VERSION ""

NS_ :

BS_:

BU_: FICM_FD Vector__XXX

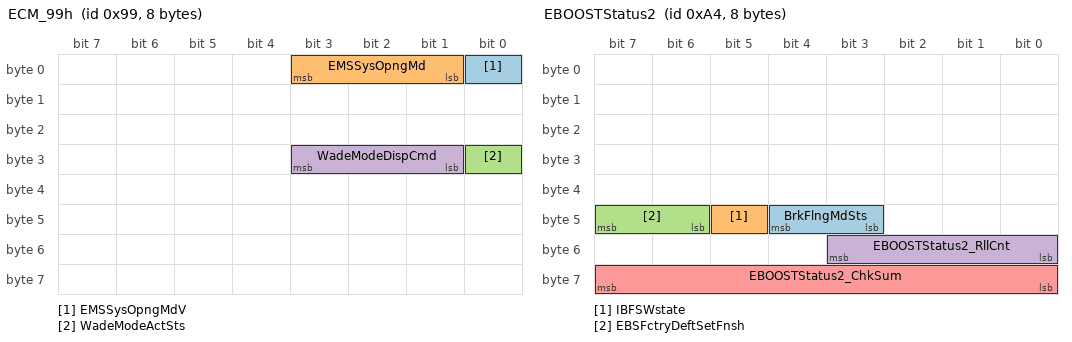
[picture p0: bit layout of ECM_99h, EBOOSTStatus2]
BO_ 153 ECM_99h: 8 Vector__XXX
 SG_ EMSSysOpngMdV : 0|1@0+ (1,0) [0|1] ""  FICM_FD
 SG_ EMSSysOpngMd : 3|3@0+ (1,0) [0|7] ""  FICM_FD
 SG_ WadeModeActSts : 24|1@0+ (1,0) [0|1] ""  FICM_FD
 SG_ WadeModeDispCmd : 27|3@0+ (1,0) [0|7] ""  FICM_FD

BO_ 164 EBOOSTStatus2: 8 Vector__XXX
 SG_ BrkFlngMdSts : 44|2@0+ (1,0) [0|3] ""  FICM_FD
 SG_ IBFSWstate : 45|1@0+ (1,0) [0|1] ""  FICM_FD
 SG_ EBSFctryDeftSetFnsh : 47|2@0+ (1,0) [0|3] ""  FICM_FD
 SG_ EBOOSTStatus2_RllCnt : 51|4@0+ (1,0) [0|15] ""  FICM_FD
 SG_ EBOOSTStatus2_ChkSum : 63|8@0+ (1,0) [0|255] ""  FICM_FD

BO_ 165 DrivenWheelPules: 16 Vector__XXX
 SG_ LDrvnWhlRotlDistPlsCtr : 23|10@0+ (1,0) [0|1023] ""  FICM_FD
 SG_ LDrvnWhlRotlDistPlsCtrV : 52|1@0+ (1,0) [0|1] ""  FICM_FD
 SG_ RDrvnWhlRotlDistPlsCtr : 87|10@0+ (1,0) [0|1023] ""  FICM_FD
 SG_ RDrvnWhlRotlDistPlsCtrV : 116|1@0+ (1,0) [0|1] ""  FICM_FD

BO_ 168 NonDrivenWheelPules: 16 Vector__XXX
 SG_ LNonDrvnWhlRotlDistPlsCtr : 23|10@0+ (1,0) [0|1023] ""  FICM_FD
 SG_ LNonDrvnWhlRotlDistPlsCtrV : 52|1@0+ (1,0) [0|1] ""  FICM_FD
 SG_ RNonDrvnWhlRotlDistPlsCtr : 87|10@0+ (1,0) [0|1023] ""  FICM_FD
 SG_ RNonDrvnWhlRotlDistPlsCtrV : 116|1@0+ (1,0) [0|1] ""  FICM_FD

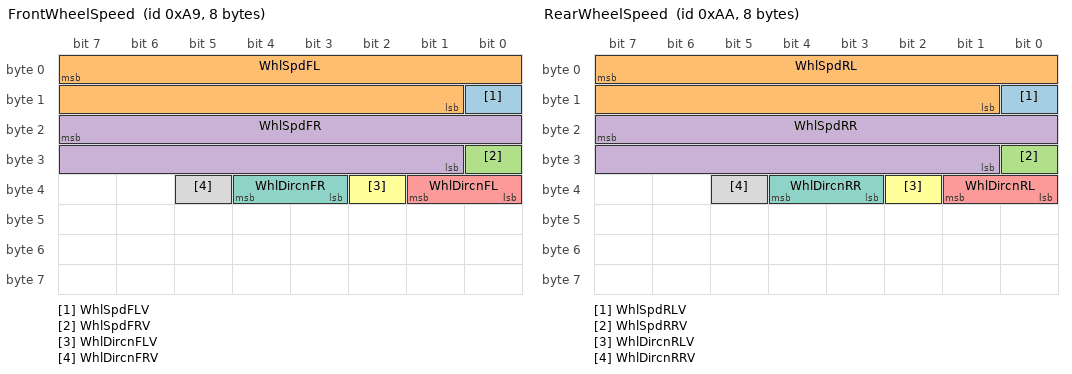
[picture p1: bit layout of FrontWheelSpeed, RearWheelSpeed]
BO_ 169 FrontWheelSpeed: 8 Vector__XXX
 SG_ WhlSpdFLV : 8|1@0+ (1,0) [0|1] ""  FICM_FD
 SG_ WhlSpdFL : 7|15@0+ (0.015625,0) [0|511.98] "km/h"  FICM_FD
 SG_ WhlSpdFRV : 24|1@0+ (1,0) [0|1] ""  FICM_FD
 SG_ WhlSpdFR : 23|15@0+ (0.015625,0) [0|511.98] "km/h"  FICM_FD
 SG_ WhlDircnFL : 33|2@0+ (1,0) [0|3] ""  FICM_FD
 SG_ WhlDircnFLV : 34|1@0+ (1,0) [0|1] ""  FICM_FD
 SG_ WhlDircnFR : 36|2@0+ (1,0) [0|3] ""  FICM_FD
 SG_ WhlDircnFRV : 37|1@0+ (1,0) [0|1] ""  FICM_FD

BO_ 170 RearWheelSpeed: 8 Vector__XXX
 SG_ WhlSpdRLV : 8|1@0+ (1,0) [0|1] ""  FICM_FD
 SG_ WhlSpdRL : 7|15@0+ (0.015625,0) [0|511.98] "km/h"  FICM_FD
 SG_ WhlSpdRRV : 24|1@0+ (1,0) [0|1] ""  FICM_FD
 SG_ WhlSpdRR : 23|15@0+ (0.015625,0) [0|511.98] "km/h"  FICM_FD
 SG_ WhlDircnRL : 33|2@0+ (1,0) [0|3] ""  FICM_FD
 SG_ WhlDircnRLV : 34|1@0+ (1,0) [0|1] ""  FICM_FD
 SG_ WhlDircnRR : 36|2@0+ (1,0) [0|3] ""  FICM_FD
 SG_ WhlDircnRRV : 37|1@0+ (1,0) [0|1] ""  FICM_FD

BO_ 337 TCCUShiftSys: 8 Vector__XXX
 SG_ TCCUSysOpngMd : 6|4@0+ (1,0) [0|15] ""  FICM_FD

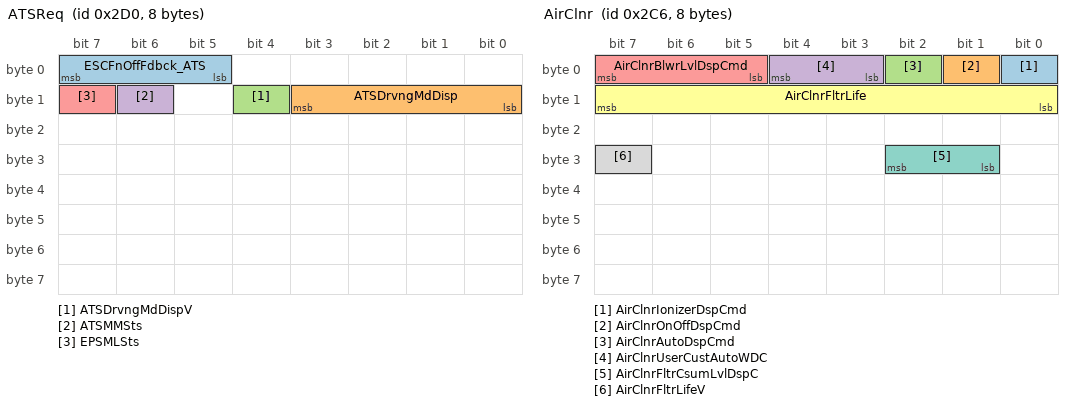
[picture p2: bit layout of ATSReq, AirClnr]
BO_ 720 ATSReq: 8 Vector__XXX
 SG_ ESCFnOffFdbck_ATS : 7|3@0+ (1,0) [0|7] ""  FICM_FD
 SG_ ATSDrvngMdDisp : 11|4@0+ (1,0) [0|15] ""  FICM_FD
 SG_ ATSDrvngMdDispV : 12|1@0+ (1,0) [0|1] ""  FICM_FD
 SG_ ATSMMSts : 14|1@0+ (1,0) [0|1] ""  FICM_FD
 SG_ EPSMLSts : 15|1@0+ (1,0) [0|1] ""  FICM_FD

BO_ 710 AirClnr: 8 Vector__XXX
 SG_ AirClnrIonizerDspCmd : 0|1@0+ (1,0) [0|1] ""  FICM_FD
 SG_ AirClnrOnOffDspCmd : 1|1@0+ (1,0) [0|1] ""  FICM_FD
 SG_ AirClnrAutoDspCmd : 2|1@0+ (1,0) [0|1] ""  FICM_FD
 SG_ AirClnrUserCustAutoWDC : 4|2@0+ (1,0) [0|3] ""  FICM_FD
 SG_ AirClnrBlwrLvlDspCmd : 7|3@0+ (1,0) [0|7] ""  FICM_FD
 SG_ AirClnrFltrLife : 15|8@0+ (3,0) [0|765] "h"  FICM_FD
 SG_ AirClnrFltrCsumLvlDspC : 26|2@0+ (1,0) [0|3] ""  FICM_FD
 SG_ AirClnrFltrLifeV : 31|1@0+ (1,0) [0|1] ""  FICM_FD

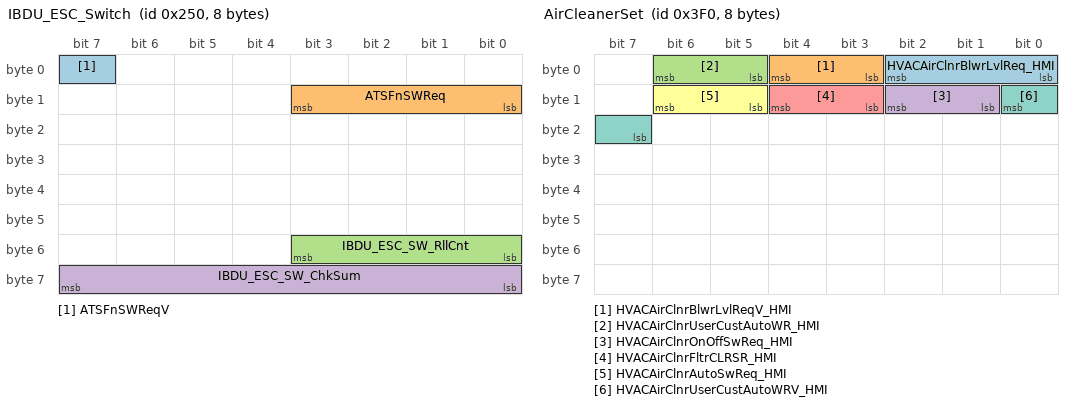
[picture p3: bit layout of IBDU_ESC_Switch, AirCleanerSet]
BO_ 592 IBDU_ESC_Switch: 8 Vector__XXX
 SG_ ATSFnSWReqV : 7|1@0+ (1,0) [0|1] ""  FICM_FD
 SG_ ATSFnSWReq : 11|4@0+ (1,0) [0|15] ""  FICM_FD
 SG_ IBDU_ESC_SW_RllCnt : 51|4@0+ (1,0) [0|15] ""  FICM_FD
 SG_ IBDU_ESC_SW_ChkSum : 63|8@0+ (1,0) [0|255] ""  FICM_FD

BO_ 1008 AirCleanerSet: 8 FICM_FD
 SG_ HVACAirClnrBlwrLvlReq_HMI : 2|3@0+ (1,0) [0|7] ""  Vector__XXX
 SG_ HVACAirClnrBlwrLvlReqV_HMI : 4|2@0+ (1,0) [0|3] ""  Vector__XXX
 SG_ HVACAirClnrUserCustAutoWR_HMI : 6|2@0+ (1,0) [0|3] ""  Vector__XXX
 SG_ HVACAirClnrOnOffSwReq_HMI : 10|2@0+ (1,0) [0|3] ""  Vector__XXX
 SG_ HVACAirClnrFltrCLRSR_HMI : 12|2@0+ (1,0) [0|3] ""  Vector__XXX
 SG_ HVACAirClnrAutoSwReq_HMI : 14|2@0+ (1,0) [0|3] ""  Vector__XXX
 SG_ HVACAirClnrUserCustAutoWRV_HMI : 8|2@0+ (1,0) [0|3] ""  Vector__XXX

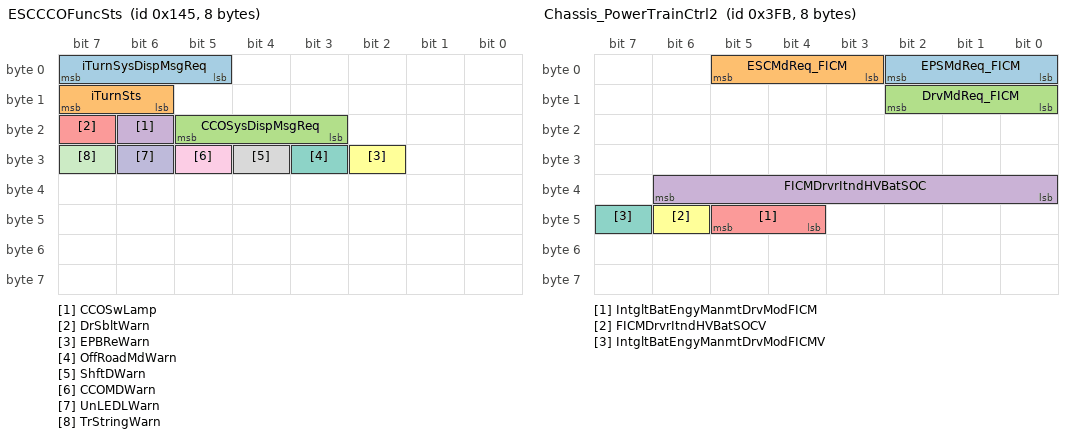
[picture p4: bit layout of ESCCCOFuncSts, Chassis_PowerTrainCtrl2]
BO_ 325 ESCCCOFuncSts: 8 Vector__XXX
 SG_ iTurnSysDispMsgReq : 7|3@0+ (1,0) [0|7] ""  FICM_FD
 SG_ iTurnSts : 15|2@0+ (1,0) [0|1] ""  FICM_FD
 SG_ CCOSysDispMsgReq : 21|3@0+ (1,0) [0|7] ""  FICM_FD
 SG_ CCOSwLamp : 22|1@0+ (1,0) [0|1] ""  FICM_FD
 SG_ DrSbltWarn : 23|1@0+ (1,0) [0|1] ""  FICM_FD
 SG_ EPBReWarn : 26|1@0+ (1,0) [0|1] ""  FICM_FD
 SG_ OffRoadMdWarn : 27|1@0+ (1,0) [0|1] ""  FICM_FD
 SG_ ShftDWarn : 28|1@0+ (1,0) [0|1] ""  FICM_FD
 SG_ CCOMDWarn : 29|1@0+ (1,0) [0|1] ""  FICM_FD
 SG_ UnLEDLWarn : 30|1@0+ (1,0) [0|1] ""  FICM_FD
 SG_ TrStringWarn : 31|1@0+ (1,0) [0|1] ""  FICM_FD

BO_ 1019 Chassis_PowerTrainCtrl2: 8 FICM_FD
 SG_ EPSMdReq_FICM : 2|3@0+ (1,0) [0|7] ""  Vector__XXX
 SG_ ESCMdReq_FICM : 5|3@0+ (1,0) [0|7] ""  Vector__XXX
 SG_ DrvMdReq_FICM : 10|3@0+ (1,0) [0|7] ""  Vector__XXX
 SG_ FICMDrvrItndHVBatSOC : 38|7@0+ (1,0) [0|100] "%"  Vector__XXX
 SG_ IntgltBatEngyManmtDrvModFICM : 45|2@0+ (1,0) [0|3] ""  Vector__XXX
 SG_ FICMDrvrItndHVBatSOCV : 46|1@0+ (1,0) [0|1] ""  Vector__XXX
 SG_ IntgltBatEngyManmtDrvModFICMV : 47|1@0+ (1,0) [0|1] ""  Vector__XXX

BO_ 1021 BatHeatOrdReq: 8 FICM_FD
 SG_ FICMHourOfBatHeat : 4|5@0+ (1,0) [0|23] ""  Vector__XXX
 SG_ FICMHeatReq : 6|2@0+ (1,0) [0|3] ""  Vector__XXX
 SG_ FICMBatHeatTmV : 7|1@0+ (1,0) [0|1] ""  Vector__XXX
 SG_ FICMMinOfBatHeat : 13|6@0+ (1,0) [0|63] ""  Vector__XXX
 SG_ FICMInnerV2LReq : 15|2@0+ (1,0) [0|3] ""  Vector__XXX
 SG_ FICMInnerV2LKeepTimeReq : 20|5@0+ (1,0) [0|31] "h"  Vector__XXX
 SG_ FuelModSw : 23|2@0+ (1,0) [0|3] ""  Vector__XXX
 SG_ FICMPeriodOfBatHeatSunday : 24|1@0+ (1,0) [0|1] ""  Vector__XXX
 SG_ FICMPeriodOfBatHeatMonday : 25|1@0+ (1,0) [0|1] ""  Vector__XXX
 SG_ FICMPeriodOfBatHeatTuesday : 26|1@0+ (1,0) [0|1] ""  Vector__XXX
 SG_ FICMPeriodOfBatHeatWednesday : 27|1@0+ (1,0) [0|1] ""  Vector__XXX
 SG_ FICMPeriodOfBatHeatThursday : 28|1@0+ (1,0) [0|1] ""  Vector__XXX
 SG_ FICMPeriodOfBatHeatFriday : 29|1@0+ (1,0) [0|1] ""  Vector__XXX
 SG_ FICMPeriodOfBatHeatSaturday : 30|1@0+ (1,0) [0|1] ""  Vector__XXX
 SG_ FICMPeriodOfBatHeatRepeat : 31|1@0+ (1,0) [0|1] ""  Vector__XXX
 SG_ FICMHourOfBatHeat1 : 36|5@0+ (1,0) [0|23] ""  Vector__XXX
 SG_ FICMHeatReq1 : 38|2@0+ (1,0) [0|3] ""  Vector__XXX
 SG_ FICMBatHeatTmV1 : 39|1@0+ (1,0) [0|1] ""  Vector__XXX
 SG_ FICMMinOfBatHeat1 : 45|6@0+ (1,0) [0|63] ""  Vector__XXX
 SG_ EnStrtRequest_V2L : 47|2@0+ (1,0) [0|3] ""  Vector__XXX
 SG_ FICMV2XSpSOCReqExt : 54|7@0+ (1,0) [0|100] "%"  Vector__XXX
 SG_ FICMPeriodOfBatHeatSunday1 : 56|1@0+ (1,0) [0|1] ""  Vector__XXX
 SG_ FICMPeriodOfBatHeatMonday1 : 57|1@0+ (1,0) [0|1] ""  Vector__XXX
 SG_ FICMPeriodOfBatHeatTuesday1 : 58|1@0+ (1,0) [0|1] ""  Vector__XXX
 SG_ FICMPeriodOfBatHeatWednesday1 : 59|1@0+ (1,0) [0|1] ""  Vector__XXX
 SG_ FICMPeriodOfBatHeatThursday1 : 60|1@0+ (1,0) [0|1] ""  Vector__XXX
 SG_ FICMPeriodOfBatHeatFriday1 : 61|1@0+ (1,0) [0|1] ""  Vector__XXX
 SG_ FICMPeriodOfBatHeatSaturday1 : 62|1@0+ (1,0) [0|1] ""  Vector__XXX
 SG_ FICMPeriodOfBatHeatRepeat1 : 63|1@0+ (1,0) [0|1] ""  Vector__XXX

BO_ 1022 BatHeatOrdStatus: 8 Vector__XXX
 SG_ ICGMHourOfBatHeat : 4|5@0+ (1,0) [0|31] ""  FICM_FD
 SG_ BatHeatOrdStatus : 5|1@0+ (1,0) [0|1] ""  FICM_FD
 SG_ ICGMMinOfBatHeat : 13|6@0+ (1,0) [0|63] ""  FICM_FD
 SG_ ICGMPeriodOfBatHeatSunday : 24|1@0+ (1,0) [0|1] ""  FICM_FD
 SG_ ICGMPeriodOfBatHeatMonday : 25|1@0+ (1,0) [0|1] ""  FICM_FD
 SG_ ICGMPeriodOfBatHeatTuesday : 26|1@0+ (1,0) [0|1] ""  FICM_FD
 SG_ ICGMPeriodOfBatHeatWednesday : 27|1@0+ (1,0) [0|1] ""  FICM_FD
 SG_ ICGMPeriodOfBatHeatThursday : 28|1@0+ (1,0) [0|1] ""  FICM_FD
 SG_ ICGMPeriodOfBatHeatFriday : 29|1@0+ (1,0) [0|1] ""  FICM_FD
 SG_ ICGMPeriodOfBatHeatSaturday : 30|1@0+ (1,0) [0|1] ""  FICM_FD
 SG_ ICGMPeriodOfBatHeatRepeat : 31|1@0+ (1,0) [0|1] ""  FICM_FD
 SG_ ICGMHourOfBatHeat1 : 36|5@0+ (1,0) [0|31] ""  FICM_FD
 SG_ BatHeatOrdStatus1 : 37|1@0+ (1,0) [0|1] ""  FICM_FD
 SG_ ICGMMinOfBatHeat1 : 45|6@0+ (1,0) [0|63] ""  FICM_FD
 SG_ ICGMPeriodOfBatHeatSunday1 : 56|1@0+ (1,0) [0|1] ""  FICM_FD
 SG_ ICGMPeriodOfBatHeatMonday1 : 57|1@0+ (1,0) [0|1] ""  FICM_FD
 SG_ ICGMPeriodOfBatHeatTuesday1 : 58|1@0+ (1,0) [0|1] ""  FICM_FD
 SG_ ICGMPeriodOfBatHeatWednesday1 : 59|1@0+ (1,0) [0|1] ""  FICM_FD
 SG_ ICGMPeriodOfBatHeatThursday1 : 60|1@0+ (1,0) [0|1] ""  FICM_FD
 SG_ ICGMPeriodOfBatHeatFriday1 : 61|1@0+ (1,0) [0|1] ""  FICM_FD
 SG_ ICGMPeriodOfBatHeatSaturday1 : 62|1@0+ (1,0) [0|1] ""  FICM_FD
 SG_ ICGMPeriodOfBatHeatRepeat1 : 63|1@0+ (1,0) [0|1] ""  FICM_FD

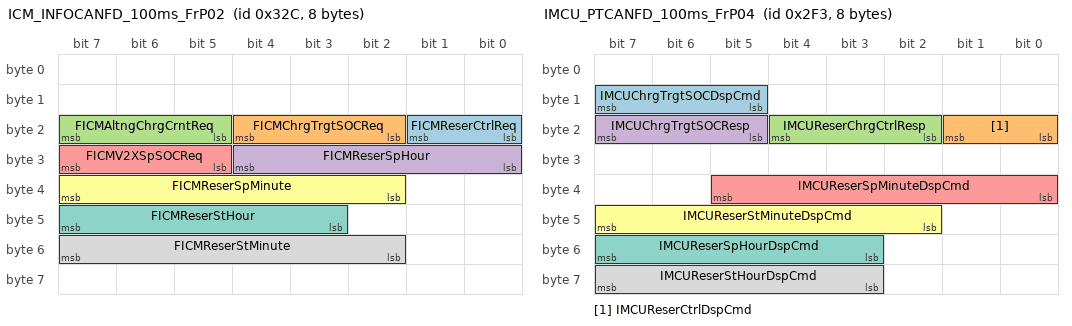
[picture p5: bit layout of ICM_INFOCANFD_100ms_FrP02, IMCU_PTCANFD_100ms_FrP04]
BO_ 812 ICM_INFOCANFD_100ms_FrP02: 8 FICM_FD
 SG_ FICMReserCtrlReq : 17|2@0+ (1,0) [0|3] ""  Vector__XXX
 SG_ FICMChrgTrgtSOCReq : 20|3@0+ (1,0) [0|7] ""  Vector__XXX
 SG_ FICMAltngChrgCrntReq : 23|3@0+ (1,0) [0|7] ""  Vector__XXX
 SG_ FICMReserSpHour : 28|5@0+ (1,0) [0|31] ""  Vector__XXX
 SG_ FICMV2XSpSOCReq : 31|3@0+ (1,0) [0|7] ""  Vector__XXX
 SG_ FICMReserSpMinute : 39|6@0+ (1,0) [0|63] ""  Vector__XXX
 SG_ FICMReserStHour : 47|5@0+ (1,0) [0|31] ""  Vector__XXX
 SG_ FICMReserStMinute : 55|6@0+ (1,0) [0|63] ""  Vector__XXX

BO_ 704 IMCU_PTCANFD_50ms_FrP01: 8 Vector__XXX
 SG_ IMCUBaaSOvduDay : 7|16@0+ (1,0) [0|65535] "NULL"  FICM_FD
 SG_ BaaSBatIlglAlrm : 18|1@0+ (1,0) [0|1] "NULL"  FICM_FD
 SG_ IMCUAlrmDspForBaaS : 23|4@0+ (1,0) [0|15] "NULL"  FICM_FD

BO_ 755 IMCU_PTCANFD_100ms_FrP04: 8 Vector__XXX
 SG_ IMCUChrgTrgtSOCDspCmd : 15|3@0+ (1,0) [0|7] "NULL"  FICM_FD
 SG_ IMCUReserCtrlDspCmd : 17|2@0+ (1,0) [0|3] "NULL"  FICM_FD
 SG_ IMCUReserChrgCtrlResp : 20|3@0+ (1,0) [0|7] "NULL"  FICM_FD
 SG_ IMCUChrgTrgtSOCResp : 23|3@0+ (1,0) [0|7] "NULL"  FICM_FD
 SG_ IMCUReserSpMinuteDspCmd : 37|6@0+ (1,0) [0|59] "NULL"  FICM_FD
 SG_ IMCUReserStMinuteDspCmd : 47|6@0+ (1,0) [0|59] "NULL"  FICM_FD
 SG_ IMCUReserSpHourDspCmd : 55|5@0+ (1,0) [0|23] "NULL"  FICM_FD
 SG_ IMCUReserStHourDspCmd : 63|5@0+ (1,0) [0|23] "NULL"  FICM_FD

BO_ 777 CCU_100ms_PDU02: 8 Vector__XXX
 SG_ CCUOffBdChrgrPlugOnV : 62|1@0+ (1,0) [0|1] "NULL"  FICM_FD
 SG_ CCUOffBdChrgrPlugOn : 48|2@0+ (1,0) [0|3] "NULL"  FICM_FD

BO_ 805 IMCU_PTCANFD_100ms_FrP02: 16 Vector__XXX
 SG_ IMCUDschrgngEstdElecRngV : 27|1@0+ (1,0) [0|1] "NULL"  FICM_FD
 SG_ IMCUDschrgngEstdElecRng : 23|12@0+ (1,0) [0|4095] "kM"  FICM_FD
 SG_ IMCUChrgSttnMchngStaResp : 81|2@0+ (1,0) [0|3] "NULL"  FICM_FD
 SG_ IMCUAltngChrgCrntResp : 84|3@0+ (1,0) [0|7] "NULL"  FICM_FD
 SG_ IMCUAltngChrgCrntDspCmd : 87|3@0+ (1,0) [0|7] "NULL"  FICM_FD
 SG_ IMCUDschrgTrgtSOCDspCmd : 95|3@0+ (1,0) [0|7] "NULL"  FICM_FD

BO_ 884 IMCU_PTCANFD_100ms_FrP19: 8 Vector__XXX
 SG_ ESSSwapOpDsp : 27|4@0+ (1,0) [0|15] "NULL"  FICM_FD

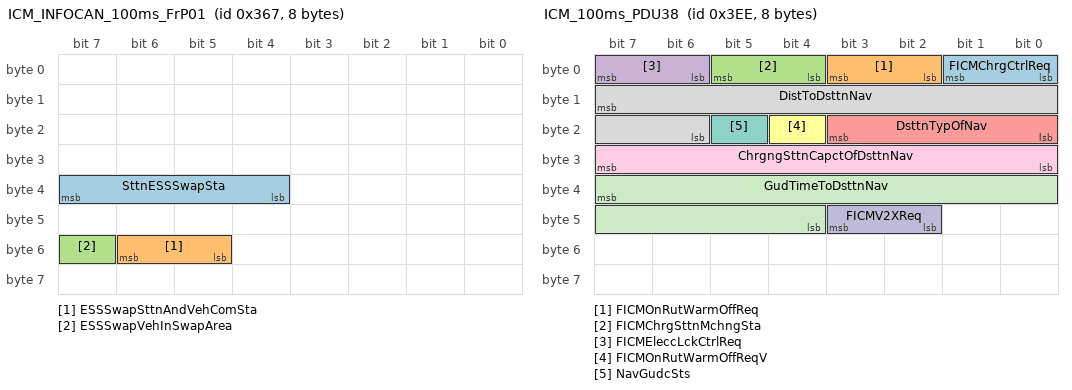
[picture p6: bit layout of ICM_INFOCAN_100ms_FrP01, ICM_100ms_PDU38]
BO_ 871 ICM_INFOCAN_100ms_FrP01: 8 Vector__XXX
 SG_ SttnESSSwapSta : 39|4@0+ (1,0) [0|15] "NULL"  FICM_FD
 SG_ ESSSwapSttnAndVehComSta : 54|2@0+ (1,0) [0|3] "NULL"  FICM_FD
 SG_ ESSSwapVehInSwapArea : 55|1@0+ (1,0) [0|1] "NULL"  FICM_FD

BO_ 1006 ICM_100ms_PDU38: 8 FICM_FD
 SG_ FICMChrgCtrlReq : 1|2@0+ (1,0) [0|3] ""  Vector__XXX
 SG_ FICMOnRutWarmOffReq : 3|2@0+ (1,0) [0|3] ""  Vector__XXX
 SG_ FICMChrgSttnMchngSta : 5|2@0+ (1,0) [0|3] ""  Vector__XXX
 SG_ FICMEleccLckCtrlReq : 7|2@0+ (1,0) [0|3] ""  Vector__XXX
 SG_ DsttnTypOfNav : 19|4@0+ (1,0) [0|2] ""  Vector__XXX
 SG_ FICMOnRutWarmOffReqV : 20|1@0+ (1,0) [0|1] ""  Vector__XXX
 SG_ NavGudcSts : 21|1@0+ (1,0) [0|1] ""  Vector__XXX
 SG_ DistToDsttnNav : 15|10@0+ (0.1,0) [0|102.3] "km"  Vector__XXX
 SG_ ChrgngSttnCapctOfDsttnNav : 31|8@0+ (4,0) [0|1020] "kW"  Vector__XXX
 SG_ FICMV2XReq : 43|2@0+ (1,0) [0|3] "NULL"  Vector__XXX
 SG_ GudTimeToDsttnNav : 39|12@0+ (1,0) [0|4095] "Min"  Vector__XXX

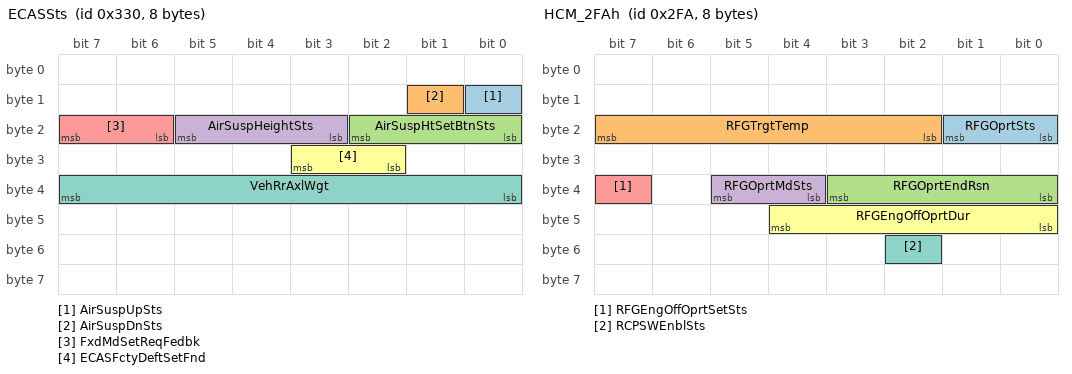
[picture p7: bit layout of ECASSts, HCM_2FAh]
BO_ 816 ECASSts: 8 Vector__XXX
 SG_ AirSuspUpSts : 8|1@0+ (1,0) [0|1] ""  FICM_FD
 SG_ AirSuspDnSts : 9|1@0+ (1,0) [0|1] ""  FICM_FD
 SG_ AirSuspHtSetBtnSts : 18|3@0+ (1,0) [0|7] ""  FICM_FD
 SG_ AirSuspHeightSts : 21|3@0+ (1,0) [0|7] ""  FICM_FD
 SG_ FxdMdSetReqFedbk : 23|2@0+ (1,0) [0|3] ""  FICM_FD
 SG_ ECASFctyDeftSetFnd : 27|2@0+ (1,0) [0|3] ""  FICM_FD
 SG_ VehRrAxlWgt : 39|8@0+ (7,800) [800|2585] "kg"  FICM_FD

BO_ 762 HCM_2FAh: 8 Vector__XXX
 SG_ RFGOprtSts : 17|2@0+ (1,0) [0|3] ""  FICM_FD
 SG_ RFGTrgtTemp : 23|6@0+ (1,0) [0|63] "℃"  FICM_FD
 SG_ RFGOprtEndRsn : 35|4@0+ (1,0) [0|15] ""  FICM_FD
 SG_ RFGOprtMdSts : 37|2@0+ (1,0) [0|3] ""  FICM_FD
 SG_ RFGEngOffOprtSetSts : 39|1@0+ (1,0) [0|1] ""  FICM_FD
 SG_ RFGEngOffOprtDur : 44|5@0+ (1,0) [0|31] "h"  FICM_FD
 SG_ RCPSWEnblSts : 50|1@0+ (1,0) [0|1] ""  FICM_FD

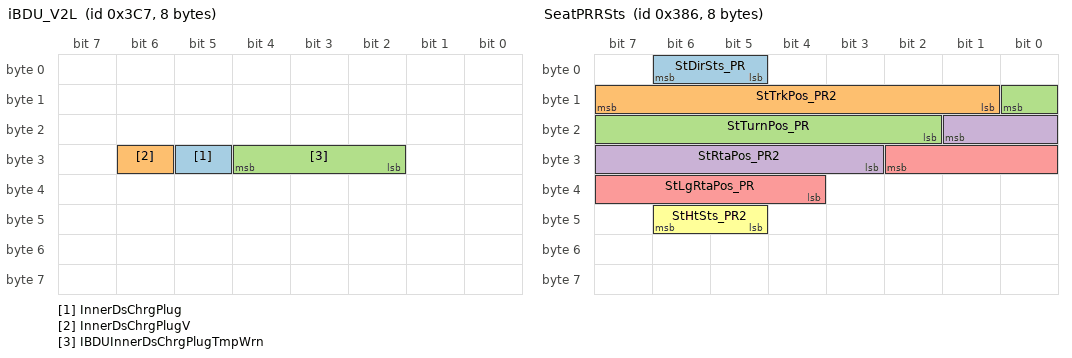
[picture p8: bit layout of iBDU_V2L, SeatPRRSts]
BO_ 967 iBDU_V2L: 8 Vector__XXX
 SG_ InnerDsChrgPlug : 29|1@0+ (1,0) [0|1] ""  FICM_FD
 SG_ InnerDsChrgPlugV : 30|1@0+ (1,0) [0|1] ""  FICM_FD
 SG_ IBDUInnerDsChrgPlugTmpWrn : 28|3@0+ (1,0) [0|7] ""  FICM_FD

BO_ 994 TyrePrs_Temp2: 8 Vector__XXX
 SG_ TirePrs_RLOS : 23|8@0+ (2.75,0) [0|700] "kpa"  FICM_FD
 SG_ TirePrs_RROS : 31|8@0+ (2.75,0) [0|700] "kpa"  FICM_FD
 SG_ TireTmp_RLOS : 55|8@0+ (1,-60) [-60|194] ""  FICM_FD
 SG_ TireTmp_RROS : 63|8@0+ (1,-60) [-60|194] ""  FICM_FD

BO_ 902 SeatPRRSts: 8 Vector__XXX
 SG_ StDirSts_PR : 6|2@0+ (1,0) [0|3] ""  FICM_FD
 SG_ StTrkPos_PR2 : 15|7@0+ (1,0) [0|127] "%"  FICM_FD
 SG_ StTurnPos_PR : 8|7@0+ (1,0) [0|127] "%"  FICM_FD
 SG_ StRtaPos_PR2 : 17|7@0+ (1,0) [0|127] "%"  FICM_FD
 SG_ StLgRtaPos_PR : 26|7@0+ (1,0) [0|127] "%"  FICM_FD
 SG_ StHtSts_PR2 : 46|2@0+ (1,0) [0|3] ""  FICM_FD

BO_ 903 AllSeatAdjust4: 8 Vector__XXX
 SG_ StRtaRmndReq_PR : 2|3@0+ (1,0) [0|7] ""  FICM_FD

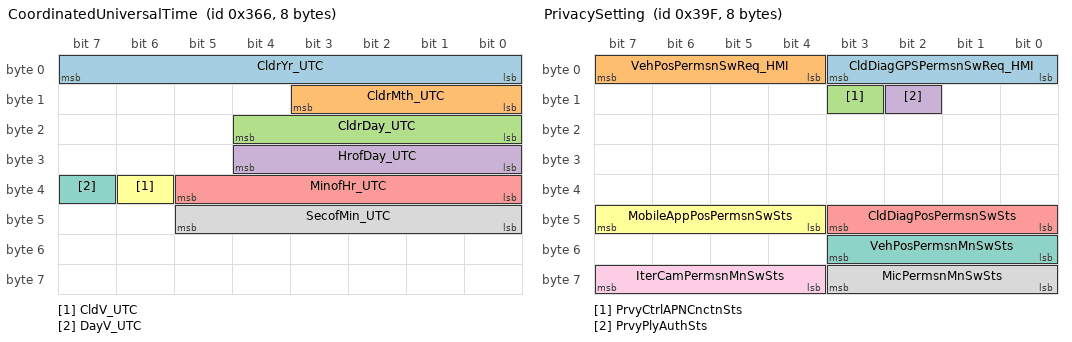
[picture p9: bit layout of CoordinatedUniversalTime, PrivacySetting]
BO_ 870 CoordinatedUniversalTime: 8 Vector__XXX
 SG_ CldrYr_UTC : 7|8@0+ (1,2000) [2000|2255] ""  FICM_FD
 SG_ CldrMth_UTC : 11|4@0+ (1,0) [0|12] ""  FICM_FD
 SG_ CldrDay_UTC : 20|5@0+ (1,0) [0|31] ""  FICM_FD
 SG_ HrofDay_UTC : 28|5@0+ (1,0) [0|23] ""  FICM_FD
 SG_ MinofHr_UTC : 37|6@0+ (1,0) [0|63] ""  FICM_FD
 SG_ CldV_UTC : 38|1@0+ (1,0) [0|1] ""  FICM_FD
 SG_ DayV_UTC : 39|1@0+ (1,0) [0|1] ""  FICM_FD
 SG_ SecofMin_UTC : 45|6@0+ (1,0) [0|63] ""  FICM_FD

BO_ 927 PrivacySetting: 8 FICM_FD
 SG_ CldDiagGPSPermsnSwReq_HMI : 3|4@0+ (1,0) [0|15] ""  Vector__XXX
 SG_ VehPosPermsnSwReq_HMI : 7|4@0+ (1,0) [0|15] ""  Vector__XXX
 SG_ PrvyCtrlAPNCnctnSts : 11|1@0+ (1,0) [0|1] ""  Vector__XXX
 SG_ PrvyPlyAuthSts : 10|1@0+ (1,0) [0|1] ""  Vector__XXX
 SG_ CldDiagPosPermsnSwSts : 43|4@0+ (1,0) [0|15] ""  Vector__XXX
 SG_ MobileAppPosPermsnSwSts : 47|4@0+ (1,0) [0|15] ""  Vector__XXX
 SG_ VehPosPermsnMnSwSts : 51|4@0+ (1,0) [0|15] ""  Vector__XXX
 SG_ MicPermsnMnSwSts : 59|4@0+ (1,0) [0|15] ""  Vector__XXX
 SG_ IterCamPermsnMnSwSts : 63|4@0+ (1,0) [0|15] ""  Vector__XXX

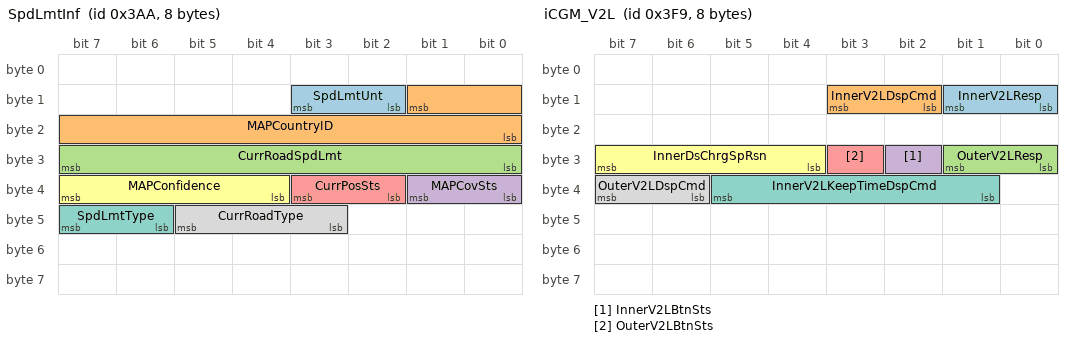
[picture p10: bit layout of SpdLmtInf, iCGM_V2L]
BO_ 938 SpdLmtInf: 8 FICM_FD
 SG_ SpdLmtUnt : 11|2@0+ (1,0) [0|3] ""  Vector__XXX
 SG_ MAPCountryID : 9|10@0+ (1,0) [0|1023] ""  Vector__XXX
 SG_ CurrRoadSpdLmt : 31|8@0+ (1,0) [0|255] ""  Vector__XXX
 SG_ MAPCovSts : 33|2@0+ (1,0) [0|3] ""  Vector__XXX
 SG_ CurrPosSts : 35|2@0+ (1,0) [0|3] ""  Vector__XXX
 SG_ MAPConfidence : 39|4@0+ (1,0) [0|15] ""  Vector__XXX
 SG_ SpdLmtType : 47|2@0+ (1,0) [0|3] ""  Vector__XXX
 SG_ CurrRoadType : 45|3@0+ (1,0) [0|7] ""  Vector__XXX

BO_ 939 SeatCtrl_DR_HMI: 32 FICM_FD
 SG_ StTrkPosReq_DR_HMI : 54|7@0+ (1,0) [0|127] ""  Vector__XXX
 SG_ StRtaPosReq_DR_HMI : 62|7@0+ (1,0) [0|127] ""  Vector__XXX

BO_ 1017 iCGM_V2L: 8 Vector__XXX
 SG_ InnerV2LResp : 9|2@0+ (1,0) [0|3] ""  FICM_FD
 SG_ InnerV2LDspCmd : 11|2@0+ (1,0) [0|3] ""  FICM_FD
 SG_ OuterV2LResp : 25|2@0+ (1,0) [0|3] ""  FICM_FD
 SG_ InnerV2LBtnSts : 26|1@0+ (1,0) [0|1] ""  FICM_FD
 SG_ OuterV2LBtnSts : 27|1@0+ (1,0) [0|1] ""  FICM_FD
 SG_ InnerDsChrgSpRsn : 31|4@0+ (1,0) [0|15] ""  FICM_FD
 SG_ InnerV2LKeepTimeDspCmd : 37|5@0+ (1,0) [0|31] "h"  FICM_FD
 SG_ OuterV2LDspCmd : 39|2@0+ (1,0) [0|3] ""  FICM_FD

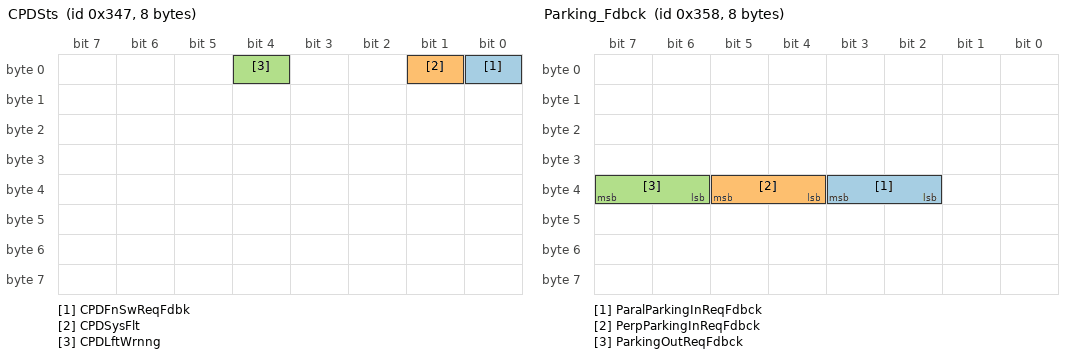
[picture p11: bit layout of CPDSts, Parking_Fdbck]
BO_ 839 CPDSts: 8 Vector__XXX
 SG_ CPDFnSwReqFdbk : 0|1@0+ (1,0) [0|1] ""  FICM_FD
 SG_ CPDSysFlt : 1|1@0+ (1,0) [0|1] ""  FICM_FD
 SG_ CPDLftWrnng : 4|1@0+ (1,0) [0|1] ""  FICM_FD

BO_ 856 Parking_Fdbck: 8 Vector__XXX
 SG_ ParalParkingInReqFdbck : 35|2@0+ (1,0) [0|3] ""  FICM_FD
 SG_ PerpParkingInReqFdbck : 37|2@0+ (1,0) [0|3] ""  FICM_FD
 SG_ ParkingOutReqFdbck : 39|2@0+ (1,0) [0|3] ""  FICM_FD

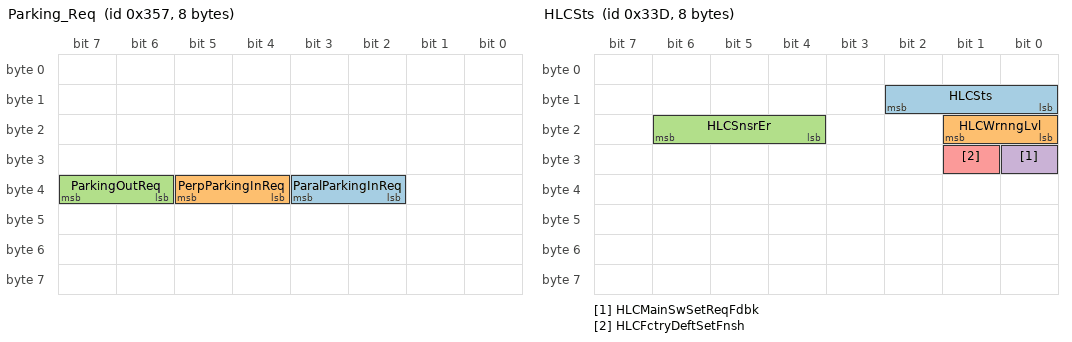
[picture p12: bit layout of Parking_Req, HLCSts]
BO_ 855 Parking_Req: 8 FICM_FD
 SG_ ParalParkingInReq : 35|2@0+ (1,0) [0|3] ""  Vector__XXX
 SG_ PerpParkingInReq : 37|2@0+ (1,0) [0|3] ""  Vector__XXX
 SG_ ParkingOutReq : 39|2@0+ (1,0) [0|3] ""  Vector__XXX

BO_ 829 HLCSts: 8 Vector__XXX
 SG_ HLCSts : 10|3@0+ (1,0) [0|7] ""  FICM_FD
 SG_ HLCWrnngLvl : 17|2@0+ (1,0) [0|3] ""  FICM_FD
 SG_ HLCSnsrEr : 22|3@0+ (1,0) [0|7] ""  FICM_FD
 SG_ HLCMainSwSetReqFdbk : 24|1@0+ (1,0) [0|1] ""  FICM_FD
 SG_ HLCFctryDeftSetFnsh : 25|1@0+ (1,0) [0|1] ""  FICM_FD

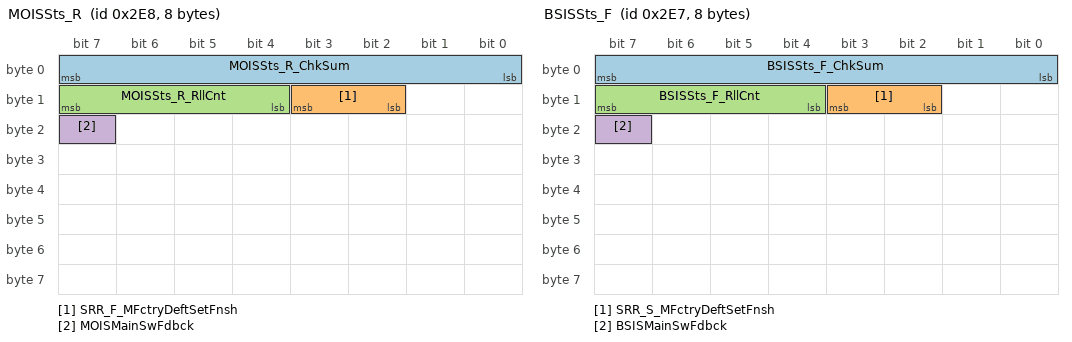
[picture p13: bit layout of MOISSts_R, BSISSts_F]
BO_ 744 MOISSts_R: 8 Vector__XXX
 SG_ MOISSts_R_ChkSum : 7|8@0+ (1,0) [0|255] ""  FICM_FD
 SG_ SRR_F_MFctryDeftSetFnsh : 11|2@0+ (1,0) [0|3] ""  FICM_FD
 SG_ MOISSts_R_RllCnt : 15|4@0+ (1,0) [0|15] ""  FICM_FD
 SG_ MOISMainSwFdbck : 23|1@0+ (1,0) [0|1] ""  FICM_FD

BO_ 743 BSISSts_F: 8 Vector__XXX
 SG_ BSISSts_F_ChkSum : 7|8@0+ (1,0) [0|255] ""  FICM_FD
 SG_ SRR_S_MFctryDeftSetFnsh : 11|2@0+ (1,0) [0|3] ""  FICM_FD
 SG_ BSISSts_F_RllCnt : 15|4@0+ (1,0) [0|15] ""  FICM_FD
 SG_ BSISMainSwFdbck : 23|1@0+ (1,0) [0|1] ""  FICM_FD

BO_ 1376 LDU_Lds_560h: 8 Vector__XXX
 SG_ DcrtvLmpSwSts : 28|1@0+ (1,0) [0|1] ""  FICM_FD

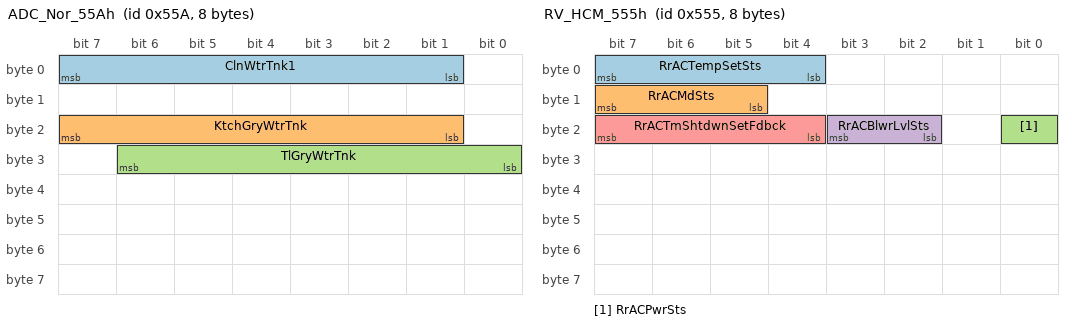
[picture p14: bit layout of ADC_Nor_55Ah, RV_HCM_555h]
BO_ 1370 ADC_Nor_55Ah: 8 Vector__XXX
 SG_ ClnWtrTnk1 : 7|7@0+ (1,0) [0|100] "%"  FICM_FD
 SG_ KtchGryWtrTnk : 23|7@0+ (1,0) [0|100] "%"  FICM_FD
 SG_ TlGryWtrTnk : 30|7@0+ (1,0) [0|100] "%"  FICM_FD

BO_ 1365 RV_HCM_555h: 8 Vector__XXX
 SG_ RrACTempSetSts : 7|4@0+ (1,17) [17|30] "℃"  FICM_FD
 SG_ RrACMdSts : 15|3@0+ (1,0) [0|7] ""  FICM_FD
 SG_ RrACPwrSts : 16|1@0+ (1,0) [0|1] ""  FICM_FD
 SG_ RrACBlwrLvlSts : 19|2@0+ (1,0) [0|3] ""  FICM_FD
 SG_ RrACTmShtdwnSetFdbck : 23|4@0+ (1,0) [0|15] ""  FICM_FD

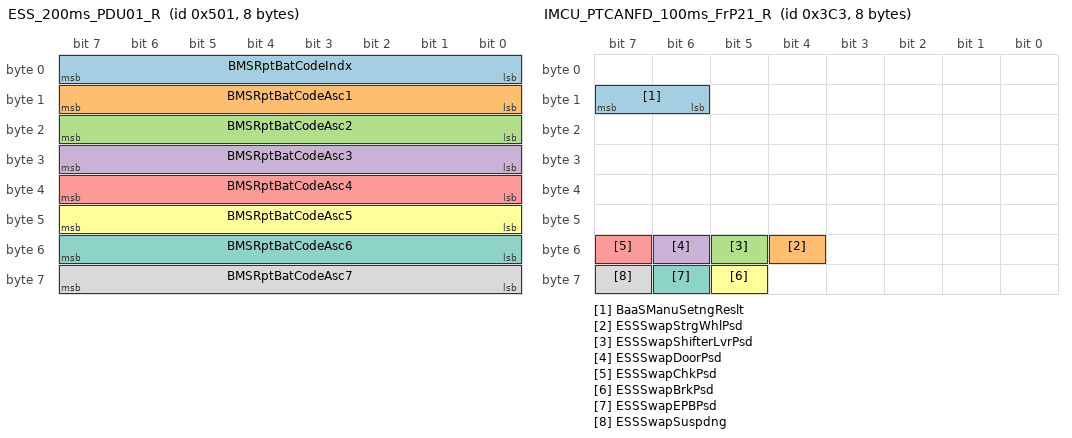
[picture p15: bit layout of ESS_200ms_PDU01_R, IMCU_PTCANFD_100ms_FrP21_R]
BO_ 1281 ESS_200ms_PDU01_R: 8 Vector__XXX
 SG_ BMSRptBatCodeIndx : 7|8@0+ (1,0) [0|255] "NULL"  FICM_FD
 SG_ BMSRptBatCodeAsc1 : 15|8@0+ (1,0) [0|255] "NULL"  FICM_FD
 SG_ BMSRptBatCodeAsc2 : 23|8@0+ (1,0) [0|255] "NULL"  FICM_FD
 SG_ BMSRptBatCodeAsc3 : 31|8@0+ (1,0) [0|255] "NULL"  FICM_FD
 SG_ BMSRptBatCodeAsc4 : 39|8@0+ (1,0) [0|255] "NULL"  FICM_FD
 SG_ BMSRptBatCodeAsc5 : 47|8@0+ (1,0) [0|255] "NULL"  FICM_FD
 SG_ BMSRptBatCodeAsc6 : 55|8@0+ (1,0) [0|255] "NULL"  FICM_FD
 SG_ BMSRptBatCodeAsc7 : 63|8@0+ (1,0) [0|255] "NULL"  FICM_FD

BO_ 1354 ICM_INFOCANFD_1000ms_FrP01: 8 Vector__XXX
 SG_ ESSSwapWaitNum : 7|8@0+ (1,0) [0|255] ""  FICM_FD
 SG_ ESSSwapWaitNumV : 15|1@0+ (1,0) [0|1] ""  FICM_FD

BO_ 963 IMCU_PTCANFD_100ms_FrP21_R: 8 Vector__XXX
 SG_ BaaSManuSetngReslt : 15|2@0+ (1,0) [0|3] ""  FICM_FD
 SG_ ESSSwapStrgWhlPsd : 52|1@0+ (1,0) [0|1] ""  FICM_FD
 SG_ ESSSwapShifterLvrPsd : 53|1@0+ (1,0) [0|1] ""  FICM_FD
 SG_ ESSSwapDoorPsd : 54|1@0+ (1,0) [0|1] ""  FICM_FD
 SG_ ESSSwapChkPsd : 55|1@0+ (1,0) [0|1] ""  FICM_FD
 SG_ ESSSwapBrkPsd : 61|1@0+ (1,0) [0|1] ""  FICM_FD
 SG_ ESSSwapEPBPsd : 62|1@0+ (1,0) [0|1] ""  FICM_FD
 SG_ ESSSwapSuspdng : 63|1@0+ (1,0) [0|1] ""  FICM_FD

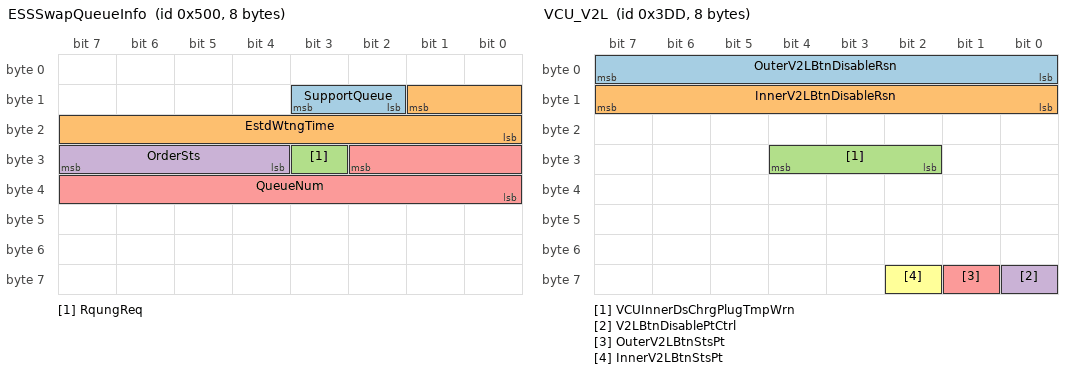
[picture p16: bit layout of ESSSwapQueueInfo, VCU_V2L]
BO_ 1280 ESSSwapQueueInfo: 8 Vector__XXX
 SG_ SupportQueue : 11|2@0+ (1,0) [0|3] ""  FICM_FD
 SG_ EstdWtngTime : 9|10@0+ (1,0) [0|1023] "min"  FICM_FD
 SG_ RqungReq : 27|1@0+ (1,0) [0|1] ""  FICM_FD
 SG_ OrderSts : 31|4@0+ (1,0) [0|15] ""  FICM_FD
 SG_ QueueNum : 26|11@0+ (1,0) [0|2047] "num"  FICM_FD

BO_ 989 VCU_V2L: 8 Vector__XXX
 SG_ OuterV2LBtnDisableRsn : 7|8@0+ (1,0) [0|255] ""  FICM_FD
 SG_ InnerV2LBtnDisableRsn : 15|8@0+ (1,0) [0|255] ""  FICM_FD
 SG_ VCUInnerDsChrgPlugTmpWrn : 28|3@0+ (1,0) [0|7] ""  FICM_FD
 SG_ V2LBtnDisablePtCtrl : 56|1@0+ (1,0) [0|1] ""  FICM_FD
 SG_ OuterV2LBtnStsPt : 57|1@0+ (1,0) [0|1] ""  FICM_FD
 SG_ InnerV2LBtnStsPt : 58|1@0+ (1,0) [0|1] ""  FICM_FD

BO_ 815 ECASSts2: 32 Vector__XXX
 SG_ Easy2LoadSetReqFedbk : 57|2@0+ (1,0) [0|3] ""  FICM_FD
 SG_ TowMdSetReqFedbk : 59|2@0+ (1,0) [0|3] ""  FICM_FD
 SG_ CampMdSetReqFedbk : 61|2@0+ (1,0) [0|3] ""  FICM_FD
 SG_ ECASWelcomeSts : 63|2@0+ (1,0) [0|3] ""  FICM_FD
 SG_ AirSuspTxtMsg2FICM : 92|5@0+ (1,0) [0|31] ""  FICM_FD
 SG_ AirSuspHeightSts2IPK : 95|3@0+ (1,0) [0|7] ""  FICM_FD
 SG_ OnBdScaTxtMsg2FICM : 99|4@0+ (1,0) [0|15] ""  FICM_FD
 SG_ AirSuspTxtMsg2IPK : 103|4@0+ (1,0) [0|15] ""  FICM_FD
 SG_ PayloadPct : 111|8@0+ (0.4,0) [0|100] "%"  FICM_FD
 SG_ CurrPayload : 119|11@0+ (1,0) [0|2047] "kg"  FICM_FD
 SG_ ECASHirBtnSts : 124|1@0+ (1,0) [0|1] ""  FICM_FD
 SG_ ECASHiBtnSts : 123|1@0+ (1,0) [0|1] ""  FICM_FD
 SG_ MaxPayload : 122|11@0+ (1,0) [0|2047] "kg"  FICM_FD
 SG_ ECASStdBtnSts : 139|1@0+ (1,0) [0|1] ""  FICM_FD
 SG_ ECASLoBtnSts : 140|1@0+ (1,0) [0|1] ""  FICM_FD
 SG_ ECASLowrBtnSts : 141|1@0+ (1,0) [0|1] ""  FICM_FD
 SG_ OnBdScaLoadUpdSts : 142|1@0+ (1,0) [0|1] ""  FICM_FD
 SG_ CurrPayloadDispEna : 143|1@0+ (1,0) [0|1] ""  FICM_FD

BO_ 620 SteeringPositionSts: 16 Vector__XXX
 SG_ EASCAdjReqFedbk : 9|2@0+ (1,0) [0|3] ""  FICM_FD
 SG_ EASCPosnSaveFedbk : 10|1@0+ (1,0) [0|1] ""  FICM_FD
 SG_ EASCPosnRecFedbk : 11|1@0+ (1,0) [0|1] ""  FICM_FD
 SG_ EASCFctyDeftSetFnd : 47|2@0+ (1,0) [0|3] ""  FICM_FD
 SG_ EASCErrSts : 39|2@0+ (1,0) [0|3] ""  FICM_FD

BO_ 825 BodySts3: 32 Vector__XXX
 SG_ HoodLockSts : 9|2@0+ (1,0) [0|3] ""  FICM_FD
 SG_ HoodOprtSts : 11|2@0+ (1,0) [0|3] ""  FICM_FD
 SG_ HoodOpnPos : 22|7@0+ (1,0) [0|127] ""  FICM_FD
 SG_ HoodOprtMdSts : 25|2@0+ (1,0) [0|3] ""  FICM_FD
 SG_ HoodPrkPosSetSts : 28|3@0+ (1,0) [0|7] ""  FICM_FD
 SG_ HoodBuzReq : 31|3@0+ (1,0) [0|7] ""  FICM_FD
 SG_ HoodAbsAlrm : 33|2@0+ (1,0) [0|3] ""  FICM_FD
 SG_ HoodBuzSetSts : 35|2@0+ (1,0) [0|3] ""  FICM_FD
 SG_ DrAjr_TnovrEdGt : 38|1@0+ (1,0) [0|1] ""  FICM_FD
 SG_ HoodCtrlBtnSts : 39|1@0+ (1,0) [0|1] ""  FICM_FD

BO_ 831 BodyCtrl3: 32 FICM_FD
 SG_ HoodPrkPosReq : 22|7@0+ (1,0) [0|127] ""  Vector__XXX
 SG_ HoodOprtMdReq : 25|2@0+ (1,0) [0|3] ""  Vector__XXX
 SG_ HoodPrkPosSetReq : 28|3@0+ (1,0) [0|7] ""  Vector__XXX
 SG_ HoodOprtReq : 31|3@0+ (1,0) [0|7] ""  Vector__XXX
 SG_ HoodBuzSet : 39|2@0+ (1,0) [0|3] ""  Vector__XXX
 SG_ Wdw_CRPAutoOprtnReq : 126|7@0+ (1,0) [0|127] ""  Vector__XXX
 SG_ CRPUnLckReq : 127|1@0+ (1,0) [0|1] ""  Vector__XXX

BO_ 840 BodySts4: 32 Vector__XXX
 SG_ WdwCRPOprtSts : 48|2@0+ (1,0) [0|3] ""  FICM_FD
 SG_ WdwCRPPos : 62|7@0+ (1,0) [0|127] ""  FICM_FD

BO_ 607 WadeSensingSts: 32 Vector__XXX
 SG_ WadeDep_MaxVal : 30|7@0+ (10,0) [0|1270] "mm"  FICM_FD
 SG_ WadeDep_MaxPosn : 38|7@0+ (1,0) [0|127] "%"  FICM_FD
 SG_ WadeDep_CurrVal : 46|7@0+ (10,0) [0|1270] "mm"  FICM_FD
 SG_ WadeDep_CurrPosn : 54|7@0+ (1,0) [0|127] "%"  FICM_FD
 SG_ WadeSenActvSts : 58|2@0+ (1,0) [0|3] ""  FICM_FD
 SG_ WadeDepDsplyEn : 56|1@0+ (1,0) [0|1] ""  FICM_FD
 SG_ WadeSenMsgDisp : 63|5@0+ (1,0) [0|31] ""  FICM_FD

BO_ 582 RAEBCtrlInfo: 8 Vector__XXX
 SG_ RAEBMainSwFdbck : 39|1@0+ (1,0) [0|1] ""  FICM_FD
 SG_ RCWMainSwFdbck : 32|1@0+ (1,0) [0|1] ""  FICM_FD

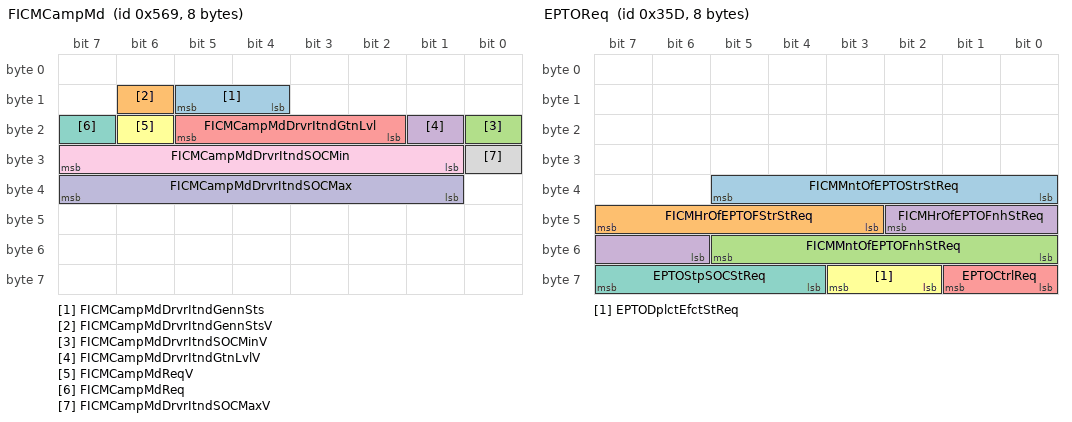
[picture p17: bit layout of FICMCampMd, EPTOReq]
BO_ 1385 FICMCampMd: 8 FICM_FD
 SG_ FICMCampMdDrvrItndGennSts : 13|2@0+ (1,0) [0|3] ""  Vector__XXX
 SG_ FICMCampMdDrvrItndGennStsV : 14|1@0+ (1,0) [0|1] ""  Vector__XXX
 SG_ FICMCampMdDrvrItndSOCMinV : 16|1@0+ (1,0) [0|1] ""  Vector__XXX
 SG_ FICMCampMdDrvrItndGtnLvlV : 17|1@0+ (1,0) [0|1] ""  Vector__XXX
 SG_ FICMCampMdDrvrItndGtnLvl : 21|4@0+ (1,0) [0|15] ""  Vector__XXX
 SG_ FICMCampMdReqV : 22|1@0+ (1,0) [0|1] ""  Vector__XXX
 SG_ FICMCampMdReq : 23|1@0+ (1,0) [0|1] ""  Vector__XXX
 SG_ FICMCampMdDrvrItndSOCMaxV : 24|1@0+ (1,0) [0|1] ""  Vector__XXX
 SG_ FICMCampMdDrvrItndSOCMin : 31|7@0+ (1,0) [0|127] ""  Vector__XXX
 SG_ FICMCampMdDrvrItndSOCMax : 39|7@0+ (1,0) [0|127] ""  Vector__XXX

BO_ 861 EPTOReq: 8 FICM_FD
 SG_ FICMMntOfEPTOStrStReq : 37|6@0+ (1,0) [0|63] "Minute"  Vector__XXX
 SG_ FICMHrOfEPTOFStrStReq : 47|5@0+ (1,0) [0|31] "Hour"  Vector__XXX
 SG_ FICMMntOfEPTOFnhStReq : 53|6@0+ (1,0) [0|63] "Minute"  Vector__XXX
 SG_ FICMHrOfEPTOFnhStReq : 42|5@0+ (1,0) [0|31] "Hour"  Vector__XXX
 SG_ EPTOCtrlReq : 57|2@0+ (1,0) [0|3] ""  Vector__XXX
 SG_ EPTODplctEfctStReq : 59|2@0+ (1,0) [0|3] ""  Vector__XXX
 SG_ EPTOStpSOCStReq : 63|4@0+ (1,0) [0|15] "%"  Vector__XXX

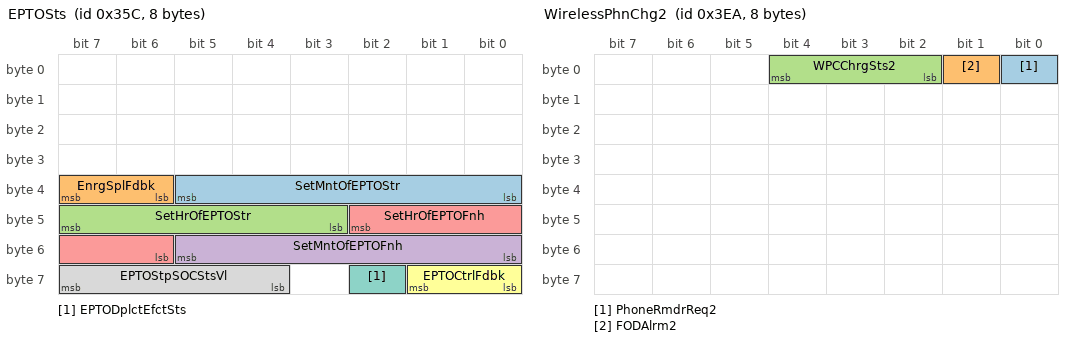
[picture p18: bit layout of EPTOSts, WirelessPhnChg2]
BO_ 860 EPTOSts: 8 Vector__XXX
 SG_ SetMntOfEPTOStr : 37|6@0+ (1,0) [0|63] "Minute"  FICM_FD
 SG_ EnrgSplFdbk : 39|2@0+ (1,0) [0|3] ""  FICM_FD
 SG_ SetHrOfEPTOStr : 47|5@0+ (1,0) [0|31] "Hour"  FICM_FD
 SG_ SetMntOfEPTOFnh : 53|6@0+ (1,0) [0|63] "Minute"  FICM_FD
 SG_ SetHrOfEPTOFnh : 42|5@0+ (1,0) [0|31] "Hour"  FICM_FD
 SG_ EPTOCtrlFdbk : 57|2@0+ (1,0) [0|3] ""  FICM_FD
 SG_ EPTODplctEfctSts : 58|1@0+ (1,0) [0|1] ""  FICM_FD
 SG_ EPTOStpSOCStsVl : 63|4@0+ (1,0) [0|15] "%"  FICM_FD

BO_ 167 IPB_Status: 32 Vector__XXX
 SG_ IPB_A7h_PDU_00_Chksum : 7|8@0+ (1,0) [0|255] ""  FICM_FD
 SG_ IPB_A7h_PDU_00_RllCnt : 15|4@0+ (1,0) [0|15] ""  FICM_FD
 SG_ FWAwarning : 51|2@0+ (1,0) [0|3] ""  FICM_FD
 SG_ BrkFlWarning : 53|2@0+ (1,0) [0|3] ""  FICM_FD
 SG_ IPBSts : 63|3@0+ (1,0) [0|7] ""  FICM_FD
 SG_ CSTSts : 73|2@0+ (1,0) [0|3] ""  FICM_FD

BO_ 1002 WirelessPhnChg2: 8 Vector__XXX
 SG_ PhoneRmdrReq2 : 0|1@0+ (1,0) [0|1] ""  FICM_FD
 SG_ FODAlrm2 : 1|1@0+ (1,0) [0|1] ""  FICM_FD
 SG_ WPCChrgSts2 : 4|3@0+ (1,0) [0|7] ""  FICM_FD

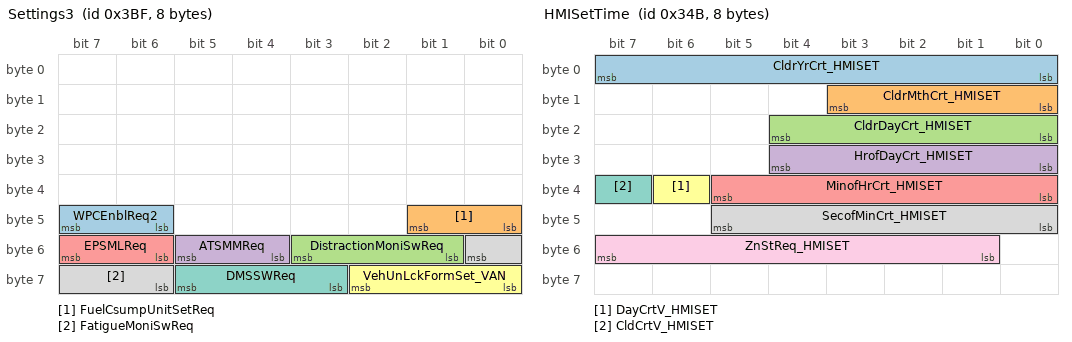
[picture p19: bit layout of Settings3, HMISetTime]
BO_ 959 Settings3: 8 FICM_FD
 SG_ WPCEnblReq2 : 47|2@0+ (1,0) [0|3] ""  Vector__XXX
 SG_ FuelCsumpUnitSetReq : 41|2@0+ (1,0) [0|3] ""  Vector__XXX
 SG_ DistractionMoniSwReq : 51|3@0+ (1,0) [0|7] ""  Vector__XXX
 SG_ ATSMMReq : 53|2@0+ (1,0) [0|3] ""  Vector__XXX
 SG_ EPSMLReq : 55|2@0+ (1,0) [0|3] ""  Vector__XXX
 SG_ VehUnLckFormSet_VAN : 58|3@0+ (1,0) [0|7] ""  Vector__XXX
 SG_ DMSSWReq : 61|3@0+ (1,0) [0|7] ""  Vector__XXX
 SG_ FatigueMoniSwReq : 48|3@0+ (1,0) [0|7] ""  Vector__XXX

BO_ 705 Chassis_PowerTrainCtrl3: 32 FICM_FD
 SG_ CH_PT_Ctrl3_PDU_00_Chksum : 7|8@0+ (1,0) [0|255] ""  Vector__XXX
 SG_ CH_PT_Ctrl3_PDU_00_RllCnt : 15|4@0+ (1,0) [0|15] ""  Vector__XXX
 SG_ iTurnFnSwReq : 9|2@0+ (1,0) [0|3] ""  Vector__XXX
 SG_ CSTFnSwReq : 11|2@0+ (1,0) [0|3] ""  Vector__XXX

BO_ 942 PowerTrainCtrl: 32 FICM_FD
 SG_ FICMDsChrgVolReq : 61|2@0+ (1,0) [0|3] ""  Vector__XXX
 SG_ FICMDsChrgFreqReq : 63|2@0+ (1,0) [0|3] ""  Vector__XXX

BO_ 1518 FICM_InterInfo: 8 FICM_FD
 SG_ FICM_InterInfo : 7|64@0+ (1,0) [0|18446744073709551615] ""  Vector__XXX

BO_ 1519 IPK_InterInfo: 8 Vector__XXX
 SG_ IPK_InterInfo : 7|64@0+ (1,0) [0|18446744073709551615] ""  FICM_FD

BO_ 843 HMISetTime: 8 FICM_FD
 SG_ CldrYrCrt_HMISET : 7|8@0+ (1,2000) [2000|2255] ""  Vector__XXX
 SG_ CldrMthCrt_HMISET : 11|4@0+ (1,0) [0|12] ""  Vector__XXX
 SG_ CldrDayCrt_HMISET : 20|5@0+ (1,0) [0|31] ""  Vector__XXX
 SG_ HrofDayCrt_HMISET : 28|5@0+ (1,0) [0|23] ""  Vector__XXX
 SG_ MinofHrCrt_HMISET : 37|6@0+ (1,0) [0|63] ""  Vector__XXX
 SG_ DayCrtV_HMISET : 38|1@0+ (1,0) [0|1] ""  Vector__XXX
 SG_ CldCrtV_HMISET : 39|1@0+ (1,0) [0|1] ""  Vector__XXX
 SG_ SecofMinCrt_HMISET : 45|6@0+ (1,0) [0|63] ""  Vector__XXX
 SG_ ZnStReq_HMISET : 55|7@0+ (1,0) [0|127] ""  Vector__XXX

CM_ SG_ 153 EMSSysOpngMdV "EMS System Operating Mode Validity";
CM_ SG_ 153 EMSSysOpngMd "EMS System Operating Mode";
CM_ SG_ 153 WadeModeActSts "涉水模式起动发动机状态反馈";
CM_ SG_ 153 WadeModeDispCmd "涉水模式起动发动机失败原因反馈";

CM_ SG_ 165 LDrvnWhlRotlDistPlsCtr "Left Driven Wheel Rotational Distance Pulse Counter";
CM_ SG_ 165 LDrvnWhlRotlDistPlsCtrV "Rotational Distance Timestamp Qualifier Left Driven Wheel";
CM_ SG_ 165 RDrvnWhlRotlDistPlsCtr "Right Driven Wheel Rotational Distance Pulse Counter";
CM_ SG_ 165 RDrvnWhlRotlDistPlsCtrV "Rotational Distance Timestamp Qualifier Right Driven Wheel";

CM_ SG_ 168 LNonDrvnWhlRotlDistPlsCtr "NonLeft Driven Wheel Rotational Distance Pulse Counter";
CM_ SG_ 168 LNonDrvnWhlRotlDistPlsCtrV "Rotational Distance Timestamp Qualifier Non Left Driven Wheel";
CM_ SG_ 168 RNonDrvnWhlRotlDistPlsCtr "NonRight Driven Wheel Rotational Distance Pulse Counter";
CM_ SG_ 168 RNonDrvnWhlRotlDistPlsCtrV "NonRotational Distance Timestamp Qualifier Right Driven Wheel";

CM_ SG_ 169 WhlSpdFLV "Wheel Speed FL Qualifier";
CM_ SG_ 169 WhlSpdFL "Wheel Speed FL";
CM_ SG_ 169 WhlSpdFRV "Wheel Speed FR Qualifier";
CM_ SG_ 169 WhlSpdFR "Wheel Speed FR";
CM_ SG_ 169 WhlDircnFL "Wheel Rotational FL Direction";
CM_ SG_ 169 WhlDircnFLV "Wheel Rotational FL Direction Qualifier";
CM_ SG_ 169 WhlDircnFR "Wheel Rotational FR Direction";
CM_ SG_ 169 WhlDircnFRV "Wheel Rotational FR Direction Qualifier";

CM_ SG_ 170 WhlSpdRLV "Wheel Speed RL Qualifier";
CM_ SG_ 170 WhlSpdRL "Wheel Speed RL";
CM_ SG_ 170 WhlSpdRRV "Wheel Speed RR Qualifier";
CM_ SG_ 170 WhlSpdRR "Wheel Speed RR";
CM_ SG_ 170 WhlDircnRL "Wheel Rotational RL Direction";
CM_ SG_ 170 WhlDircnRLV "Wheel Rotational RL Direction Qualifier";
CM_ SG_ 170 WhlDircnRR "Wheel Rotational RR Direction";
CM_ SG_ 170 WhlDircnRRV "Wheel Rotational RR Direction Qualifier";

CM_ SG_ 337 TCCUSysOpngMd "TO BCM IPK EMS";

CM_ SG_ 720 ATSMMSts "ATS模式下电记忆状态";
CM_ SG_ 720 EPSMLSts "EPS手感模式ATS联动状态";

CM_ SG_ 325 iTurnSysDispMsgReq "仪表显示请求，表征iTurn工作不满足的前提条件";
CM_ SG_ 325 iTurnSts "iTurn工作状态反馈";
CM_ SG_ 325 DrSbltWarn "主驾车门和安全带提醒";
CM_ SG_ 325 EPBReWarn "驻车释放提醒";
CM_ SG_ 325 OffRoadMdWarn "4L模式提醒（ICE/PHEV车型） 越野模式提醒（EV车型）";
CM_ SG_ 325 ShftDWarn "挂入行驶挡位提醒";
CM_ SG_ 325 CCOMDWarn "进入越野蠕行CCO提醒";
CM_ SG_ 325 UnLEDLWarn "解除差速锁提醒";
CM_ SG_ 325 TrStringWarn "方向盘最大角度提醒";

CM_ SG_ 1019 FICMDrvrItndHVBatSOC "E=N*1 %";

CM_ SG_ 1021 FICMHourOfBatHeat "本地时间, 0~23代表00到23小时";
CM_ SG_ 1021 FICMMinOfBatHeat "本地时间,1~60代表1到60分钟";
CM_ SG_ 1021 FICMInnerV2LReq "大屏请求iCGM控制车内放电请求信号";
CM_ SG_ 1021 FICMInnerV2LKeepTimeReq "车内V2L下电保持时间设置请求";
CM_ SG_ 1021 FuelModSw "纯燃料模式开关（PEMS需求）";
CM_ SG_ 1021 FICMHourOfBatHeat1 "本地时间, 0~23代表00到23小时";
CM_ SG_ 1021 FICMMinOfBatHeat1 "本地时间,1~60代表1到60分钟";
CM_ SG_ 1021 EnStrtRequest_V2L "到达截止电量启发动机开关信号";

CM_ SG_ 1022 ICGMHourOfBatHeat "本地时间,1~24代表00到23小时";
CM_ SG_ 1022 ICGMMinOfBatHeat "本地时间,1~60代表1到60分钟";
CM_ SG_ 1022 ICGMHourOfBatHeat1 "本地时间,1~24代表00到23小时";
CM_ SG_ 1022 ICGMMinOfBatHeat1 "本地时间,1~60代表1到60分钟";

CM_ SG_ 812 FICMReserCtrlReq "预约充电开关";
CM_ SG_ 812 FICMChrgTrgtSOCReq "充电截止电量控制";
CM_ SG_ 812 FICMAltngChrgCrntReq "慢充充电电流控制";
CM_ SG_ 812 FICMReserSpHour "预约充电时间设置";
CM_ SG_ 812 FICMReserSpMinute "预约充电时间设置";
CM_ SG_ 812 FICMReserStHour "预约充电时间设置";
CM_ SG_ 812 FICMReserStMinute "预约充电时间设置";

CM_ SG_ 777 CCUOffBdChrgrPlugOnV "快充枪连接状态有效性";
CM_ SG_ 777 CCUOffBdChrgrPlugOn "快充枪连接状态";

CM_ SG_ 805 IMCUDschrgngEstdElecRngV "换电转移，放电结束预估续驶里程Valid";
CM_ SG_ 805 IMCUDschrgngEstdElecRng "换电转移，放电结束预估续驶里程";
CM_ SG_ 805 IMCUDschrgTrgtSOCDspCmd "放电截止电量反馈";

CM_ SG_ 871 ESSSwapSttnAndVehComSta "车和站通讯状态信号";
CM_ SG_ 871 ESSSwapVehInSwapArea "车辆是否在换电区域信号（站端发送）";

CM_ SG_ 1006 FICMChrgCtrlReq "充电启停";
CM_ SG_ 1006 FICMOnRutWarmOffReq "智能加热";
CM_ SG_ 1006 FICMChrgSttnMchngSta "充电桩鉴权";
CM_ SG_ 1006 FICMEleccLckCtrlReq "电子锁控制功能迁移到CCU";
CM_ SG_ 1006 DsttnTypOfNav "智能加热";
CM_ SG_ 1006 FICMOnRutWarmOffReqV "智能加热";
CM_ SG_ 1006 NavGudcSts "智能加热";
CM_ SG_ 1006 DistToDsttnNav "智能加热";
CM_ SG_ 1006 ChrgngSttnCapctOfDsttnNav "智能加热";
CM_ SG_ 1006 FICMV2XReq "大屏请求V2L";
CM_ SG_ 1006 GudTimeToDsttnNav "智能加热";

CM_ SG_ 816 AirSuspUpSts "车机显示空气悬架上升图标状态";
CM_ SG_ 816 AirSuspDnSts "车机显示空气悬架下降图标状态";
CM_ SG_ 816 AirSuspHtSetBtnSts "空气悬架高度设置按钮置灰状态";
CM_ SG_ 816 AirSuspHeightSts "空气悬架高度设置请求反馈
Default：高度状态按钮不高亮显示，其余高亮对应的按钮";
CM_ SG_ 816 FxdMdSetReqFedbk "维修模式设置请求反馈（含按钮置灰状态）";
CM_ SG_ 816 ECASFctyDeftSetFnd "恢复出厂设置反馈
PDC Factory Default Setting Finished";
CM_ SG_ 816 VehRrAxlWgt "车辆后桥载荷预估";

CM_ SG_ 762 RFGOprtSts "冰箱实际启动状态";
CM_ SG_ 762 RFGTrgtTemp "冰箱工作的目标温度值E=N*1(0℃~50℃)";
CM_ SG_ 762 RFGOprtEndRsn "冰箱工作退出原因";
CM_ SG_ 762 RFGOprtMdSts "冰箱的工作模式";
CM_ SG_ 762 RFGEngOffOprtSetSts "冰箱熄火保持设置状态";
CM_ SG_ 762 RFGEngOffOprtDur "冰箱熄火保持时长E = N (1h~24h)";
CM_ SG_ 762 RCPSWEnblSts "RCP 开关使能状态";

CM_ SG_ 967 InnerDsChrgPlug "车内V2L插座连接状态";
CM_ SG_ 967 InnerDsChrgPlugV "车内V2L插座连接状态有效性";
CM_ SG_ 967 IBDUInnerDsChrgPlugTmpWrn "车内V2L插座温度传感器报警信号";

CM_ SG_ 994 TirePrs_RLOS "左后外部胎压值";
CM_ SG_ 994 TirePrs_RROS "右后外部胎压值";
CM_ SG_ 994 TireTmp_RLOS "左后外部胎温值";
CM_ SG_ 994 TireTmp_RROS "右后外部胎温值";

CM_ SG_ 902 StTrkPos_PR2 "旋转座椅水平位置";
CM_ SG_ 902 StTurnPos_PR "旋转座椅旋转位置";
CM_ SG_ 902 StRtaPos_PR2 "旋转座椅靠背位置";
CM_ SG_ 902 StLgRtaPos_PR "旋转座椅腿托位置";
CM_ SG_ 902 StHtSts_PR2 "座椅加热状态";

CM_ SG_ 903 StRtaRmndReq_PR "副驾旋转座椅提醒请求";

CM_ SG_ 870 CldrYr_UTC "1、Quantization:1 year
2、phys range:2000-2255
3、0: year (0x0 - 0xFF)
4、offset:2000";
CM_ SG_ 870 CldrDay_UTC "1、Quantization:1 days
2、phys range:0-30
3、0: days (0x0 - 0x1F)";
CM_ SG_ 870 HrofDay_UTC "1、Quantization:1 
2、phys range:0-23
3、0: (0x0 - 0x17)";
CM_ SG_ 870 MinofHr_UTC "1、Quantization:1 
2、phys range:0-59
3、0: (0x0 - 0x3B)";
CM_ SG_ 870 SecofMin_UTC "1、Quantization:1 
2、phys range:0-59
3、0: (0x0 - 0x3B)";

CM_ SG_ 927 CldDiagGPSPermsnSwReq_HMI "云诊断位置权限开关设置";
CM_ SG_ 927 VehPosPermsnSwReq_HMI "车辆位置开关设置";
CM_ SG_ 927 PrvyCtrlAPNCnctnSts "隐私控制APN连接状态";
CM_ SG_ 927 PrvyPlyAuthSts "隐私政策授权状态";
CM_ SG_ 927 CldDiagPosPermsnSwSts "云诊断位置权限开关状态（应用级）";
CM_ SG_ 927 MobileAppPosPermsnSwSts "手机APP位置权限开关状态（应用级）";
CM_ SG_ 927 VehPosPermsnMnSwSts "位置权限总开关状态";
CM_ SG_ 927 MicPermsnMnSwSts "麦克风权限总开关状态";
CM_ SG_ 927 IterCamPermsnMnSwSts "车内摄像头权限总开关状态";

CM_ SG_ 938 SpdLmtUnt "限速单位";
CM_ SG_ 938 MAPCountryID "地图国家ID";
CM_ SG_ 938 CurrRoadSpdLmt "当前道路限速";
CM_ SG_ 938 MAPCovSts "地图覆盖状态";
CM_ SG_ 938 CurrPosSts "当前定位状态";
CM_ SG_ 938 MAPConfidence "置信度";
CM_ SG_ 938 SpdLmtType "限速类型";
CM_ SG_ 938 CurrRoadType "当前道路类型";

CM_ SG_ 939 StTrkPosReq_DR_HMI "DR座椅水平目标位置";
CM_ SG_ 939 StRtaPosReq_DR_HMI "DR座椅靠背目标位置";

CM_ SG_ 1017 InnerV2LResp "车内放电执行状态反馈";
CM_ SG_ 1017 InnerV2LDspCmd "车内放电准备，开启，完成反馈";
CM_ SG_ 1017 OuterV2LResp "车外放电执行状态反馈";
CM_ SG_ 1017 InnerV2LBtnSts "车内放电按钮置灰指令";
CM_ SG_ 1017 OuterV2LBtnSts "车外放电按钮置灰指令";
CM_ SG_ 1017 InnerDsChrgSpRsn "车内V2L，放电中止原因";
CM_ SG_ 1017 InnerV2LKeepTimeDspCmd "车内V2L下电保持时间（EEPROM记忆）";
CM_ SG_ 1017 OuterV2LDspCmd "车外放电开启，准备及完成反馈";

CM_ SG_ 1376 DcrtvLmpSwSts "装饰灯开关状态";

CM_ SG_ 1370 ClnWtrTnk1 "清水箱水位";
CM_ SG_ 1370 KtchGryWtrTnk "灰水箱1水位（厨房灰水箱）";
CM_ SG_ 1370 TlGryWtrTnk "灰水箱2水位（卫生间灰水箱）";

CM_ SG_ 1365 RrACTempSetSts "后空调温度状态";
CM_ SG_ 1365 RrACMdSts "空调模式状态";
CM_ SG_ 1365 RrACPwrSts "后空调开关状态";
CM_ SG_ 1365 RrACBlwrLvlSts "后空调风速状态";
CM_ SG_ 1365 RrACTmShtdwnSetFdbck "后空调定时关机设置反馈";

CM_ SG_ 1281 BMSRptBatCodeIndx "电池包编码，国标上传";
CM_ SG_ 1281 BMSRptBatCodeAsc1 "电池包编码，国标上传";
CM_ SG_ 1281 BMSRptBatCodeAsc2 "电池包编码，国标上传";
CM_ SG_ 1281 BMSRptBatCodeAsc3 "电池包编码，国标上传";
CM_ SG_ 1281 BMSRptBatCodeAsc4 "电池包编码，国标上传";
CM_ SG_ 1281 BMSRptBatCodeAsc5 "电池包编码，国标上传";
CM_ SG_ 1281 BMSRptBatCodeAsc6 "电池包编码，国标上传";
CM_ SG_ 1281 BMSRptBatCodeAsc7 "电池包编码，国标上传";

CM_ SG_ 1354 ESSSwapWaitNum "换电排队等待人数";
CM_ SG_ 1354 ESSSwapWaitNumV "换电排队等待人数有效性";

CM_ SG_ 963 BaaSManuSetngReslt "换电电池云端强制上锁/解锁结果";
CM_ SG_ 963 ESSSwapStrgWhlPsd "方向盘检查通过";
CM_ SG_ 963 ESSSwapShifterLvrPsd "档位检查通过";
CM_ SG_ 963 ESSSwapDoorPsd "车门检查通过";
CM_ SG_ 963 ESSSwapChkPsd "自检通过";
CM_ SG_ 963 ESSSwapBrkPsd "刹车换电自检状态信号";
CM_ SG_ 963 ESSSwapEPBPsd "EPB换电自检状态信号";
CM_ SG_ 963 ESSSwapSuspdng "开门换电中止提示";

CM_ SG_ 1280 SupportQueue "换电站是否支持排队";
CM_ SG_ 1280 EstdWtngTime "预计等待时间EstdWtngTime";
CM_ SG_ 1280 RqungReq "过号重新排队提醒RqungReq";
CM_ SG_ 1280 OrderSts "订单状态";
CM_ SG_ 1280 QueueNum "排队号码QueueNum";

CM_ SG_ 989 OuterV2LBtnDisableRsn "车外放电按钮禁用原因，注: 多个原因同时出现时，以求和的形式同时发送";
CM_ SG_ 989 InnerV2LBtnDisableRsn "车内放电按钮禁用原因，注: 多个原因同时出现时，以求和的形式同时发送";
CM_ SG_ 989 VCUInnerDsChrgPlugTmpWrn "车内V2L插座温度传感器报警信号";
CM_ SG_ 989 V2LBtnDisablePtCtrl "放电按钮禁用是否由PT侧控制";
CM_ SG_ 989 OuterV2LBtnStsPt "车外放电按钮置灰指令(动力侧发送)";
CM_ SG_ 989 InnerV2LBtnStsPt "车内放电按钮置灰指令(动力侧发送)";

CM_ SG_ 815 Easy2LoadSetReqFedbk "轻松载物软开关请求反馈";
CM_ SG_ 815 TowMdSetReqFedbk "拖挂模式软开关请求反馈";
CM_ SG_ 815 CampMdSetReqFedbk "营地模式软开关请求反馈";
CM_ SG_ 815 ECASWelcomeSts "便捷进出软开关请求反馈";
CM_ SG_ 815 AirSuspTxtMsg2FICM "空气悬架娱乐大屏文字信息";
CM_ SG_ 815 AirSuspHeightSts2IPK "空气悬架仪表显示高度状态";
CM_ SG_ 815 OnBdScaTxtMsg2FICM "车载秤娱乐大屏文字信息";
CM_ SG_ 815 AirSuspTxtMsg2IPK "空气悬架仪表显示文字信息";
CM_ SG_ 815 PayloadPct "净载荷百分比";
CM_ SG_ 815 CurrPayload "当前净载荷数值";
CM_ SG_ 815 ECASHirBtnSts "空气悬架最高软开关置灰状态";
CM_ SG_ 815 ECASHiBtnSts "空气悬架高软开关置灰状态";
CM_ SG_ 815 MaxPayload "最大净载荷数值";
CM_ SG_ 815 ECASStdBtnSts "空气悬架标准软开关置灰状态";
CM_ SG_ 815 ECASLoBtnSts "空气悬架低软开关置灰状态";
CM_ SG_ 815 ECASLowrBtnSts "空气悬架最低软开关置灰状态";
CM_ SG_ 815 OnBdScaLoadUpdSts "载荷更新开关置灰状态";
CM_ SG_ 815 CurrPayloadDispEna "当前净载荷数值显示使能";

CM_ SG_ 620 EASCAdjReqFedbk "方向盘位置调节请求反馈";
CM_ SG_ 620 EASCPosnSaveFedbk "方向盘位置保存反馈";
CM_ SG_ 620 EASCPosnRecFedbk "方向盘位置恢复反馈";
CM_ SG_ 620 EASCFctyDeftSetFnd "EASC恢复出厂设置反馈";
CM_ SG_ 620 EASCErrSts "EASC故障状态";

CM_ SG_ 825 HoodLockSts "前舱盖锁状态";
CM_ SG_ 825 HoodOprtSts "前舱盖运行状态";
CM_ SG_ 825 HoodOpnPos "前舱盖打开位置";
CM_ SG_ 825 HoodOprtMdSts "前舱盖工作模式状态";
CM_ SG_ 825 HoodPrkPosSetSts "前舱盖开度设置状态";
CM_ SG_ 825 HoodBuzReq "前舱盖蜂鸣提示请求";
CM_ SG_ 825 HoodAbsAlrm "前舱盖滥用保护提醒";
CM_ SG_ 825 HoodBuzSetSts "前舱盖声音提示设置状态";
CM_ SG_ 825 DrAjr_TnovrEdGt "折叠踏步开关状态";
CM_ SG_ 825 HoodCtrlBtnSts "前舱盖控制按钮置灰指令";

CM_ SG_ 831 HoodPrkPosReq "前舱盖开度请求";
CM_ SG_ 831 HoodOprtMdReq "前舱盖工作模式设置";
CM_ SG_ 831 HoodPrkPosSetReq "前舱盖开度设置";
CM_ SG_ 831 HoodOprtReq "前舱盖动作请求";
CM_ SG_ 831 HoodBuzSet "前舱盖声音提示设置";
CM_ SG_ 831 Wdw_CRPAutoOprtnReq "后围车窗位置调节命令";
CM_ SG_ 831 CRPUnLckReq "后围解锁命令";

CM_ SG_ 840 WdwCRPOprtSts "后围车窗运动状态";
CM_ SG_ 840 WdwCRPPos "后围车窗位置";

CM_ SG_ 607 WadeDep_MaxVal "最大涉水深度值";
CM_ SG_ 607 WadeDep_MaxPosn "最深水位线位置";
CM_ SG_ 607 WadeDep_CurrVal "当前涉水深度值";
CM_ SG_ 607 WadeDep_CurrPosn "当前涉水水位线位置";
CM_ SG_ 607 WadeSenActvSts "涉水感应激活状态";
CM_ SG_ 607 WadeDepDsplyEn "涉水深度值显示使能";
CM_ SG_ 607 WadeSenMsgDisp "涉水感应信息显示";

CM_ SG_ 582 RAEBMainSwFdbck "RAEB+RCW开关反馈";

CM_ SG_ 1385 FICMCampMdDrvrItndGennSts "Front Infotainment Control Module Camp Mode Driver Intended Generation";
CM_ SG_ 1385 FICMCampMdDrvrItndGennStsV "Front Infotainment Control Module Camp Mode Driver Intended Generation Status Validity";
CM_ SG_ 1385 FICMCampMdDrvrItndSOCMinV "Front Infotainment Control Module Camp Mode Driver Intended State Of Charge Minimum Validity";
CM_ SG_ 1385 FICMCampMdDrvrItndGtnLvlV "Ficm Camp Mode Driver Intended Generation Level Validty";
CM_ SG_ 1385 FICMCampMdDrvrItndGtnLvl "Ficm Camp Mode Driver Intended Generation Level";
CM_ SG_ 1385 FICMCampMdReqV "Ficm Camp Mode Request Validty";
CM_ SG_ 1385 FICMCampMdReq "Ficm Camp Mode Request";
CM_ SG_ 1385 FICMCampMdDrvrItndSOCMaxV "Front Infotainment Control Module Camp Mode Driver Intended State Of Charge Maximum Validity";
CM_ SG_ 1385 FICMCampMdDrvrItndSOCMin "Front Infotainment Control Module Camp Mode Driver Intended State Of Charge Minimum";
CM_ SG_ 1385 FICMCampMdDrvrItndSOCMax "Front Infotainment Control Module Camp Mode Driver Intended State Of Charge Maximum";

CM_ SG_ 861 FICMMntOfEPTOStrStReq "EPTO定时分钟位（开始）";
CM_ SG_ 861 FICMHrOfEPTOFStrStReq "EPTO定时小时位（开始）";
CM_ SG_ 861 FICMMntOfEPTOFnhStReq "EPTO定时分钟位（结束）";
CM_ SG_ 861 FICMHrOfEPTOFnhStReq "EPTO定时小时位（结束）";
CM_ SG_ 861 EPTOCtrlReq "EPTO控制请求";
CM_ SG_ 861 EPTODplctEfctStReq "EPTO预约重复生效设置";
CM_ SG_ 861 EPTOStpSOCStReq "EPTO截至电量设置";

CM_ SG_ 860 SetMntOfEPTOStr "已设置的EPTO定时分钟位（开始）";
CM_ SG_ 860 EnrgSplFdbk "EPTO可开启状态反馈";
CM_ SG_ 860 SetHrOfEPTOStr "已设置的EPTO定时小时位（开始）";
CM_ SG_ 860 SetMntOfEPTOFnh "已设置的EPTO定时分钟位（结束）";
CM_ SG_ 860 SetHrOfEPTOFnh "已设置的EPTO定时小时位（结束）";
CM_ SG_ 860 EPTOCtrlFdbk "EPTO控制请求反馈";
CM_ SG_ 860 EPTODplctEfctSts "EPTO预约重复生效状态";
CM_ SG_ 860 EPTOStpSOCStsVl "EPTO截至电量设置";

CM_ SG_ 167 FWAwarning "热衰退提醒，需仪表亮红灯
Indicate FWA state, dashboard need warn driver";
CM_ SG_ 167 BrkFlWarning "制动液壶液位报警
Indicate brake fluid level ";
CM_ SG_ 167 IPBSts "代表IPB系统状态
Indicate HSH system state.";
CM_ SG_ 167 CSTSts "CST功能状态";

CM_ SG_ 1002 PhoneRmdrReq2 "手机遗忘提醒";
CM_ SG_ 1002 FODAlrm2 "异物提醒";
CM_ SG_ 1002 WPCChrgSts2 "充电状态";

CM_ SG_ 959 WPCEnblReq2 "无线充电2使能信号";
CM_ SG_ 959 DistractionMoniSwReq "分心监测设置开关开/闭请求";
CM_ SG_ 959 ATSMMReq "ATS模式记忆开关";
CM_ SG_ 959 EPSMLReq "大屏软开关请求，表征转向助力模式是否与ATS模式关联";
CM_ SG_ 959 VehUnLckFormSet_VAN "解锁反馈方式设置（仅VAN车用）";
CM_ SG_ 959 DMSSWReq "DMS功能总开关";
CM_ SG_ 959 FatigueMoniSwReq "疲劳监测设置开关开/闭请求";

CM_ SG_ 705 iTurnFnSwReq "大屏智能掉头打开/关闭软开关请求";
CM_ SG_ 705 CSTFnSwReq "开启/关闭CST个性化设置请求";

CM_ SG_ 942 FICMDsChrgVolReq "用户放电电压设置值";
CM_ SG_ 942 FICMDsChrgFreqReq "用户放电频率设置值";

CM_ SG_ 1518 FICM_InterInfo "multimedia interaction with IPK";

CM_ SG_ 1519 IPK_InterInfo "multimedia interaction with FICM";

CM_ SG_ 843 CldrYrCrt_HMISET "日期页面设置-年";
CM_ SG_ 843 CldrMthCrt_HMISET "日期页面设置-月";
CM_ SG_ 843 CldrDayCrt_HMISET "日期页面设置-日";
CM_ SG_ 843 HrofDayCrt_HMISET "时间页面设置-时";
CM_ SG_ 843 MinofHrCrt_HMISET "时间页面设置-分";
CM_ SG_ 843 DayCrtV_HMISET "时间页面设置有效位";
CM_ SG_ 843 CldCrtV_HMISET "日期页面设置有效位";
CM_ SG_ 843 SecofMinCrt_HMISET "时间页面设置-秒";
CM_ SG_ 843 ZnStReq_HMISET "时区页面设置请求";
BA_DEF_ SG_  "GenSigTimeoutValue" INT 0 65535;
BA_DEF_ BO_  "DiagState" ENUM  "no","yes";
BA_DEF_ BO_  "GenMsgNrOfRepetition" INT 0 65535;
BA_DEF_ BO_  "GenMsgSendType" ENUM  "Cyclic","NotUsed","NotUsed","NotUsed","NotUsed","NotUsed","NotUsed","IfActive","NoMsgSendType","NotUsed";
BA_DEF_ SG_  "SignalLongName" STRING ;
BA_DEF_ BO_  "VFrameFormat" ENUM  "StandardCAN","ExtendedCAN","reserved","J1939PG","reserved","reserved","reserved","reserved","reserved","reserved","reserved","reserved","reserved","reserved","StandardCAN_FD","ExtendedCAN_FD";
BA_DEF_ BO_  "NmMessage" ENUM  "no","yes";
BA_DEF_ BO_  "GenMsgDelayTime" INT 0 65535;
BA_DEF_ BO_  "GenMsgILSupport" ENUM  "no","yes";
BA_DEF_ BO_  "GenMsgStartDelayTime" INT 0 65535;
BA_DEF_ BO_  "NmAsrMessage" ENUM  "no","yes";
BA_DEF_ BO_  "DiagRequest" ENUM  "no","yes";
BA_DEF_ BO_  "DiagResponse" ENUM  "no","yes";
BA_DEF_ BO_  "GenMsgCycleTimeFast" INT 0 65535;
BA_DEF_ BO_  "GenMsgCycleTime" INT 0 30000;
BA_DEF_ SG_  "GenSigStartValue" INT 0 65535;
BA_DEF_ SG_  "GenSigInactiveValue" HEX 0 65535;
BA_DEF_ SG_  "GenSigSendType" ENUM  "Cyclic","OnWrite","OnWriteWithRepetition","OnChange","OnChangeWithRepetition","IfActive","IfActiveWithRepetition","NoSigSendType","OnChangeAndIfActive","OnChangeAndIfActiveWithRepetition";
BA_DEF_REL_ BU_SG_REL_  "GenSigTimeoutTime" INT 0 65535;
BA_DEF_DEF_  "GenSigTimeoutValue" 0;
BA_DEF_DEF_  "DiagState" "no";
BA_DEF_DEF_  "GenMsgNrOfRepetition" 0;
BA_DEF_DEF_  "GenMsgSendType" "NoMsgSendType";
BA_DEF_DEF_  "SignalLongName" "";
BA_DEF_DEF_  "VFrameFormat" "StandardCAN";
BA_DEF_DEF_  "NmMessage" "no";
BA_DEF_DEF_  "GenMsgDelayTime" 0;
BA_DEF_DEF_  "GenMsgILSupport" "no";
BA_DEF_DEF_  "GenMsgStartDelayTime" 0;
BA_DEF_DEF_  "NmAsrMessage" "no";
BA_DEF_DEF_  "DiagRequest" "no";
BA_DEF_DEF_  "DiagResponse" "no";
BA_DEF_DEF_  "GenMsgCycleTimeFast" 0;
BA_DEF_DEF_  "GenMsgCycleTime" 0;
BA_DEF_DEF_  "GenSigStartValue" 0;
BA_DEF_DEF_  "GenSigInactiveValue" 0;
BA_DEF_DEF_  "GenSigSendType" "NoSigSendType";
BA_DEF_DEF_REL_ "GenSigTimeoutTime" 0;

BA_ "GenMsgSendType" BO_ 153 0;
BA_ "GenMsgStartDelayTime" BO_ 153 10;
BA_ "GenMsgCycleTime" BO_ 153 10;
BA_ "GenMsgILSupport" BO_ 153 1;
BA_ "VFrameFormat" BO_ 153 14;

BA_ "GenSigSendType" SG_ 153 EMSSysOpngMdV 0;
BA_ "SignalLongName" SG_ 153 EMSSysOpngMdV "EMS System Operating Mode Valid";

BA_ "GenSigSendType" SG_ 153 EMSSysOpngMd 0;
BA_ "SignalLongName" SG_ 153 EMSSysOpngMd "EMS System Operating Mode";

BA_ "GenSigSendType" SG_ 153 WadeModeActSts 0;
BA_ "SignalLongName" SG_ 153 WadeModeActSts "Wade mode Action Status";

BA_ "GenSigSendType" SG_ 153 WadeModeDispCmd 0;
BA_ "SignalLongName" SG_ 153 WadeModeDispCmd "Wade Mode Display command";

BA_ "GenMsgSendType" BO_ 164 0;
BA_ "GenMsgStartDelayTime" BO_ 164 10;
BA_ "GenMsgCycleTime" BO_ 164 10;
BA_ "GenMsgILSupport" BO_ 164 1;
BA_ "VFrameFormat" BO_ 164 14;

BA_ "GenSigSendType" SG_ 164 BrkFlngMdSts 0;
BA_ "SignalLongName" SG_ 164 BrkFlngMdSts "BrakeFeelingModeStatus";

BA_ "GenSigSendType" SG_ 164 IBFSWstate 0;
BA_ "SignalLongName" SG_ 164 IBFSWstate "IBBrakeFeelingmodeSWstatus";

BA_ "GenSigSendType" SG_ 164 EBSFctryDeftSetFnsh 0;
BA_ "SignalLongName" SG_ 164 EBSFctryDeftSetFnsh "EBooster_FactoryDefaultSettingFinished";

BA_ "GenSigSendType" SG_ 164 EBOOSTStatus2_RllCnt 0;
BA_ "SignalLongName" SG_ 164 EBOOSTStatus2_RllCnt "EBOOSTStatus2 Rolling Counter";

BA_ "GenSigSendType" SG_ 164 EBOOSTStatus2_ChkSum 0;
BA_ "SignalLongName" SG_ 164 EBOOSTStatus2_ChkSum "EBOOSTStatus2 Check Sum";

BA_ "GenMsgSendType" BO_ 165 0;
BA_ "GenMsgStartDelayTime" BO_ 165 10;
BA_ "GenMsgCycleTime" BO_ 165 10;
BA_ "GenMsgILSupport" BO_ 165 1;
BA_ "VFrameFormat" BO_ 165 14;

BA_ "GenSigSendType" SG_ 165 LDrvnWhlRotlDistPlsCtr 0;
BA_ "SignalLongName" SG_ 165 LDrvnWhlRotlDistPlsCtr "LeftDrivenWheelRotationalDistancePulseCounter";

BA_ "GenSigSendType" SG_ 165 LDrvnWhlRotlDistPlsCtrV 0;
BA_ "SignalLongName" SG_ 165 LDrvnWhlRotlDistPlsCtrV "LeftDrivenWheelRotationalDistancePulseCounterValid";

BA_ "GenSigSendType" SG_ 165 RDrvnWhlRotlDistPlsCtr 0;
BA_ "SignalLongName" SG_ 165 RDrvnWhlRotlDistPlsCtr "RightDrivenWheelRotationalDistancePulseCounter";

BA_ "GenSigSendType" SG_ 165 RDrvnWhlRotlDistPlsCtrV 0;
BA_ "SignalLongName" SG_ 165 RDrvnWhlRotlDistPlsCtrV "RightDrivenWheelRotationalDistancePulseCounterValid";

BA_ "GenMsgSendType" BO_ 168 0;
BA_ "GenMsgStartDelayTime" BO_ 168 10;
BA_ "GenMsgCycleTime" BO_ 168 10;
BA_ "GenMsgILSupport" BO_ 168 1;
BA_ "VFrameFormat" BO_ 168 14;

BA_ "GenSigSendType" SG_ 168 LNonDrvnWhlRotlDistPlsCtr 0;
BA_ "SignalLongName" SG_ 168 LNonDrvnWhlRotlDistPlsCtr "LeftNonDrivenWheelRotationalDistancePulseCounter";

BA_ "GenSigSendType" SG_ 168 LNonDrvnWhlRotlDistPlsCtrV 0;
BA_ "SignalLongName" SG_ 168 LNonDrvnWhlRotlDistPlsCtrV "LeftNonDrivenWheelRotationalDistancePulseCounterValid";

BA_ "GenSigSendType" SG_ 168 RNonDrvnWhlRotlDistPlsCtr 0;
BA_ "SignalLongName" SG_ 168 RNonDrvnWhlRotlDistPlsCtr "RightNonDrivenWheelRotationalDistancePulseCounter";

BA_ "GenSigSendType" SG_ 168 RNonDrvnWhlRotlDistPlsCtrV 0;
BA_ "SignalLongName" SG_ 168 RNonDrvnWhlRotlDistPlsCtrV "RightNonDrivenWheelRotationalDistancePulseCounterValid";

BA_ "GenMsgSendType" BO_ 169 0;
BA_ "GenMsgStartDelayTime" BO_ 169 10;
BA_ "GenMsgCycleTime" BO_ 169 10;
BA_ "GenMsgILSupport" BO_ 169 1;
BA_ "VFrameFormat" BO_ 169 14;

BA_ "GenSigSendType" SG_ 169 WhlSpdFLV 0;
BA_ "SignalLongName" SG_ 169 WhlSpdFLV "WheelSpeed_FL_Valid";

BA_ "GenSigSendType" SG_ 169 WhlSpdFL 0;
BA_ "SignalLongName" SG_ 169 WhlSpdFL "WheelSpeed_FL";
BA_ "GenSigStartValue" SG_ 169 WhlSpdFL 32767;

BA_ "GenSigSendType" SG_ 169 WhlSpdFRV 0;
BA_ "SignalLongName" SG_ 169 WhlSpdFRV "WheelSpeed_FR_Valid";

BA_ "GenSigSendType" SG_ 169 WhlSpdFR 0;
BA_ "SignalLongName" SG_ 169 WhlSpdFR "WheelSpeed_FR";
BA_ "GenSigStartValue" SG_ 169 WhlSpdFR 32767;

BA_ "GenSigSendType" SG_ 169 WhlDircnFL 0;
BA_ "SignalLongName" SG_ 169 WhlDircnFL "WheelDirection_FL";

BA_ "GenSigSendType" SG_ 169 WhlDircnFLV 0;
BA_ "SignalLongName" SG_ 169 WhlDircnFLV "WheelDirection_FL_Vaild";

BA_ "GenSigSendType" SG_ 169 WhlDircnFR 0;
BA_ "SignalLongName" SG_ 169 WhlDircnFR "WheelDirection_FR";

BA_ "GenSigSendType" SG_ 169 WhlDircnFRV 0;
BA_ "SignalLongName" SG_ 169 WhlDircnFRV "WheelDirection_FR_Vaild";

BA_ "GenMsgSendType" BO_ 170 0;
BA_ "GenMsgStartDelayTime" BO_ 170 10;
BA_ "GenMsgCycleTime" BO_ 170 10;
BA_ "GenMsgILSupport" BO_ 170 1;
BA_ "VFrameFormat" BO_ 170 14;

BA_ "GenSigSendType" SG_ 170 WhlSpdRLV 0;
BA_ "SignalLongName" SG_ 170 WhlSpdRLV "WheelSpeed_RL_Valid";

BA_ "GenSigSendType" SG_ 170 WhlSpdRL 0;
BA_ "SignalLongName" SG_ 170 WhlSpdRL "WheelSpeed_RL";
BA_ "GenSigStartValue" SG_ 170 WhlSpdRL 32767;

BA_ "GenSigSendType" SG_ 170 WhlSpdRRV 0;
BA_ "SignalLongName" SG_ 170 WhlSpdRRV "WheelSpeed_RR_Valid";

BA_ "GenSigSendType" SG_ 170 WhlSpdRR 0;
BA_ "SignalLongName" SG_ 170 WhlSpdRR "WheelSpeed_RR";
BA_ "GenSigStartValue" SG_ 170 WhlSpdRR 32767;

BA_ "GenSigSendType" SG_ 170 WhlDircnRL 0;
BA_ "SignalLongName" SG_ 170 WhlDircnRL "WheelDirection_RL";

BA_ "GenSigSendType" SG_ 170 WhlDircnRLV 0;
BA_ "SignalLongName" SG_ 170 WhlDircnRLV "WheelDirection_RL_Vaild";

BA_ "GenSigSendType" SG_ 170 WhlDircnRR 0;
BA_ "SignalLongName" SG_ 170 WhlDircnRR "WheelDirection_RR";

BA_ "GenSigSendType" SG_ 170 WhlDircnRRV 0;
BA_ "SignalLongName" SG_ 170 WhlDircnRRV "WheelDirection_RR_Vaild";

BA_ "GenMsgSendType" BO_ 337 0;
BA_ "GenMsgStartDelayTime" BO_ 337 10;
BA_ "GenMsgCycleTime" BO_ 337 20;
BA_ "GenMsgILSupport" BO_ 337 1;
BA_ "VFrameFormat" BO_ 337 14;

BA_ "GenSigSendType" SG_ 337 TCCUSysOpngMd 0;
BA_ "SignalLongName" SG_ 337 TCCUSysOpngMd "TCCUSystemOperatingMode";

BA_ "GenMsgSendType" BO_ 720 0;
BA_ "GenMsgStartDelayTime" BO_ 720 10;
BA_ "GenMsgCycleTime" BO_ 720 100;
BA_ "GenMsgILSupport" BO_ 720 1;
BA_ "VFrameFormat" BO_ 720 14;

BA_ "GenSigSendType" SG_ 720 ESCFnOffFdbck_ATS 0;
BA_ "SignalLongName" SG_ 720 ESCFnOffFdbck_ATS "ESCFnOffFdbck_ATS";

BA_ "GenSigSendType" SG_ 720 ATSDrvngMdDisp 0;
BA_ "SignalLongName" SG_ 720 ATSDrvngMdDisp "ATSDrivingModeDisplay";

BA_ "GenSigSendType" SG_ 720 ATSDrvngMdDispV 0;
BA_ "SignalLongName" SG_ 720 ATSDrvngMdDispV "ATSDrivingModeDisplayValid";

BA_ "GenSigSendType" SG_ 720 ATSMMSts 0;
BA_ "SignalLongName" SG_ 720 ATSMMSts "ATSModeMemoryStatus";

BA_ "GenSigSendType" SG_ 720 EPSMLSts 0;
BA_ "SignalLongName" SG_ 720 EPSMLSts "EPSModeLinkageStatus";

BA_ "GenMsgSendType" BO_ 710 0;
BA_ "GenMsgStartDelayTime" BO_ 710 20;
BA_ "GenMsgCycleTime" BO_ 710 100;
BA_ "GenMsgILSupport" BO_ 710 1;
BA_ "VFrameFormat" BO_ 710 14;

BA_ "GenSigSendType" SG_ 710 AirClnrIonizerDspCmd 0;
BA_ "SignalLongName" SG_ 710 AirClnrIonizerDspCmd "Air Cleaner Ionizer Display Command";

BA_ "GenSigSendType" SG_ 710 AirClnrOnOffDspCmd 0;
BA_ "SignalLongName" SG_ 710 AirClnrOnOffDspCmd "Air Cleaner OnOff Display Command";

BA_ "GenSigSendType" SG_ 710 AirClnrAutoDspCmd 0;
BA_ "SignalLongName" SG_ 710 AirClnrAutoDspCmd "Air Cleaner Auto Display Command";

BA_ "GenSigSendType" SG_ 710 AirClnrUserCustAutoWDC 0;
BA_ "SignalLongName" SG_ 710 AirClnrUserCustAutoWDC "Air Cleaner User Customization Auto Work Display Command";

BA_ "GenSigSendType" SG_ 710 AirClnrBlwrLvlDspCmd 0;
BA_ "SignalLongName" SG_ 710 AirClnrBlwrLvlDspCmd "Air Cleaner Blower Level Display Command";

BA_ "GenSigSendType" SG_ 710 AirClnrFltrLife 0;
BA_ "SignalLongName" SG_ 710 AirClnrFltrLife "Air Cleaner Filter Life";

BA_ "GenSigSendType" SG_ 710 AirClnrFltrCsumLvlDspC 0;
BA_ "SignalLongName" SG_ 710 AirClnrFltrCsumLvlDspC "Air Cleaner Filter Consume Level Display Command";

BA_ "GenSigSendType" SG_ 710 AirClnrFltrLifeV 0;
BA_ "SignalLongName" SG_ 710 AirClnrFltrLifeV "Air Cleaner Filter Life Validity";

BA_ "GenMsgSendType" BO_ 592 0;
BA_ "GenMsgStartDelayTime" BO_ 592 20;
BA_ "GenMsgCycleTime" BO_ 592 200;
BA_ "GenMsgILSupport" BO_ 592 1;
BA_ "GenMsgCycleTimeFast" BO_ 592 50;
BA_ "GenMsgNrOfRepetition" BO_ 592 3;
BA_ "GenMsgDelayTime" BO_ 592 20;
BA_ "VFrameFormat" BO_ 592 14;

BA_ "GenSigSendType" SG_ 592 ATSFnSWReqV 0;
BA_ "SignalLongName" SG_ 592 ATSFnSWReqV "ATS Function Switch Request Valid";

BA_ "GenSigSendType" SG_ 592 ATSFnSWReq 0;
BA_ "SignalLongName" SG_ 592 ATSFnSWReq "ATS Function Switch Request";

BA_ "GenSigSendType" SG_ 592 IBDU_ESC_SW_RllCnt 0;
BA_ "SignalLongName" SG_ 592 IBDU_ESC_SW_RllCnt "IBDU_ESC_Switch Rolling Counter";

BA_ "GenSigSendType" SG_ 592 IBDU_ESC_SW_ChkSum 0;
BA_ "SignalLongName" SG_ 592 IBDU_ESC_SW_ChkSum "IBDU_ESC_Switch CheckSum";

BA_ "GenMsgSendType" BO_ 1008 0;
BA_ "GenMsgStartDelayTime" BO_ 1008 30;
BA_ "GenMsgCycleTime" BO_ 1008 500;
BA_ "GenMsgILSupport" BO_ 1008 1;
BA_ "GenMsgCycleTimeFast" BO_ 1008 40;
BA_ "GenMsgNrOfRepetition" BO_ 1008 3;
BA_ "GenMsgDelayTime" BO_ 1008 20;
BA_ "VFrameFormat" BO_ 1008 14;

BA_ "GenSigSendType" SG_ 1008 HVACAirClnrBlwrLvlReq_HMI 0;
BA_ "SignalLongName" SG_ 1008 HVACAirClnrBlwrLvlReq_HMI "HVAC Air Cleaner Blower Level Display Request_HMI";
BA_ "GenSigTimeoutValue" SG_ 1008 HVACAirClnrBlwrLvlReq_HMI 15;
BA_ "GenSigStartValue" SG_ 1008 HVACAirClnrBlwrLvlReq_HMI 7;

BA_ "GenSigSendType" SG_ 1008 HVACAirClnrBlwrLvlReqV_HMI 4;
BA_ "SignalLongName" SG_ 1008 HVACAirClnrBlwrLvlReqV_HMI "HVAC Air Cleaner Blower Level Display Request Validity_HMI";
BA_ "GenSigTimeoutValue" SG_ 1008 HVACAirClnrBlwrLvlReqV_HMI 1;
BA_ "GenSigStartValue" SG_ 1008 HVACAirClnrBlwrLvlReqV_HMI 1;

BA_ "GenSigSendType" SG_ 1008 HVACAirClnrUserCustAutoWR_HMI 0;
BA_ "SignalLongName" SG_ 1008 HVACAirClnrUserCustAutoWR_HMI "HVAC Air Cleaner User Customized Auto Work Request_HMI";

BA_ "GenSigSendType" SG_ 1008 HVACAirClnrOnOffSwReq_HMI 0;
BA_ "SignalLongName" SG_ 1008 HVACAirClnrOnOffSwReq_HMI "HVAC FICM Air Cleaner Blower On Off Switch Request_HMI";

BA_ "GenSigSendType" SG_ 1008 HVACAirClnrFltrCLRSR_HMI 0;
BA_ "SignalLongName" SG_ 1008 HVACAirClnrFltrCLRSR_HMI "HVAC FICM Air Cleaner Filter Consume Level Reset Switch Request_HMI";

BA_ "GenSigSendType" SG_ 1008 HVACAirClnrAutoSwReq_HMI 0;
BA_ "SignalLongName" SG_ 1008 HVACAirClnrAutoSwReq_HMI "HVAC FICM Air Cleaner Auto Switch Request_HMI";

BA_ "GenSigSendType" SG_ 1008 HVACAirClnrUserCustAutoWRV_HMI 4;
BA_ "SignalLongName" SG_ 1008 HVACAirClnrUserCustAutoWRV_HMI "HVAC Air Cleaner User Customized Auto Work Request Validity_HMI";
BA_ "GenSigTimeoutValue" SG_ 1008 HVACAirClnrUserCustAutoWRV_HMI 1;
BA_ "GenSigStartValue" SG_ 1008 HVACAirClnrUserCustAutoWRV_HMI 1;

BA_ "GenMsgSendType" BO_ 325 0;
BA_ "GenMsgStartDelayTime" BO_ 325 10;
BA_ "GenMsgCycleTime" BO_ 325 20;
BA_ "GenMsgILSupport" BO_ 325 1;
BA_ "VFrameFormat" BO_ 325 14;

BA_ "GenSigSendType" SG_ 325 iTurnSysDispMsgReq 0;
BA_ "SignalLongName" SG_ 325 iTurnSysDispMsgReq "iTurnSystemDisplayMessageRequest";

BA_ "GenSigSendType" SG_ 325 iTurnSts 0;
BA_ "SignalLongName" SG_ 325 iTurnSts "iTurn_Status";

BA_ "GenSigSendType" SG_ 325 CCOSysDispMsgReq 0;
BA_ "SignalLongName" SG_ 325 CCOSysDispMsgReq "CCOSystemDisplayMessageRequest";

BA_ "GenSigSendType" SG_ 325 CCOSwLamp 0;
BA_ "SignalLongName" SG_ 325 CCOSwLamp "CCOSwitchLamp";

BA_ "GenSigSendType" SG_ 325 DrSbltWarn 0;
BA_ "SignalLongName" SG_ 325 DrSbltWarn "Door&Seatbelt Warning";

BA_ "GenSigSendType" SG_ 325 EPBReWarn 0;
BA_ "SignalLongName" SG_ 325 EPBReWarn "EPB Release Warning";

BA_ "GenSigSendType" SG_ 325 OffRoadMdWarn 0;
BA_ "SignalLongName" SG_ 325 OffRoadMdWarn "Off Road Mode Warning";

BA_ "GenSigSendType" SG_ 325 ShftDWarn 0;
BA_ "SignalLongName" SG_ 325 ShftDWarn "Shift to D/M Warning";

BA_ "GenSigSendType" SG_ 325 CCOMDWarn 0;
BA_ "SignalLongName" SG_ 325 CCOMDWarn "CCO Mode Warning";

BA_ "GenSigSendType" SG_ 325 UnLEDLWarn 0;
BA_ "SignalLongName" SG_ 325 UnLEDLWarn "Unlock EDL Warning";

BA_ "GenSigSendType" SG_ 325 TrStringWarn 0;
BA_ "SignalLongName" SG_ 325 TrStringWarn "Turn the Steering to full lock Warning";

BA_ "GenMsgSendType" BO_ 1019 0;
BA_ "GenMsgStartDelayTime" BO_ 1019 10;
BA_ "GenMsgCycleTime" BO_ 1019 500;
BA_ "GenMsgILSupport" BO_ 1019 1;
BA_ "GenMsgCycleTimeFast" BO_ 1019 40;
BA_ "GenMsgNrOfRepetition" BO_ 1019 10;
BA_ "GenMsgDelayTime" BO_ 1019 20;
BA_ "VFrameFormat" BO_ 1019 14;

BA_ "GenSigSendType" SG_ 1019 EPSMdReq_FICM 4;
BA_ "SignalLongName" SG_ 1019 EPSMdReq_FICM "EPSMdReq_FICM";

BA_ "GenSigSendType" SG_ 1019 ESCMdReq_FICM 4;
BA_ "SignalLongName" SG_ 1019 ESCMdReq_FICM "ESCMdReq_FICM";

BA_ "GenSigSendType" SG_ 1019 DrvMdReq_FICM 4;
BA_ "SignalLongName" SG_ 1019 DrvMdReq_FICM "DrvMdReq_FICM";

BA_ "GenSigSendType" SG_ 1019 FICMDrvrItndHVBatSOC 4;
BA_ "SignalLongName" SG_ 1019 FICMDrvrItndHVBatSOC "Front Infotainment Control Module Driver Intended High Voltage Battery State Of Charge";
BA_ "GenSigTimeoutValue" SG_ 1019 FICMDrvrItndHVBatSOC 127;
BA_ "GenSigStartValue" SG_ 1019 FICMDrvrItndHVBatSOC 127;

BA_ "GenSigSendType" SG_ 1019 IntgltBatEngyManmtDrvModFICM 4;
BA_ "SignalLongName" SG_ 1019 IntgltBatEngyManmtDrvModFICM "Intelligent Battery Energy Management Drive Mode FICM";

BA_ "GenSigSendType" SG_ 1019 FICMDrvrItndHVBatSOCV 4;
BA_ "SignalLongName" SG_ 1019 FICMDrvrItndHVBatSOCV "Front Infotainment Control Module Driver Intended High Voltage Battery State Of Charge Validity";
BA_ "GenSigTimeoutValue" SG_ 1019 FICMDrvrItndHVBatSOCV 1;
BA_ "GenSigStartValue" SG_ 1019 FICMDrvrItndHVBatSOCV 1;

BA_ "GenSigSendType" SG_ 1019 IntgltBatEngyManmtDrvModFICMV 4;
BA_ "SignalLongName" SG_ 1019 IntgltBatEngyManmtDrvModFICMV "Intelligent Battery Energy Management Drive Mode FICM Validity";
BA_ "GenSigTimeoutValue" SG_ 1019 IntgltBatEngyManmtDrvModFICMV 1;
BA_ "GenSigStartValue" SG_ 1019 IntgltBatEngyManmtDrvModFICMV 1;

BA_ "GenMsgSendType" BO_ 1021 0;
BA_ "GenMsgStartDelayTime" BO_ 1021 25;
BA_ "GenMsgCycleTime" BO_ 1021 500;
BA_ "GenMsgILSupport" BO_ 1021 1;
BA_ "GenMsgCycleTimeFast" BO_ 1021 40;
BA_ "GenMsgNrOfRepetition" BO_ 1021 3;
BA_ "GenMsgDelayTime" BO_ 1021 20;
BA_ "VFrameFormat" BO_ 1021 14;

BA_ "GenSigSendType" SG_ 1021 FICMHourOfBatHeat 0;
BA_ "SignalLongName" SG_ 1021 FICMHourOfBatHeat "FICM Hour OF Battery Heat";

BA_ "GenSigSendType" SG_ 1021 FICMHeatReq 4;
BA_ "SignalLongName" SG_ 1021 FICMHeatReq "FICM Heat Request";

BA_ "GenSigSendType" SG_ 1021 FICMBatHeatTmV 4;
BA_ "SignalLongName" SG_ 1021 FICMBatHeatTmV "FICM Battery Heat Time Valid";

BA_ "GenSigSendType" SG_ 1021 FICMMinOfBatHeat 0;
BA_ "SignalLongName" SG_ 1021 FICMMinOfBatHeat "FICM Minute OF Battery Heat";

BA_ "GenSigSendType" SG_ 1021 FICMInnerV2LReq 4;
BA_ "SignalLongName" SG_ 1021 FICMInnerV2LReq "FrontInfotainmentControlModuleinnerV2L Request";

BA_ "GenSigSendType" SG_ 1021 FICMInnerV2LKeepTimeReq 4;
BA_ "SignalLongName" SG_ 1021 FICMInnerV2LKeepTimeReq "FICMInnerV2LKeepTimeRequest";

BA_ "GenSigSendType" SG_ 1021 FuelModSw 0;
BA_ "SignalLongName" SG_ 1021 FuelModSw "FuelModeSwitch";

BA_ "GenSigSendType" SG_ 1021 FICMPeriodOfBatHeatSunday 0;
BA_ "SignalLongName" SG_ 1021 FICMPeriodOfBatHeatSunday "FICM Battery Heat Period Sunday";

BA_ "GenSigSendType" SG_ 1021 FICMPeriodOfBatHeatMonday 0;
BA_ "SignalLongName" SG_ 1021 FICMPeriodOfBatHeatMonday "FICM Battery Heat Period Monday";

BA_ "GenSigSendType" SG_ 1021 FICMPeriodOfBatHeatTuesday 0;
BA_ "SignalLongName" SG_ 1021 FICMPeriodOfBatHeatTuesday "FICM Battery Heat Period Tuesday";

BA_ "GenSigSendType" SG_ 1021 FICMPeriodOfBatHeatWednesday 0;
BA_ "SignalLongName" SG_ 1021 FICMPeriodOfBatHeatWednesday "FICM Battery Heat Period Wednesday";

BA_ "GenSigSendType" SG_ 1021 FICMPeriodOfBatHeatThursday 0;
BA_ "SignalLongName" SG_ 1021 FICMPeriodOfBatHeatThursday "FICM Battery Heat Period Thursday";

BA_ "GenSigSendType" SG_ 1021 FICMPeriodOfBatHeatFriday 0;
BA_ "SignalLongName" SG_ 1021 FICMPeriodOfBatHeatFriday "FICM Battery Heat Period Friday";

BA_ "GenSigSendType" SG_ 1021 FICMPeriodOfBatHeatSaturday 0;
BA_ "SignalLongName" SG_ 1021 FICMPeriodOfBatHeatSaturday "FICM Battery Heat Period Saturday";

BA_ "GenSigSendType" SG_ 1021 FICMPeriodOfBatHeatRepeat 0;
BA_ "SignalLongName" SG_ 1021 FICMPeriodOfBatHeatRepeat "FICM Battery Heat Period Repeat";

BA_ "GenSigSendType" SG_ 1021 FICMHourOfBatHeat1 0;
BA_ "SignalLongName" SG_ 1021 FICMHourOfBatHeat1 "FICM Hour OF Battery Heat 1";

BA_ "GenSigSendType" SG_ 1021 FICMHeatReq1 4;
BA_ "SignalLongName" SG_ 1021 FICMHeatReq1 "FICM Heat Request 1";

BA_ "GenSigSendType" SG_ 1021 FICMBatHeatTmV1 4;
BA_ "SignalLongName" SG_ 1021 FICMBatHeatTmV1 "FICM Battery Heat Time Valid 1";

BA_ "GenSigSendType" SG_ 1021 FICMMinOfBatHeat1 0;
BA_ "SignalLongName" SG_ 1021 FICMMinOfBatHeat1 "FICM Minute OF Battery Heat 1";

BA_ "GenSigSendType" SG_ 1021 EnStrtRequest_V2L 4;

BA_ "GenSigSendType" SG_ 1021 FICMV2XSpSOCReqExt 4;
BA_ "SignalLongName" SG_ 1021 FICMV2XSpSOCReqExt "Front_Infotainment_Control_Module_V2X_Stop_State_Of_Charge_Request_Extend";
BA_ "GenSigStartValue" SG_ 1021 FICMV2XSpSOCReqExt 127;

BA_ "GenSigSendType" SG_ 1021 FICMPeriodOfBatHeatSunday1 0;
BA_ "SignalLongName" SG_ 1021 FICMPeriodOfBatHeatSunday1 "FICM Battery Heat Period Sunday 1";

BA_ "GenSigSendType" SG_ 1021 FICMPeriodOfBatHeatMonday1 0;
BA_ "SignalLongName" SG_ 1021 FICMPeriodOfBatHeatMonday1 "FICM Battery Heat Period Monday 1";

BA_ "GenSigSendType" SG_ 1021 FICMPeriodOfBatHeatTuesday1 0;
BA_ "SignalLongName" SG_ 1021 FICMPeriodOfBatHeatTuesday1 "FICM Battery Heat Period Tuesday 1";

BA_ "GenSigSendType" SG_ 1021 FICMPeriodOfBatHeatWednesday1 0;
BA_ "SignalLongName" SG_ 1021 FICMPeriodOfBatHeatWednesday1 "FICM Battery Heat Period Wednesday 1";

BA_ "GenSigSendType" SG_ 1021 FICMPeriodOfBatHeatThursday1 0;
BA_ "SignalLongName" SG_ 1021 FICMPeriodOfBatHeatThursday1 "FICM Battery Heat Period Thursday 1";

BA_ "GenSigSendType" SG_ 1021 FICMPeriodOfBatHeatFriday1 0;
BA_ "SignalLongName" SG_ 1021 FICMPeriodOfBatHeatFriday1 "FICM Battery Heat Period Friday 1";

BA_ "GenSigSendType" SG_ 1021 FICMPeriodOfBatHeatSaturday1 0;
BA_ "SignalLongName" SG_ 1021 FICMPeriodOfBatHeatSaturday1 "FICM Battery Heat Period Saturday 1";

BA_ "GenSigSendType" SG_ 1021 FICMPeriodOfBatHeatRepeat1 0;
BA_ "SignalLongName" SG_ 1021 FICMPeriodOfBatHeatRepeat1 "FICM Battery Heat Period Repeat 1";

BA_ "GenMsgSendType" BO_ 1022 0;
BA_ "GenMsgStartDelayTime" BO_ 1022 25;
BA_ "GenMsgCycleTime" BO_ 1022 500;
BA_ "GenMsgILSupport" BO_ 1022 1;
BA_ "VFrameFormat" BO_ 1022 14;

BA_ "GenSigSendType" SG_ 1022 ICGMHourOfBatHeat 0;
BA_ "SignalLongName" SG_ 1022 ICGMHourOfBatHeat "ICGM Hour OF Battery Heat";

BA_ "GenSigSendType" SG_ 1022 BatHeatOrdStatus 0;
BA_ "SignalLongName" SG_ 1022 BatHeatOrdStatus "Battery Heat Order Status";

BA_ "GenSigSendType" SG_ 1022 ICGMMinOfBatHeat 0;
BA_ "SignalLongName" SG_ 1022 ICGMMinOfBatHeat "ICGM Minute OF Battery Heat";

BA_ "GenSigSendType" SG_ 1022 ICGMPeriodOfBatHeatSunday 0;
BA_ "SignalLongName" SG_ 1022 ICGMPeriodOfBatHeatSunday "ICGM Battery Heat Period Sunday";

BA_ "GenSigSendType" SG_ 1022 ICGMPeriodOfBatHeatMonday 0;
BA_ "SignalLongName" SG_ 1022 ICGMPeriodOfBatHeatMonday "ICGM Battery Heat Period Monday";

BA_ "GenSigSendType" SG_ 1022 ICGMPeriodOfBatHeatTuesday 0;
BA_ "SignalLongName" SG_ 1022 ICGMPeriodOfBatHeatTuesday "ICGM Battery Heat Period Tuesday";

BA_ "GenSigSendType" SG_ 1022 ICGMPeriodOfBatHeatWednesday 0;
BA_ "SignalLongName" SG_ 1022 ICGMPeriodOfBatHeatWednesday "ICGM Battery Heat Period Wednesday";

BA_ "GenSigSendType" SG_ 1022 ICGMPeriodOfBatHeatThursday 0;
BA_ "SignalLongName" SG_ 1022 ICGMPeriodOfBatHeatThursday "ICGM Battery Heat Period Thursday";

BA_ "GenSigSendType" SG_ 1022 ICGMPeriodOfBatHeatFriday 0;
BA_ "SignalLongName" SG_ 1022 ICGMPeriodOfBatHeatFriday "ICGM Battery Heat Period Friday";

BA_ "GenSigSendType" SG_ 1022 ICGMPeriodOfBatHeatSaturday 0;
BA_ "SignalLongName" SG_ 1022 ICGMPeriodOfBatHeatSaturday "ICGM Battery Heat Period Saturday";

BA_ "GenSigSendType" SG_ 1022 ICGMPeriodOfBatHeatRepeat 0;
BA_ "SignalLongName" SG_ 1022 ICGMPeriodOfBatHeatRepeat "ICGM Battery Heat Period Repeat";

BA_ "GenSigSendType" SG_ 1022 ICGMHourOfBatHeat1 0;
BA_ "SignalLongName" SG_ 1022 ICGMHourOfBatHeat1 "ICGM Hour OF Battery Heat 1";

BA_ "GenSigSendType" SG_ 1022 BatHeatOrdStatus1 0;
BA_ "SignalLongName" SG_ 1022 BatHeatOrdStatus1 "Battery Heat Order Status 1";

BA_ "GenSigSendType" SG_ 1022 ICGMMinOfBatHeat1 0;
BA_ "SignalLongName" SG_ 1022 ICGMMinOfBatHeat1 "ICGM Minute OF Battery Heat 1";

BA_ "GenSigSendType" SG_ 1022 ICGMPeriodOfBatHeatSunday1 0;
BA_ "SignalLongName" SG_ 1022 ICGMPeriodOfBatHeatSunday1 "ICGM Battery Heat Period Sunday 1";

BA_ "GenSigSendType" SG_ 1022 ICGMPeriodOfBatHeatMonday1 0;
BA_ "SignalLongName" SG_ 1022 ICGMPeriodOfBatHeatMonday1 "ICGM Battery Heat Period Monday 1";

BA_ "GenSigSendType" SG_ 1022 ICGMPeriodOfBatHeatTuesday1 0;
BA_ "SignalLongName" SG_ 1022 ICGMPeriodOfBatHeatTuesday1 "ICGM Battery Heat Period Tuesday 1";

BA_ "GenSigSendType" SG_ 1022 ICGMPeriodOfBatHeatWednesday1 0;
BA_ "SignalLongName" SG_ 1022 ICGMPeriodOfBatHeatWednesday1 "ICGM Battery Heat Period Wednesday 1";

BA_ "GenSigSendType" SG_ 1022 ICGMPeriodOfBatHeatThursday1 0;
BA_ "SignalLongName" SG_ 1022 ICGMPeriodOfBatHeatThursday1 "ICGM Battery Heat Period Thursday 1";

BA_ "GenSigSendType" SG_ 1022 ICGMPeriodOfBatHeatFriday1 0;
BA_ "SignalLongName" SG_ 1022 ICGMPeriodOfBatHeatFriday1 "ICGM Battery Heat Period Friday 1";

BA_ "GenSigSendType" SG_ 1022 ICGMPeriodOfBatHeatSaturday1 0;
BA_ "SignalLongName" SG_ 1022 ICGMPeriodOfBatHeatSaturday1 "ICGM Battery Heat Period Saturday 1";

BA_ "GenSigSendType" SG_ 1022 ICGMPeriodOfBatHeatRepeat1 0;
BA_ "SignalLongName" SG_ 1022 ICGMPeriodOfBatHeatRepeat1 "ICGM Battery Heat Period Repeat 1";

BA_ "GenMsgSendType" BO_ 812 0;
BA_ "GenMsgStartDelayTime" BO_ 812 5;
BA_ "GenMsgCycleTime" BO_ 812 100;
BA_ "GenMsgILSupport" BO_ 812 1;
BA_ "VFrameFormat" BO_ 812 14;

BA_ "GenSigSendType" SG_ 812 FICMReserCtrlReq 0;
BA_ "SignalLongName" SG_ 812 FICMReserCtrlReq "Front_Infotainment_Control_Module_Reservation_Control_Request";

BA_ "GenSigSendType" SG_ 812 FICMChrgTrgtSOCReq 0;
BA_ "SignalLongName" SG_ 812 FICMChrgTrgtSOCReq "Front_Infotainment_Control_Module_Onboard_Charge_Target_State_Of_Charge_Request";

BA_ "GenSigSendType" SG_ 812 FICMAltngChrgCrntReq 0;
BA_ "SignalLongName" SG_ 812 FICMAltngChrgCrntReq "Front_Infotainment_Control_Module_Alternating_Charge_Current_Request";

BA_ "GenSigSendType" SG_ 812 FICMReserSpHour 0;
BA_ "SignalLongName" SG_ 812 FICMReserSpHour "Front Infotainment Control Module Reservation Start Late Hour";
BA_ "GenSigTimeoutValue" SG_ 812 FICMReserSpHour 30;
BA_ "GenSigStartValue" SG_ 812 FICMReserSpHour 30;

BA_ "GenSigSendType" SG_ 812 FICMV2XSpSOCReq 0;
BA_ "SignalLongName" SG_ 812 FICMV2XSpSOCReq "Front_Infotainment_Control_Module_V2x_Stop_State_Of_Charge_Request";

BA_ "GenSigSendType" SG_ 812 FICMReserSpMinute 0;
BA_ "SignalLongName" SG_ 812 FICMReserSpMinute "Front Infotainment Control Module Reservation Start Late Minute";
BA_ "GenSigTimeoutValue" SG_ 812 FICMReserSpMinute 62;
BA_ "GenSigStartValue" SG_ 812 FICMReserSpMinute 62;

BA_ "GenSigSendType" SG_ 812 FICMReserStHour 0;
BA_ "SignalLongName" SG_ 812 FICMReserStHour "Front Infotainment Control Module Reservation Start Early Hour";
BA_ "GenSigTimeoutValue" SG_ 812 FICMReserStHour 30;
BA_ "GenSigStartValue" SG_ 812 FICMReserStHour 30;

BA_ "GenSigSendType" SG_ 812 FICMReserStMinute 0;
BA_ "SignalLongName" SG_ 812 FICMReserStMinute "Front Infotainment Control Module Reservation Start Early Minute";
BA_ "GenSigTimeoutValue" SG_ 812 FICMReserStMinute 62;
BA_ "GenSigStartValue" SG_ 812 FICMReserStMinute 62;

BA_ "GenMsgSendType" BO_ 704 0;
BA_ "GenMsgStartDelayTime" BO_ 704 5;
BA_ "GenMsgCycleTime" BO_ 704 50;
BA_ "GenMsgILSupport" BO_ 704 1;
BA_ "VFrameFormat" BO_ 704 14;

BA_ "GenSigSendType" SG_ 704 IMCUBaaSOvduDay 0;
BA_ "SignalLongName" SG_ 704 IMCUBaaSOvduDay "Intelligent Motor Control Unit Battery as a Service Overdue Day";

BA_ "GenSigSendType" SG_ 704 BaaSBatIlglAlrm 0;
BA_ "SignalLongName" SG_ 704 BaaSBatIlglAlrm "Battery as a Service Battery Illegal Alarm";
BA_ "GenSigTimeoutValue" SG_ 704 BaaSBatIlglAlrm 1;
BA_ "GenSigStartValue" SG_ 704 BaaSBatIlglAlrm 1;

BA_ "GenSigSendType" SG_ 704 IMCUAlrmDspForBaaS 0;
BA_ "SignalLongName" SG_ 704 IMCUAlrmDspForBaaS "Intelligent Motor Control Unit Alarm Display For Battery as a Service";

BA_ "GenMsgSendType" BO_ 755 0;
BA_ "GenMsgStartDelayTime" BO_ 755 5;
BA_ "GenMsgCycleTime" BO_ 755 100;
BA_ "GenMsgILSupport" BO_ 755 1;
BA_ "VFrameFormat" BO_ 755 14;

BA_ "GenSigSendType" SG_ 755 IMCUChrgTrgtSOCDspCmd 0;
BA_ "SignalLongName" SG_ 755 IMCUChrgTrgtSOCDspCmd "IMCU Charge Target State Of Charge Display Command";

BA_ "GenSigSendType" SG_ 755 IMCUReserCtrlDspCmd 0;
BA_ "SignalLongName" SG_ 755 IMCUReserCtrlDspCmd "Reservation Control Display Command";

BA_ "GenSigSendType" SG_ 755 IMCUReserChrgCtrlResp 0;
BA_ "SignalLongName" SG_ 755 IMCUReserChrgCtrlResp "Reservation Charge Control Response";

BA_ "GenSigSendType" SG_ 755 IMCUChrgTrgtSOCResp 0;
BA_ "SignalLongName" SG_ 755 IMCUChrgTrgtSOCResp "IMCU Charge Target Soc Response";

BA_ "GenSigSendType" SG_ 755 IMCUReserSpMinuteDspCmd 0;
BA_ "SignalLongName" SG_ 755 IMCUReserSpMinuteDspCmd "Reservation Stop Minute Display Command";
BA_ "GenSigTimeoutValue" SG_ 755 IMCUReserSpMinuteDspCmd 62;
BA_ "GenSigStartValue" SG_ 755 IMCUReserSpMinuteDspCmd 62;

BA_ "GenSigSendType" SG_ 755 IMCUReserStMinuteDspCmd 0;
BA_ "SignalLongName" SG_ 755 IMCUReserStMinuteDspCmd "Reservation Start Minute Display Command";
BA_ "GenSigTimeoutValue" SG_ 755 IMCUReserStMinuteDspCmd 62;
BA_ "GenSigStartValue" SG_ 755 IMCUReserStMinuteDspCmd 62;

BA_ "GenSigSendType" SG_ 755 IMCUReserSpHourDspCmd 0;
BA_ "SignalLongName" SG_ 755 IMCUReserSpHourDspCmd "Reservation Stop Hour Display Command";
BA_ "GenSigTimeoutValue" SG_ 755 IMCUReserSpHourDspCmd 30;
BA_ "GenSigStartValue" SG_ 755 IMCUReserSpHourDspCmd 30;

BA_ "GenSigSendType" SG_ 755 IMCUReserStHourDspCmd 0;
BA_ "SignalLongName" SG_ 755 IMCUReserStHourDspCmd "Reservation Start Hour Display Command";
BA_ "GenSigTimeoutValue" SG_ 755 IMCUReserStHourDspCmd 30;
BA_ "GenSigStartValue" SG_ 755 IMCUReserStHourDspCmd 30;

BA_ "GenMsgSendType" BO_ 777 0;
BA_ "GenMsgStartDelayTime" BO_ 777 5;
BA_ "GenMsgCycleTime" BO_ 777 100;
BA_ "GenMsgILSupport" BO_ 777 1;
BA_ "VFrameFormat" BO_ 777 14;

BA_ "GenSigSendType" SG_ 777 CCUOffBdChrgrPlugOnV 0;
BA_ "SignalLongName" SG_ 777 CCUOffBdChrgrPlugOnV "Combined Charging Unit Off Board Charger Plug On Validity";
BA_ "GenSigTimeoutValue" SG_ 777 CCUOffBdChrgrPlugOnV 1;
BA_ "GenSigStartValue" SG_ 777 CCUOffBdChrgrPlugOnV 1;

BA_ "GenSigSendType" SG_ 777 CCUOffBdChrgrPlugOn 0;
BA_ "SignalLongName" SG_ 777 CCUOffBdChrgrPlugOn "Combined Charging Unit Off Board Charger Plug On";

BA_ "GenMsgSendType" BO_ 805 0;
BA_ "GenMsgStartDelayTime" BO_ 805 5;
BA_ "GenMsgCycleTime" BO_ 805 100;
BA_ "GenMsgILSupport" BO_ 805 1;
BA_ "VFrameFormat" BO_ 805 14;

BA_ "GenSigSendType" SG_ 805 IMCUDschrgngEstdElecRngV 0;
BA_ "SignalLongName" SG_ 805 IMCUDschrgngEstdElecRngV "Discharging Estimated Electric Range Validity";
BA_ "GenSigTimeoutValue" SG_ 805 IMCUDschrgngEstdElecRngV 1;
BA_ "GenSigStartValue" SG_ 805 IMCUDschrgngEstdElecRngV 1;

BA_ "GenSigSendType" SG_ 805 IMCUDschrgngEstdElecRng 0;
BA_ "SignalLongName" SG_ 805 IMCUDschrgngEstdElecRng "Discharging Estimated Electric Range";
BA_ "GenSigTimeoutValue" SG_ 805 IMCUDschrgngEstdElecRng 4095;
BA_ "GenSigStartValue" SG_ 805 IMCUDschrgngEstdElecRng 4095;

BA_ "GenSigSendType" SG_ 805 IMCUChrgSttnMchngStaResp 0;
BA_ "SignalLongName" SG_ 805 IMCUChrgSttnMchngStaResp "Charge Station Matching State Response";

BA_ "GenSigSendType" SG_ 805 IMCUAltngChrgCrntResp 0;
BA_ "SignalLongName" SG_ 805 IMCUAltngChrgCrntResp "IMCU Alternating Charge Current Response";

BA_ "GenSigSendType" SG_ 805 IMCUAltngChrgCrntDspCmd 0;
BA_ "SignalLongName" SG_ 805 IMCUAltngChrgCrntDspCmd "IMCU Alternating Charge Current Display Command";

BA_ "GenSigSendType" SG_ 805 IMCUDschrgTrgtSOCDspCmd 0;
BA_ "SignalLongName" SG_ 805 IMCUDschrgTrgtSOCDspCmd "IMCUDischargeTargetStateOfChargeDisplayCommand";

BA_ "GenMsgSendType" BO_ 884 0;
BA_ "GenMsgStartDelayTime" BO_ 884 5;
BA_ "GenMsgCycleTime" BO_ 884 100;
BA_ "GenMsgILSupport" BO_ 884 1;
BA_ "VFrameFormat" BO_ 884 14;

BA_ "GenSigSendType" SG_ 884 ESSSwapOpDsp 0;
BA_ "SignalLongName" SG_ 884 ESSSwapOpDsp "Energy Storage System Swap Operation Display";

BA_ "GenMsgSendType" BO_ 871 0;
BA_ "GenMsgStartDelayTime" BO_ 871 5;
BA_ "GenMsgCycleTime" BO_ 871 100;
BA_ "GenMsgILSupport" BO_ 871 1;
BA_ "VFrameFormat" BO_ 871 14;

BA_ "GenSigSendType" SG_ 871 SttnESSSwapSta 0;
BA_ "SignalLongName" SG_ 871 SttnESSSwapSta "Station Energy Storage System Swap State";
BA_ "GenSigTimeoutValue" SG_ 871 SttnESSSwapSta 15;
BA_ "GenSigStartValue" SG_ 871 SttnESSSwapSta 15;

BA_ "GenSigSendType" SG_ 871 ESSSwapSttnAndVehComSta 0;
BA_ "SignalLongName" SG_ 871 ESSSwapSttnAndVehComSta "Energy Storage System Swap Station and Vehicle Communication State";

BA_ "GenSigSendType" SG_ 871 ESSSwapVehInSwapArea 0;
BA_ "SignalLongName" SG_ 871 ESSSwapVehInSwapArea "Energy Storage System Swap vehicle in swap area";

BA_ "GenMsgSendType" BO_ 1006 0;
BA_ "GenMsgStartDelayTime" BO_ 1006 5;
BA_ "GenMsgCycleTime" BO_ 1006 100;
BA_ "GenMsgILSupport" BO_ 1006 1;
BA_ "VFrameFormat" BO_ 1006 14;

BA_ "GenSigSendType" SG_ 1006 FICMChrgCtrlReq 0;
BA_ "SignalLongName" SG_ 1006 FICMChrgCtrlReq "Front_Infotainment_Control_Module_Charge_Control_Request";

BA_ "GenSigSendType" SG_ 1006 FICMOnRutWarmOffReq 0;
BA_ "SignalLongName" SG_ 1006 FICMOnRutWarmOffReq "FICM On Route Warm Off Request";

BA_ "GenSigSendType" SG_ 1006 FICMChrgSttnMchngSta 0;
BA_ "SignalLongName" SG_ 1006 FICMChrgSttnMchngSta "Front Infotainment Control Module Charge Station Matching State";
BA_ "GenSigTimeoutValue" SG_ 1006 FICMChrgSttnMchngSta 1;
BA_ "GenSigStartValue" SG_ 1006 FICMChrgSttnMchngSta 1;

BA_ "GenSigSendType" SG_ 1006 FICMEleccLckCtrlReq 0;
BA_ "SignalLongName" SG_ 1006 FICMEleccLckCtrlReq "Front_Infotainment_Control_Module_Electronic_Lock_Control_Request";

BA_ "GenSigSendType" SG_ 1006 DsttnTypOfNav 0;
BA_ "SignalLongName" SG_ 1006 DsttnTypOfNav "Destination_Type_Of_Navigation";

BA_ "GenSigSendType" SG_ 1006 FICMOnRutWarmOffReqV 0;
BA_ "SignalLongName" SG_ 1006 FICMOnRutWarmOffReqV "FICM On Route Warm Off Request Valid";
BA_ "GenSigTimeoutValue" SG_ 1006 FICMOnRutWarmOffReqV 1;
BA_ "GenSigStartValue" SG_ 1006 FICMOnRutWarmOffReqV 1;

BA_ "GenSigSendType" SG_ 1006 NavGudcSts 0;
BA_ "SignalLongName" SG_ 1006 NavGudcSts "Navigation_Guidance_Status";

BA_ "GenSigSendType" SG_ 1006 DistToDsttnNav 0;
BA_ "SignalLongName" SG_ 1006 DistToDsttnNav "Distance_To_Destination_Navigation";
BA_ "GenSigTimeoutValue" SG_ 1006 DistToDsttnNav 1023;
BA_ "GenSigStartValue" SG_ 1006 DistToDsttnNav 1023;

BA_ "GenSigSendType" SG_ 1006 ChrgngSttnCapctOfDsttnNav 0;
BA_ "SignalLongName" SG_ 1006 ChrgngSttnCapctOfDsttnNav "Charging_Station_Capacity_Of_Destination_Navigation";

BA_ "GenSigSendType" SG_ 1006 FICMV2XReq 0;
BA_ "SignalLongName" SG_ 1006 FICMV2XReq "FrontInfotainmentControlModuleV2xRequest";

BA_ "GenSigSendType" SG_ 1006 GudTimeToDsttnNav 0;
BA_ "SignalLongName" SG_ 1006 GudTimeToDsttnNav "Guide_Time_To_Destination_Navigation";

BA_ "GenMsgSendType" BO_ 816 0;
BA_ "GenMsgStartDelayTime" BO_ 816 20;
BA_ "GenMsgCycleTime" BO_ 816 200;
BA_ "GenMsgILSupport" BO_ 816 1;
BA_ "VFrameFormat" BO_ 816 14;

BA_ "GenSigSendType" SG_ 816 AirSuspUpSts 0;
BA_ "SignalLongName" SG_ 816 AirSuspUpSts "AirSuspensionUpStatus";

BA_ "GenSigSendType" SG_ 816 AirSuspDnSts 0;
BA_ "SignalLongName" SG_ 816 AirSuspDnSts "AirSuspensionDownStatus";

BA_ "GenSigSendType" SG_ 816 AirSuspHtSetBtnSts 0;
BA_ "SignalLongName" SG_ 816 AirSuspHtSetBtnSts "AirSuspensionHeightSetButtonStatus";

BA_ "GenSigSendType" SG_ 816 AirSuspHeightSts 0;
BA_ "SignalLongName" SG_ 816 AirSuspHeightSts "Air Suspension Height Staus";

BA_ "GenSigSendType" SG_ 816 FxdMdSetReqFedbk 0;
BA_ "SignalLongName" SG_ 816 FxdMdSetReqFedbk "FixedModeSetRequestFeedback";

BA_ "GenSigSendType" SG_ 816 ECASFctyDeftSetFnd 0;
BA_ "SignalLongName" SG_ 816 ECASFctyDeftSetFnd "ECASFactoryDefaultSettingFinished";

BA_ "GenSigSendType" SG_ 816 VehRrAxlWgt 0;
BA_ "SignalLongName" SG_ 816 VehRrAxlWgt "VehicleRearAxleWeight";

BA_ "GenMsgSendType" BO_ 762 0;
BA_ "GenMsgStartDelayTime" BO_ 762 10;
BA_ "GenMsgCycleTime" BO_ 762 150;
BA_ "GenMsgILSupport" BO_ 762 1;
BA_ "VFrameFormat" BO_ 762 14;

BA_ "GenSigSendType" SG_ 762 RFGOprtSts 0;
BA_ "SignalLongName" SG_ 762 RFGOprtSts "Refrigerator Operation Status";
BA_ "GenSigTimeoutValue" SG_ 762 RFGOprtSts 3;
BA_ "GenSigStartValue" SG_ 762 RFGOprtSts 3;

BA_ "GenSigSendType" SG_ 762 RFGTrgtTemp 0;
BA_ "SignalLongName" SG_ 762 RFGTrgtTemp "Refrigerator Target Temperature";
BA_ "GenSigTimeoutValue" SG_ 762 RFGTrgtTemp 63;
BA_ "GenSigStartValue" SG_ 762 RFGTrgtTemp 63;

BA_ "GenSigSendType" SG_ 762 RFGOprtEndRsn 0;
BA_ "SignalLongName" SG_ 762 RFGOprtEndRsn "Refrigerator Operation End Reason";
BA_ "GenSigTimeoutValue" SG_ 762 RFGOprtEndRsn 15;
BA_ "GenSigStartValue" SG_ 762 RFGOprtEndRsn 15;

BA_ "GenSigSendType" SG_ 762 RFGOprtMdSts 0;
BA_ "SignalLongName" SG_ 762 RFGOprtMdSts "Refrigerator Operation Mode Status";
BA_ "GenSigTimeoutValue" SG_ 762 RFGOprtMdSts 3;
BA_ "GenSigStartValue" SG_ 762 RFGOprtMdSts 3;

BA_ "GenSigSendType" SG_ 762 RFGEngOffOprtSetSts 0;
BA_ "SignalLongName" SG_ 762 RFGEngOffOprtSetSts "Refrigerator Engine off Operation Set Status";

BA_ "GenSigSendType" SG_ 762 RFGEngOffOprtDur 0;
BA_ "SignalLongName" SG_ 762 RFGEngOffOprtDur "Refrigerator Engine off Operation Duration";
BA_ "GenSigTimeoutValue" SG_ 762 RFGEngOffOprtDur 31;
BA_ "GenSigStartValue" SG_ 762 RFGEngOffOprtDur 31;

BA_ "GenSigSendType" SG_ 762 RCPSWEnblSts 0;
BA_ "SignalLongName" SG_ 762 RCPSWEnblSts "RCP Switch Enable Status";

BA_ "GenMsgSendType" BO_ 967 0;
BA_ "GenMsgStartDelayTime" BO_ 967 10;
BA_ "GenMsgCycleTime" BO_ 967 100;
BA_ "GenMsgILSupport" BO_ 967 1;
BA_ "VFrameFormat" BO_ 967 14;

BA_ "GenSigSendType" SG_ 967 InnerDsChrgPlug 0;
BA_ "SignalLongName" SG_ 967 InnerDsChrgPlug "Inner DsCharging Plug";

BA_ "GenSigSendType" SG_ 967 InnerDsChrgPlugV 0;
BA_ "SignalLongName" SG_ 967 InnerDsChrgPlugV "Inner DsCharging PlugValidity";

BA_ "GenSigSendType" SG_ 967 IBDUInnerDsChrgPlugTmpWrn 0;
BA_ "SignalLongName" SG_ 967 IBDUInnerDsChrgPlugTmpWrn "Inner DsCharging Plug Temperature Warning";

BA_ "GenMsgSendType" BO_ 994 0;
BA_ "GenMsgStartDelayTime" BO_ 994 30;
BA_ "GenMsgCycleTime" BO_ 994 500;
BA_ "GenMsgILSupport" BO_ 994 1;
BA_ "VFrameFormat" BO_ 994 14;

BA_ "GenSigSendType" SG_ 994 TirePrs_RLOS 0;
BA_ "SignalLongName" SG_ 994 TirePrs_RLOS "Tire Pressure_ Rear Left Outer Sensor";

BA_ "GenSigSendType" SG_ 994 TirePrs_RROS 0;
BA_ "SignalLongName" SG_ 994 TirePrs_RROS "Tire Pressure_ Rear Right Outer Sensor";

BA_ "GenSigSendType" SG_ 994 TireTmp_RLOS 0;
BA_ "SignalLongName" SG_ 994 TireTmp_RLOS "Tire Temprature_Rear Left Outer Sensor";

BA_ "GenSigSendType" SG_ 994 TireTmp_RROS 0;
BA_ "SignalLongName" SG_ 994 TireTmp_RROS "Tire Temprature_Rear Right Outer Sensor";

BA_ "GenMsgSendType" BO_ 902 0;
BA_ "GenMsgStartDelayTime" BO_ 902 30;
BA_ "GenMsgCycleTime" BO_ 902 500;
BA_ "GenMsgILSupport" BO_ 902 1;
BA_ "GenMsgCycleTimeFast" BO_ 902 40;
BA_ "GenMsgNrOfRepetition" BO_ 902 3;
BA_ "GenMsgDelayTime" BO_ 902 20;
BA_ "VFrameFormat" BO_ 902 14;

BA_ "GenSigSendType" SG_ 902 StDirSts_PR 4;
BA_ "SignalLongName" SG_ 902 StDirSts_PR "Seat Direction Status_SCM_PR";

BA_ "GenSigSendType" SG_ 902 StTrkPos_PR2 0;
BA_ "SignalLongName" SG_ 902 StTrkPos_PR2 "Seat Track Position_SCM_PR";
BA_ "GenSigTimeoutValue" SG_ 902 StTrkPos_PR2 127;
BA_ "GenSigStartValue" SG_ 902 StTrkPos_PR2 127;

BA_ "GenSigSendType" SG_ 902 StTurnPos_PR 0;
BA_ "SignalLongName" SG_ 902 StTurnPos_PR "Seat Turn Position_SCM_PR";
BA_ "GenSigTimeoutValue" SG_ 902 StTurnPos_PR 127;
BA_ "GenSigStartValue" SG_ 902 StTurnPos_PR 127;

BA_ "GenSigSendType" SG_ 902 StRtaPos_PR2 0;
BA_ "SignalLongName" SG_ 902 StRtaPos_PR2 "Seat Rotation Position_SCM_PR";
BA_ "GenSigTimeoutValue" SG_ 902 StRtaPos_PR2 127;
BA_ "GenSigStartValue" SG_ 902 StRtaPos_PR2 127;

BA_ "GenSigSendType" SG_ 902 StLgRtaPos_PR 0;
BA_ "SignalLongName" SG_ 902 StLgRtaPos_PR "Seat Legsupport Rotation Position_SCM_PR";
BA_ "GenSigTimeoutValue" SG_ 902 StLgRtaPos_PR 127;
BA_ "GenSigStartValue" SG_ 902 StLgRtaPos_PR 127;

BA_ "GenSigSendType" SG_ 902 StHtSts_PR2 0;
BA_ "SignalLongName" SG_ 902 StHtSts_PR2 "Seat Heat Status_PR2";

BA_ "GenMsgSendType" BO_ 903 0;
BA_ "GenMsgStartDelayTime" BO_ 903 30;
BA_ "GenMsgCycleTime" BO_ 903 500;
BA_ "GenMsgILSupport" BO_ 903 1;
BA_ "GenMsgCycleTimeFast" BO_ 903 40;
BA_ "GenMsgNrOfRepetition" BO_ 903 3;
BA_ "GenMsgDelayTime" BO_ 903 20;
BA_ "VFrameFormat" BO_ 903 14;

BA_ "GenSigSendType" SG_ 903 StRtaRmndReq_PR 4;
BA_ "SignalLongName" SG_ 903 StRtaRmndReq_PR "Seat Rotate Reminder Request_SCM_PR";

BA_ "GenMsgSendType" BO_ 870 0;
BA_ "GenMsgStartDelayTime" BO_ 870 10;
BA_ "GenMsgCycleTime" BO_ 870 200;
BA_ "GenMsgILSupport" BO_ 870 1;
BA_ "VFrameFormat" BO_ 870 14;

BA_ "GenSigSendType" SG_ 870 CldrYr_UTC 0;
BA_ "SignalLongName" SG_ 870 CldrYr_UTC "Calendar Year Coordinated Universal Time";

BA_ "GenSigSendType" SG_ 870 CldrMth_UTC 0;
BA_ "SignalLongName" SG_ 870 CldrMth_UTC "Calendar Month Coordinated Universal Time";

BA_ "GenSigSendType" SG_ 870 CldrDay_UTC 0;
BA_ "SignalLongName" SG_ 870 CldrDay_UTC "Calendar Day Coordinated Universal Time";

BA_ "GenSigSendType" SG_ 870 HrofDay_UTC 0;
BA_ "SignalLongName" SG_ 870 HrofDay_UTC "HourOfDay Coordinated Universal Time";

BA_ "GenSigSendType" SG_ 870 MinofHr_UTC 0;
BA_ "SignalLongName" SG_ 870 MinofHr_UTC "MinuteOfHour Coordinated Universal Time";

BA_ "GenSigSendType" SG_ 870 CldV_UTC 0;
BA_ "SignalLongName" SG_ 870 CldV_UTC "iCGMCalendarValid Coordinated Universal Time";

BA_ "GenSigSendType" SG_ 870 DayV_UTC 0;
BA_ "SignalLongName" SG_ 870 DayV_UTC "iCGMDayValid Coordinated Universal Time";

BA_ "GenSigSendType" SG_ 870 SecofMin_UTC 0;
BA_ "SignalLongName" SG_ 870 SecofMin_UTC "SecsOfMinute Coordinated Universal Time";

BA_ "GenMsgSendType" BO_ 927 0;
BA_ "GenMsgStartDelayTime" BO_ 927 15;
BA_ "GenMsgCycleTime" BO_ 927 500;
BA_ "GenMsgILSupport" BO_ 927 1;
BA_ "GenMsgCycleTimeFast" BO_ 927 40;
BA_ "GenMsgNrOfRepetition" BO_ 927 3;
BA_ "GenMsgDelayTime" BO_ 927 20;
BA_ "VFrameFormat" BO_ 927 14;

BA_ "GenSigSendType" SG_ 927 CldDiagGPSPermsnSwReq_HMI 4;
BA_ "SignalLongName" SG_ 927 CldDiagGPSPermsnSwReq_HMI "CloudDiagnosisGPSPermissionSwitchRequest_HMI";

BA_ "GenSigSendType" SG_ 927 VehPosPermsnSwReq_HMI 4;
BA_ "SignalLongName" SG_ 927 VehPosPermsnSwReq_HMI "VehiclePositionPermissionSwitchRequest_HMI";

BA_ "GenSigSendType" SG_ 927 PrvyCtrlAPNCnctnSts 0;
BA_ "SignalLongName" SG_ 927 PrvyCtrlAPNCnctnSts "PrivacyControlAPNConnectionStatus";

BA_ "GenSigSendType" SG_ 927 PrvyPlyAuthSts 0;
BA_ "SignalLongName" SG_ 927 PrvyPlyAuthSts "PrivacyPolicyAuthorizationStatus";

BA_ "GenSigSendType" SG_ 927 CldDiagPosPermsnSwSts 0;
BA_ "SignalLongName" SG_ 927 CldDiagPosPermsnSwSts "CloudDiagnosisPositionPermissionSwitchStatus";

BA_ "GenSigSendType" SG_ 927 MobileAppPosPermsnSwSts 0;
BA_ "SignalLongName" SG_ 927 MobileAppPosPermsnSwSts "MobileAppPositionPermissionSwitchStatus";

BA_ "GenSigSendType" SG_ 927 VehPosPermsnMnSwSts 0;
BA_ "SignalLongName" SG_ 927 VehPosPermsnMnSwSts "VehiclePositionPermissionMainSwitchStatus";

BA_ "GenSigSendType" SG_ 927 MicPermsnMnSwSts 0;
BA_ "SignalLongName" SG_ 927 MicPermsnMnSwSts "MicrophonePermissionMainSwitchStatus";

BA_ "GenSigSendType" SG_ 927 IterCamPermsnMnSwSts 0;
BA_ "SignalLongName" SG_ 927 IterCamPermsnMnSwSts "InteriorCameraPermissionMainSwitchStatus";

BA_ "GenMsgSendType" BO_ 938 0;
BA_ "GenMsgStartDelayTime" BO_ 938 5;
BA_ "GenMsgCycleTime" BO_ 938 100;
BA_ "GenMsgILSupport" BO_ 938 1;
BA_ "VFrameFormat" BO_ 938 14;

BA_ "GenSigSendType" SG_ 938 SpdLmtUnt 0;
BA_ "SignalLongName" SG_ 938 SpdLmtUnt "Speed Limit Unit";

BA_ "GenSigSendType" SG_ 938 MAPCountryID 0;
BA_ "SignalLongName" SG_ 938 MAPCountryID "MAP Country ID";

BA_ "GenSigSendType" SG_ 938 CurrRoadSpdLmt 0;
BA_ "SignalLongName" SG_ 938 CurrRoadSpdLmt "Current Road Speed Limit";

BA_ "GenSigSendType" SG_ 938 MAPCovSts 0;
BA_ "SignalLongName" SG_ 938 MAPCovSts "Map Coverage Status";

BA_ "GenSigSendType" SG_ 938 CurrPosSts 0;
BA_ "SignalLongName" SG_ 938 CurrPosSts "Current Positioning Status";

BA_ "GenSigSendType" SG_ 938 MAPConfidence 0;
BA_ "SignalLongName" SG_ 938 MAPConfidence "MAP Confidence";

BA_ "GenSigSendType" SG_ 938 SpdLmtType 0;
BA_ "SignalLongName" SG_ 938 SpdLmtType "Speed Limit Type";

BA_ "GenSigSendType" SG_ 938 CurrRoadType 0;
BA_ "SignalLongName" SG_ 938 CurrRoadType "Current Road Type";

BA_ "GenMsgSendType" BO_ 939 0;
BA_ "GenMsgStartDelayTime" BO_ 939 20;
BA_ "GenMsgCycleTime" BO_ 939 500;
BA_ "GenMsgILSupport" BO_ 939 1;
BA_ "GenMsgCycleTimeFast" BO_ 939 40;
BA_ "GenMsgNrOfRepetition" BO_ 939 3;
BA_ "GenMsgDelayTime" BO_ 939 20;
BA_ "VFrameFormat" BO_ 939 14;

BA_ "GenSigSendType" SG_ 939 StTrkPosReq_DR_HMI 4;
BA_ "SignalLongName" SG_ 939 StTrkPosReq_DR_HMI "Seat Track Position Request_DR_HMI";
BA_ "GenSigTimeoutValue" SG_ 939 StTrkPosReq_DR_HMI 127;
BA_ "GenSigStartValue" SG_ 939 StTrkPosReq_DR_HMI 127;

BA_ "GenSigSendType" SG_ 939 StRtaPosReq_DR_HMI 4;
BA_ "SignalLongName" SG_ 939 StRtaPosReq_DR_HMI "Seat Rotation Position Request_DR_HMI";
BA_ "GenSigTimeoutValue" SG_ 939 StRtaPosReq_DR_HMI 127;
BA_ "GenSigStartValue" SG_ 939 StRtaPosReq_DR_HMI 127;

BA_ "GenMsgSendType" BO_ 1017 0;
BA_ "GenMsgStartDelayTime" BO_ 1017 25;
BA_ "GenMsgCycleTime" BO_ 1017 500;
BA_ "GenMsgILSupport" BO_ 1017 1;
BA_ "VFrameFormat" BO_ 1017 14;

BA_ "GenSigSendType" SG_ 1017 InnerV2LResp 0;
BA_ "SignalLongName" SG_ 1017 InnerV2LResp "Inner V2L Display command Response";

BA_ "GenSigSendType" SG_ 1017 InnerV2LDspCmd 0;
BA_ "SignalLongName" SG_ 1017 InnerV2LDspCmd "Inner V2L Display command";

BA_ "GenSigSendType" SG_ 1017 OuterV2LResp 0;
BA_ "SignalLongName" SG_ 1017 OuterV2LResp "Outer V2L Display command Response";

BA_ "GenSigSendType" SG_ 1017 InnerV2LBtnSts 0;
BA_ "SignalLongName" SG_ 1017 InnerV2LBtnSts "InnerV2L ButtonStatus";

BA_ "GenSigSendType" SG_ 1017 OuterV2LBtnSts 0;
BA_ "SignalLongName" SG_ 1017 OuterV2LBtnSts "OuterV2L ButtonStatus";

BA_ "GenSigSendType" SG_ 1017 InnerDsChrgSpRsn 0;
BA_ "SignalLongName" SG_ 1017 InnerDsChrgSpRsn "Inner Discharging Stop Reason";

BA_ "GenSigSendType" SG_ 1017 InnerV2LKeepTimeDspCmd 0;
BA_ "SignalLongName" SG_ 1017 InnerV2LKeepTimeDspCmd "InnerV2L Keep Time Display Command";

BA_ "GenSigSendType" SG_ 1017 OuterV2LDspCmd 0;
BA_ "SignalLongName" SG_ 1017 OuterV2LDspCmd "Outer V2L Display command";

BA_ "GenMsgSendType" BO_ 839 0;
BA_ "GenMsgStartDelayTime" BO_ 839 10;
BA_ "GenMsgCycleTime" BO_ 839 200;
BA_ "GenMsgILSupport" BO_ 839 1;
BA_ "GenMsgDelayTime" BO_ 839 20;
BA_ "VFrameFormat" BO_ 839 14;

BA_ "GenSigSendType" SG_ 839 CPDFnSwReqFdbk 0;
BA_ "SignalLongName" SG_ 839 CPDFnSwReqFdbk "CPDFunctionSwitchRequestFeedback";
BA_ "GenSigStartValue" SG_ 839 CPDFnSwReqFdbk 1;

BA_ "GenSigSendType" SG_ 839 CPDSysFlt 0;
BA_ "SignalLongName" SG_ 839 CPDSysFlt "CPDSystemFault";

BA_ "GenSigSendType" SG_ 839 CPDLftWrnng 0;
BA_ "SignalLongName" SG_ 839 CPDLftWrnng "CPD Left Warnning";

BA_ "GenMsgSendType" BO_ 856 0;
BA_ "GenMsgCycleTime" BO_ 856 500;
BA_ "GenMsgILSupport" BO_ 856 1;
BA_ "GenMsgCycleTimeFast" BO_ 856 40;
BA_ "GenMsgNrOfRepetition" BO_ 856 3;
BA_ "GenMsgDelayTime" BO_ 856 20;
BA_ "VFrameFormat" BO_ 856 14;

BA_ "GenSigSendType" SG_ 856 ParalParkingInReqFdbck 4;
BA_ "SignalLongName" SG_ 856 ParalParkingInReqFdbck "Parallel Parking In Request Feedback";

BA_ "GenSigSendType" SG_ 856 PerpParkingInReqFdbck 4;
BA_ "SignalLongName" SG_ 856 PerpParkingInReqFdbck "Perpendicular Parking In Request Feedback";

BA_ "GenSigSendType" SG_ 856 ParkingOutReqFdbck 4;
BA_ "SignalLongName" SG_ 856 ParkingOutReqFdbck "Parking Out Request Feedback";

BA_ "GenMsgSendType" BO_ 855 0;
BA_ "GenMsgCycleTime" BO_ 855 500;
BA_ "GenMsgILSupport" BO_ 855 1;
BA_ "GenMsgCycleTimeFast" BO_ 855 40;
BA_ "GenMsgNrOfRepetition" BO_ 855 3;
BA_ "GenMsgDelayTime" BO_ 855 20;
BA_ "VFrameFormat" BO_ 855 14;

BA_ "GenSigSendType" SG_ 855 ParalParkingInReq 4;
BA_ "SignalLongName" SG_ 855 ParalParkingInReq "Parallel Parking In Request";

BA_ "GenSigSendType" SG_ 855 PerpParkingInReq 4;
BA_ "SignalLongName" SG_ 855 PerpParkingInReq "Perpendicular Parking In Request";

BA_ "GenSigSendType" SG_ 855 ParkingOutReq 4;
BA_ "SignalLongName" SG_ 855 ParkingOutReq "Parking Out Request";

BA_ "GenMsgSendType" BO_ 829 0;
BA_ "GenMsgCycleTime" BO_ 829 100;
BA_ "GenMsgILSupport" BO_ 829 1;
BA_ "VFrameFormat" BO_ 829 14;

BA_ "GenSigSendType" SG_ 829 HLCSts 0;
BA_ "SignalLongName" SG_ 829 HLCSts "HLC Status";

BA_ "GenSigSendType" SG_ 829 HLCWrnngLvl 0;
BA_ "SignalLongName" SG_ 829 HLCWrnngLvl "HLC Warning Level";

BA_ "GenSigSendType" SG_ 829 HLCSnsrEr 0;
BA_ "SignalLongName" SG_ 829 HLCSnsrEr "HLC Sensor Error";

BA_ "GenSigSendType" SG_ 829 HLCMainSwSetReqFdbk 0;
BA_ "SignalLongName" SG_ 829 HLCMainSwSetReqFdbk "HLC Main Switch Set Request Feedback";

BA_ "GenSigSendType" SG_ 829 HLCFctryDeftSetFnsh 0;
BA_ "SignalLongName" SG_ 829 HLCFctryDeftSetFnsh "HLC Factory Default Setting Finished";

BA_ "GenMsgSendType" BO_ 744 0;
BA_ "GenMsgStartDelayTime" BO_ 744 15;
BA_ "GenMsgCycleTime" BO_ 744 50;
BA_ "GenMsgILSupport" BO_ 744 1;
BA_ "VFrameFormat" BO_ 744 14;

BA_ "GenSigSendType" SG_ 744 MOISSts_R_ChkSum 0;
BA_ "SignalLongName" SG_ 744 MOISSts_R_ChkSum "MOISSts_Right Check Sum";

BA_ "GenSigSendType" SG_ 744 SRR_F_MFctryDeftSetFnsh 0;
BA_ "SignalLongName" SG_ 744 SRR_F_MFctryDeftSetFnsh "SRR_F_M Factory Default Set Finish";

BA_ "GenSigSendType" SG_ 744 MOISSts_R_RllCnt 0;
BA_ "SignalLongName" SG_ 744 MOISSts_R_RllCnt "MOISSts_Right Rolling Counter";

BA_ "GenSigSendType" SG_ 744 MOISMainSwFdbck 0;
BA_ "SignalLongName" SG_ 744 MOISMainSwFdbck "Moving Off Information System Switch Feedback";

BA_ "GenMsgSendType" BO_ 743 0;
BA_ "GenMsgStartDelayTime" BO_ 743 15;
BA_ "GenMsgCycleTime" BO_ 743 50;
BA_ "GenMsgILSupport" BO_ 743 1;
BA_ "VFrameFormat" BO_ 743 14;

BA_ "GenSigSendType" SG_ 743 BSISSts_F_ChkSum 0;
BA_ "SignalLongName" SG_ 743 BSISSts_F_ChkSum "BSISSts_Front Check Sum";

BA_ "GenSigSendType" SG_ 743 SRR_S_MFctryDeftSetFnsh 0;
BA_ "SignalLongName" SG_ 743 SRR_S_MFctryDeftSetFnsh "SRR_S_M Factory Default Set Finish";

BA_ "GenSigSendType" SG_ 743 BSISSts_F_RllCnt 0;
BA_ "SignalLongName" SG_ 743 BSISSts_F_RllCnt "BSISSts_Front Rolling Counter";

BA_ "GenSigSendType" SG_ 743 BSISMainSwFdbck 0;
BA_ "SignalLongName" SG_ 743 BSISMainSwFdbck "Blind Spot Information System Feedback";

BA_ "GenMsgSendType" BO_ 1376 0;
BA_ "GenMsgStartDelayTime" BO_ 1376 25;
BA_ "GenMsgCycleTime" BO_ 1376 500;
BA_ "GenMsgILSupport" BO_ 1376 1;
BA_ "VFrameFormat" BO_ 1376 14;

BA_ "GenSigSendType" SG_ 1376 DcrtvLmpSwSts 0;
BA_ "SignalLongName" SG_ 1376 DcrtvLmpSwSts "DecorativeLampSwitchStatus";

BA_ "GenMsgSendType" BO_ 1370 0;
BA_ "GenMsgStartDelayTime" BO_ 1370 25;
BA_ "GenMsgCycleTime" BO_ 1370 500;
BA_ "GenMsgILSupport" BO_ 1370 1;
BA_ "VFrameFormat" BO_ 1370 14;

BA_ "GenSigSendType" SG_ 1370 ClnWtrTnk1 0;
BA_ "SignalLongName" SG_ 1370 ClnWtrTnk1 "Clean WaterTank1";
BA_ "GenSigTimeoutValue" SG_ 1370 ClnWtrTnk1 127;
BA_ "GenSigStartValue" SG_ 1370 ClnWtrTnk1 127;

BA_ "GenSigSendType" SG_ 1370 KtchGryWtrTnk 0;
BA_ "SignalLongName" SG_ 1370 KtchGryWtrTnk "Kitchen Grey WaterTank";
BA_ "GenSigTimeoutValue" SG_ 1370 KtchGryWtrTnk 127;
BA_ "GenSigStartValue" SG_ 1370 KtchGryWtrTnk 127;

BA_ "GenSigSendType" SG_ 1370 TlGryWtrTnk 0;
BA_ "SignalLongName" SG_ 1370 TlGryWtrTnk "Toilet Grey WaterTank";
BA_ "GenSigTimeoutValue" SG_ 1370 TlGryWtrTnk 127;
BA_ "GenSigStartValue" SG_ 1370 TlGryWtrTnk 127;

BA_ "GenMsgSendType" BO_ 1365 0;
BA_ "GenMsgStartDelayTime" BO_ 1365 25;
BA_ "GenMsgCycleTime" BO_ 1365 500;
BA_ "GenMsgILSupport" BO_ 1365 1;
BA_ "GenMsgCycleTimeFast" BO_ 1365 40;
BA_ "GenMsgNrOfRepetition" BO_ 1365 3;
BA_ "GenMsgDelayTime" BO_ 1365 20;
BA_ "VFrameFormat" BO_ 1365 14;

BA_ "GenSigSendType" SG_ 1365 RrACTempSetSts 0;
BA_ "SignalLongName" SG_ 1365 RrACTempSetSts "Rear AC Temperature Set Status";
BA_ "GenSigTimeoutValue" SG_ 1365 RrACTempSetSts 7;
BA_ "GenSigStartValue" SG_ 1365 RrACTempSetSts 7;

BA_ "GenSigSendType" SG_ 1365 RrACMdSts 0;
BA_ "SignalLongName" SG_ 1365 RrACMdSts "Rear AC Mode Status";

BA_ "GenSigSendType" SG_ 1365 RrACPwrSts 0;
BA_ "SignalLongName" SG_ 1365 RrACPwrSts "Rear AC Power Status";

BA_ "GenSigSendType" SG_ 1365 RrACBlwrLvlSts 0;
BA_ "SignalLongName" SG_ 1365 RrACBlwrLvlSts "Rear AC Blower Level Set Status";

BA_ "GenSigSendType" SG_ 1365 RrACTmShtdwnSetFdbck 0;
BA_ "SignalLongName" SG_ 1365 RrACTmShtdwnSetFdbck "Rear AC Timed Shutdown Set Feedback";

BA_ "GenMsgSendType" BO_ 1281 0;
BA_ "GenMsgStartDelayTime" BO_ 1281 10;
BA_ "GenMsgCycleTime" BO_ 1281 200;
BA_ "GenMsgILSupport" BO_ 1281 1;
BA_ "VFrameFormat" BO_ 1281 14;

BA_ "GenSigSendType" SG_ 1281 BMSRptBatCodeIndx 0;
BA_ "SignalLongName" SG_ 1281 BMSRptBatCodeIndx "Battery Management System Report Battery Code Index";
BA_ "GenSigTimeoutValue" SG_ 1281 BMSRptBatCodeIndx 255;
BA_ "GenSigStartValue" SG_ 1281 BMSRptBatCodeIndx 255;

BA_ "GenSigSendType" SG_ 1281 BMSRptBatCodeAsc1 0;
BA_ "SignalLongName" SG_ 1281 BMSRptBatCodeAsc1 "Battery Management System Report Battery Code Ascii 1";
BA_ "GenSigTimeoutValue" SG_ 1281 BMSRptBatCodeAsc1 255;
BA_ "GenSigStartValue" SG_ 1281 BMSRptBatCodeAsc1 255;

BA_ "GenSigSendType" SG_ 1281 BMSRptBatCodeAsc2 0;
BA_ "SignalLongName" SG_ 1281 BMSRptBatCodeAsc2 "Battery Management System Report Battery Code Ascii 2";
BA_ "GenSigTimeoutValue" SG_ 1281 BMSRptBatCodeAsc2 255;
BA_ "GenSigStartValue" SG_ 1281 BMSRptBatCodeAsc2 255;

BA_ "GenSigSendType" SG_ 1281 BMSRptBatCodeAsc3 0;
BA_ "SignalLongName" SG_ 1281 BMSRptBatCodeAsc3 "Battery Management System Report Battery Code Ascii 3";
BA_ "GenSigTimeoutValue" SG_ 1281 BMSRptBatCodeAsc3 255;
BA_ "GenSigStartValue" SG_ 1281 BMSRptBatCodeAsc3 255;

BA_ "GenSigSendType" SG_ 1281 BMSRptBatCodeAsc4 0;
BA_ "SignalLongName" SG_ 1281 BMSRptBatCodeAsc4 "Battery Management System Report Battery Code Ascii 4";
BA_ "GenSigTimeoutValue" SG_ 1281 BMSRptBatCodeAsc4 255;
BA_ "GenSigStartValue" SG_ 1281 BMSRptBatCodeAsc4 255;

BA_ "GenSigSendType" SG_ 1281 BMSRptBatCodeAsc5 0;
BA_ "SignalLongName" SG_ 1281 BMSRptBatCodeAsc5 "Battery Management System Report Battery Code Ascii 5";
BA_ "GenSigTimeoutValue" SG_ 1281 BMSRptBatCodeAsc5 255;
BA_ "GenSigStartValue" SG_ 1281 BMSRptBatCodeAsc5 255;

BA_ "GenSigSendType" SG_ 1281 BMSRptBatCodeAsc6 0;
BA_ "SignalLongName" SG_ 1281 BMSRptBatCodeAsc6 "Battery Management System Report Battery Code Ascii 6";
BA_ "GenSigTimeoutValue" SG_ 1281 BMSRptBatCodeAsc6 255;
BA_ "GenSigStartValue" SG_ 1281 BMSRptBatCodeAsc6 255;

BA_ "GenSigSendType" SG_ 1281 BMSRptBatCodeAsc7 0;
BA_ "SignalLongName" SG_ 1281 BMSRptBatCodeAsc7 "Battery Management System Report Battery Code Ascii 7";
BA_ "GenSigTimeoutValue" SG_ 1281 BMSRptBatCodeAsc7 255;
BA_ "GenSigStartValue" SG_ 1281 BMSRptBatCodeAsc7 255;

BA_ "GenMsgSendType" BO_ 1354 0;
BA_ "GenMsgStartDelayTime" BO_ 1354 30;
BA_ "GenMsgCycleTime" BO_ 1354 1000;
BA_ "GenMsgILSupport" BO_ 1354 1;
BA_ "VFrameFormat" BO_ 1354 14;

BA_ "GenSigSendType" SG_ 1354 ESSSwapWaitNum 0;
BA_ "SignalLongName" SG_ 1354 ESSSwapWaitNum "Energy Storage System Swap Waiting Number";
BA_ "GenSigTimeoutValue" SG_ 1354 ESSSwapWaitNum 255;
BA_ "GenSigStartValue" SG_ 1354 ESSSwapWaitNum 255;

BA_ "GenSigSendType" SG_ 1354 ESSSwapWaitNumV 0;
BA_ "SignalLongName" SG_ 1354 ESSSwapWaitNumV "Energy Storage System Swap Waiting Number Validity";
BA_ "GenSigTimeoutValue" SG_ 1354 ESSSwapWaitNumV 1;
BA_ "GenSigStartValue" SG_ 1354 ESSSwapWaitNumV 1;

BA_ "GenMsgSendType" BO_ 963 0;
BA_ "GenMsgStartDelayTime" BO_ 963 5;
BA_ "GenMsgCycleTime" BO_ 963 100;
BA_ "GenMsgILSupport" BO_ 963 1;
BA_ "VFrameFormat" BO_ 963 14;

BA_ "GenSigSendType" SG_ 963 BaaSManuSetngReslt 0;
BA_ "SignalLongName" SG_ 963 BaaSManuSetngReslt "Battery as a Service Manual Setting Result";

BA_ "GenSigSendType" SG_ 963 ESSSwapStrgWhlPsd 0;
BA_ "SignalLongName" SG_ 963 ESSSwapStrgWhlPsd "Energy Storage System Swap Steering Wheel Passed";

BA_ "GenSigSendType" SG_ 963 ESSSwapShifterLvrPsd 0;
BA_ "SignalLongName" SG_ 963 ESSSwapShifterLvrPsd "Energy Storage System Swap Shifter Lever passed";

BA_ "GenSigSendType" SG_ 963 ESSSwapDoorPsd 0;
BA_ "SignalLongName" SG_ 963 ESSSwapDoorPsd "Energy Storage System Swap Door Passed";

BA_ "GenSigSendType" SG_ 963 ESSSwapChkPsd 0;
BA_ "SignalLongName" SG_ 963 ESSSwapChkPsd "Energy Storage System Swap Check Passed";

BA_ "GenSigSendType" SG_ 963 ESSSwapBrkPsd 0;
BA_ "SignalLongName" SG_ 963 ESSSwapBrkPsd "Energy Storage System Swap Brake Passed";

BA_ "GenSigSendType" SG_ 963 ESSSwapEPBPsd 0;
BA_ "SignalLongName" SG_ 963 ESSSwapEPBPsd "Energy Storage System Swap Epb Passed";

BA_ "GenSigSendType" SG_ 963 ESSSwapSuspdng 0;
BA_ "SignalLongName" SG_ 963 ESSSwapSuspdng "Energy Storage System Swap Suspending";

BA_ "GenMsgSendType" BO_ 1280 0;
BA_ "GenMsgStartDelayTime" BO_ 1280 30;
BA_ "GenMsgCycleTime" BO_ 1280 1000;
BA_ "GenMsgILSupport" BO_ 1280 1;
BA_ "VFrameFormat" BO_ 1280 14;

BA_ "GenSigSendType" SG_ 1280 SupportQueue 0;
BA_ "SignalLongName" SG_ 1280 SupportQueue "Station Support Queue";

BA_ "GenSigSendType" SG_ 1280 EstdWtngTime 0;
BA_ "SignalLongName" SG_ 1280 EstdWtngTime "QueueWaitingTime";
BA_ "GenSigTimeoutValue" SG_ 1280 EstdWtngTime 1023;
BA_ "GenSigStartValue" SG_ 1280 EstdWtngTime 1023;

BA_ "GenSigSendType" SG_ 1280 RqungReq 0;
BA_ "SignalLongName" SG_ 1280 RqungReq "RemindRequest";

BA_ "GenSigSendType" SG_ 1280 OrderSts 0;
BA_ "SignalLongName" SG_ 1280 OrderSts "Order Status";
BA_ "GenSigTimeoutValue" SG_ 1280 OrderSts 15;
BA_ "GenSigStartValue" SG_ 1280 OrderSts 15;

BA_ "GenSigSendType" SG_ 1280 QueueNum 0;
BA_ "SignalLongName" SG_ 1280 QueueNum "QueueNumber";

BA_ "GenMsgSendType" BO_ 989 0;
BA_ "GenMsgStartDelayTime" BO_ 989 5;
BA_ "GenMsgCycleTime" BO_ 989 100;
BA_ "GenMsgILSupport" BO_ 989 1;
BA_ "VFrameFormat" BO_ 989 14;

BA_ "GenSigSendType" SG_ 989 OuterV2LBtnDisableRsn 0;
BA_ "SignalLongName" SG_ 989 OuterV2LBtnDisableRsn "Outer V2L Button Disable Reason";

BA_ "GenSigSendType" SG_ 989 InnerV2LBtnDisableRsn 0;
BA_ "SignalLongName" SG_ 989 InnerV2LBtnDisableRsn "Inner V2L Button Disable Reason";

BA_ "GenSigSendType" SG_ 989 VCUInnerDsChrgPlugTmpWrn 0;
BA_ "SignalLongName" SG_ 989 VCUInnerDsChrgPlugTmpWrn "VCU Inner DsCharging Plug Temperature Warning";

BA_ "GenSigSendType" SG_ 989 V2LBtnDisablePtCtrl 0;
BA_ "SignalLongName" SG_ 989 V2LBtnDisablePtCtrl "V2L Button Disable Powertrain Control";

BA_ "GenSigSendType" SG_ 989 OuterV2LBtnStsPt 0;
BA_ "SignalLongName" SG_ 989 OuterV2LBtnStsPt "OuterV2L ButtonStatus send by Powertrain";

BA_ "GenSigSendType" SG_ 989 InnerV2LBtnStsPt 0;
BA_ "SignalLongName" SG_ 989 InnerV2LBtnStsPt "InnerV2L ButtonStatus send by Powertrain";

BA_ "GenMsgSendType" BO_ 815 0;
BA_ "GenMsgStartDelayTime" BO_ 815 20;
BA_ "GenMsgCycleTime" BO_ 815 50;
BA_ "GenMsgILSupport" BO_ 815 1;
BA_ "VFrameFormat" BO_ 815 14;

BA_ "GenSigSendType" SG_ 815 Easy2LoadSetReqFedbk 0;
BA_ "SignalLongName" SG_ 815 Easy2LoadSetReqFedbk "EasytoLoadSetRequestFeedback";

BA_ "GenSigSendType" SG_ 815 TowMdSetReqFedbk 0;
BA_ "SignalLongName" SG_ 815 TowMdSetReqFedbk "TowModeSetRequestFeedback";

BA_ "GenSigSendType" SG_ 815 CampMdSetReqFedbk 0;
BA_ "SignalLongName" SG_ 815 CampMdSetReqFedbk "CampingModeSetRequestFeedback";

BA_ "GenSigSendType" SG_ 815 ECASWelcomeSts 0;
BA_ "SignalLongName" SG_ 815 ECASWelcomeSts "ECASWelcomeStatus";

BA_ "GenSigSendType" SG_ 815 AirSuspTxtMsg2FICM 0;
BA_ "SignalLongName" SG_ 815 AirSuspTxtMsg2FICM "AirSuspensionTextMessage to FICM";

BA_ "GenSigSendType" SG_ 815 AirSuspHeightSts2IPK 0;
BA_ "SignalLongName" SG_ 815 AirSuspHeightSts2IPK "Air Suspension Height Staus to IPK";

BA_ "GenSigSendType" SG_ 815 OnBdScaTxtMsg2FICM 0;
BA_ "SignalLongName" SG_ 815 OnBdScaTxtMsg2FICM "OnboardScaleTextMessage to FICM";

BA_ "GenSigSendType" SG_ 815 AirSuspTxtMsg2IPK 0;
BA_ "SignalLongName" SG_ 815 AirSuspTxtMsg2IPK "AirSuspensionTextMessage to IPK";

BA_ "GenSigSendType" SG_ 815 PayloadPct 0;
BA_ "SignalLongName" SG_ 815 PayloadPct "PayloadPercent";

BA_ "GenSigSendType" SG_ 815 CurrPayload 0;
BA_ "SignalLongName" SG_ 815 CurrPayload "CurrentPayload";

BA_ "GenSigSendType" SG_ 815 ECASHirBtnSts 0;
BA_ "SignalLongName" SG_ 815 ECASHirBtnSts "ECASHigherButtonStatus";

BA_ "GenSigSendType" SG_ 815 ECASHiBtnSts 0;
BA_ "SignalLongName" SG_ 815 ECASHiBtnSts "ECASHighButtonStatus";

BA_ "GenSigSendType" SG_ 815 MaxPayload 0;
BA_ "SignalLongName" SG_ 815 MaxPayload "MaximumPayload";

BA_ "GenSigSendType" SG_ 815 ECASStdBtnSts 0;
BA_ "SignalLongName" SG_ 815 ECASStdBtnSts "ECASStandardButtonStatus";

BA_ "GenSigSendType" SG_ 815 ECASLoBtnSts 0;
BA_ "SignalLongName" SG_ 815 ECASLoBtnSts "ECASLowButtonStatus";

BA_ "GenSigSendType" SG_ 815 ECASLowrBtnSts 0;
BA_ "SignalLongName" SG_ 815 ECASLowrBtnSts "ECASLowerButtonStatus";

BA_ "GenSigSendType" SG_ 815 OnBdScaLoadUpdSts 0;
BA_ "SignalLongName" SG_ 815 OnBdScaLoadUpdSts "OnboardScaleLoadUpdateStatus";

BA_ "GenSigSendType" SG_ 815 CurrPayloadDispEna 0;
BA_ "SignalLongName" SG_ 815 CurrPayloadDispEna "CurrentPayloadDisplayEnable";

BA_ "GenMsgSendType" BO_ 620 0;
BA_ "GenMsgStartDelayTime" BO_ 620 10;
BA_ "GenMsgCycleTime" BO_ 620 200;
BA_ "GenMsgILSupport" BO_ 620 1;
BA_ "VFrameFormat" BO_ 620 14;

BA_ "GenSigSendType" SG_ 620 EASCAdjReqFedbk 0;
BA_ "SignalLongName" SG_ 620 EASCAdjReqFedbk "EASCAdjustRequestFeedback";

BA_ "GenSigSendType" SG_ 620 EASCPosnSaveFedbk 0;
BA_ "SignalLongName" SG_ 620 EASCPosnSaveFedbk "EASCPositionSaveFeedback";

BA_ "GenSigSendType" SG_ 620 EASCPosnRecFedbk 0;
BA_ "SignalLongName" SG_ 620 EASCPosnRecFedbk "EASCPositionRecoverFeedback";

BA_ "GenSigSendType" SG_ 620 EASCFctyDeftSetFnd 0;
BA_ "SignalLongName" SG_ 620 EASCFctyDeftSetFnd "EASCFactoryDefaultSettingFinished";

BA_ "GenSigSendType" SG_ 620 EASCErrSts 0;
BA_ "SignalLongName" SG_ 620 EASCErrSts "EASCErrorStatus";

BA_ "GenMsgSendType" BO_ 825 0;
BA_ "GenMsgStartDelayTime" BO_ 825 20;
BA_ "GenMsgCycleTime" BO_ 825 500;
BA_ "GenMsgILSupport" BO_ 825 1;
BA_ "GenMsgCycleTimeFast" BO_ 825 40;
BA_ "GenMsgNrOfRepetition" BO_ 825 3;
BA_ "GenMsgDelayTime" BO_ 825 20;
BA_ "VFrameFormat" BO_ 825 14;

BA_ "GenSigSendType" SG_ 825 HoodLockSts 4;
BA_ "SignalLongName" SG_ 825 HoodLockSts "Hood Lock Status";

BA_ "GenSigSendType" SG_ 825 HoodOprtSts 4;
BA_ "SignalLongName" SG_ 825 HoodOprtSts "Hood Operation Status";
BA_ "GenSigTimeoutValue" SG_ 825 HoodOprtSts 3;
BA_ "GenSigStartValue" SG_ 825 HoodOprtSts 3;

BA_ "GenSigSendType" SG_ 825 HoodOpnPos 4;
BA_ "SignalLongName" SG_ 825 HoodOpnPos "Hood Target Open Position";
BA_ "GenSigTimeoutValue" SG_ 825 HoodOpnPos 127;
BA_ "GenSigStartValue" SG_ 825 HoodOpnPos 127;

BA_ "GenSigSendType" SG_ 825 HoodOprtMdSts 4;
BA_ "SignalLongName" SG_ 825 HoodOprtMdSts "Hood Operation Mode Status";

BA_ "GenSigSendType" SG_ 825 HoodPrkPosSetSts 4;
BA_ "SignalLongName" SG_ 825 HoodPrkPosSetSts "Hood Park Position Set Status";
BA_ "GenSigTimeoutValue" SG_ 825 HoodPrkPosSetSts 7;
BA_ "GenSigStartValue" SG_ 825 HoodPrkPosSetSts 7;

BA_ "GenSigSendType" SG_ 825 HoodBuzReq 4;
BA_ "SignalLongName" SG_ 825 HoodBuzReq "Hood Buzzer Reqeust";

BA_ "GenSigSendType" SG_ 825 HoodAbsAlrm 4;
BA_ "SignalLongName" SG_ 825 HoodAbsAlrm "Hood Abuse Alarm";

BA_ "GenSigSendType" SG_ 825 HoodBuzSetSts 4;
BA_ "SignalLongName" SG_ 825 HoodBuzSetSts "Hood Buzzer Set Status";

BA_ "GenSigSendType" SG_ 825 DrAjr_TnovrEdGt 4;
BA_ "SignalLongName" SG_ 825 DrAjr_TnovrEdGt "Door Ajar_Turnover End Gate";

BA_ "GenSigSendType" SG_ 825 HoodCtrlBtnSts 0;
BA_ "SignalLongName" SG_ 825 HoodCtrlBtnSts "Hood Control Button Status";

BA_ "GenMsgSendType" BO_ 831 0;
BA_ "GenMsgStartDelayTime" BO_ 831 20;
BA_ "GenMsgCycleTime" BO_ 831 500;
BA_ "GenMsgILSupport" BO_ 831 1;
BA_ "GenMsgCycleTimeFast" BO_ 831 40;
BA_ "GenMsgNrOfRepetition" BO_ 831 3;
BA_ "GenMsgDelayTime" BO_ 831 20;
BA_ "VFrameFormat" BO_ 831 14;

BA_ "GenSigSendType" SG_ 831 HoodPrkPosReq 4;
BA_ "SignalLongName" SG_ 831 HoodPrkPosReq "Hood Park Position Request";
BA_ "GenSigTimeoutValue" SG_ 831 HoodPrkPosReq 127;
BA_ "GenSigStartValue" SG_ 831 HoodPrkPosReq 127;

BA_ "GenSigSendType" SG_ 831 HoodOprtMdReq 4;
BA_ "SignalLongName" SG_ 831 HoodOprtMdReq "Hood Operation Mode Request";

BA_ "GenSigSendType" SG_ 831 HoodPrkPosSetReq 4;
BA_ "SignalLongName" SG_ 831 HoodPrkPosSetReq "Hood Park Position Set Request";
BA_ "GenSigTimeoutValue" SG_ 831 HoodPrkPosSetReq 7;
BA_ "GenSigStartValue" SG_ 831 HoodPrkPosSetReq 7;

BA_ "GenSigSendType" SG_ 831 HoodOprtReq 4;
BA_ "SignalLongName" SG_ 831 HoodOprtReq "Hood Operation Request";

BA_ "GenSigSendType" SG_ 831 HoodBuzSet 4;
BA_ "SignalLongName" SG_ 831 HoodBuzSet "Hood Buzzer Set";

BA_ "GenSigSendType" SG_ 831 Wdw_CRPAutoOprtnReq 4;
BA_ "SignalLongName" SG_ 831 Wdw_CRPAutoOprtnReq "Window_CabinRearPanelAutoOperaiotnRequest_HMI";
BA_ "GenSigTimeoutValue" SG_ 831 Wdw_CRPAutoOprtnReq 127;
BA_ "GenSigStartValue" SG_ 831 Wdw_CRPAutoOprtnReq 127;

BA_ "GenSigSendType" SG_ 831 CRPUnLckReq 4;
BA_ "SignalLongName" SG_ 831 CRPUnLckReq "CabinRearPanel Unlock Request";

BA_ "GenMsgSendType" BO_ 840 0;
BA_ "GenMsgStartDelayTime" BO_ 840 20;
BA_ "GenMsgCycleTime" BO_ 840 500;
BA_ "GenMsgILSupport" BO_ 840 1;
BA_ "VFrameFormat" BO_ 840 14;

BA_ "GenSigSendType" SG_ 840 WdwCRPOprtSts 0;
BA_ "SignalLongName" SG_ 840 WdwCRPOprtSts "CabinRearPanelPowerWindowStatus";

BA_ "GenSigSendType" SG_ 840 WdwCRPPos 0;
BA_ "SignalLongName" SG_ 840 WdwCRPPos "Window CabinRearPanel Actual Position";
BA_ "GenSigTimeoutValue" SG_ 840 WdwCRPPos 127;
BA_ "GenSigStartValue" SG_ 840 WdwCRPPos 127;

BA_ "GenMsgSendType" BO_ 607 0;
BA_ "GenMsgStartDelayTime" BO_ 607 5;
BA_ "GenMsgCycleTime" BO_ 607 50;
BA_ "GenMsgILSupport" BO_ 607 1;
BA_ "VFrameFormat" BO_ 607 14;

BA_ "GenSigSendType" SG_ 607 WadeDep_MaxVal 0;
BA_ "SignalLongName" SG_ 607 WadeDep_MaxVal "WadeDepth_MaxValue";

BA_ "GenSigSendType" SG_ 607 WadeDep_MaxPosn 0;
BA_ "SignalLongName" SG_ 607 WadeDep_MaxPosn "WadeDepth_MaxPosition";

BA_ "GenSigSendType" SG_ 607 WadeDep_CurrVal 0;
BA_ "SignalLongName" SG_ 607 WadeDep_CurrVal "WadeDepth_CurrentValue";

BA_ "GenSigSendType" SG_ 607 WadeDep_CurrPosn 0;
BA_ "SignalLongName" SG_ 607 WadeDep_CurrPosn "WadeDepth_CurrentPosition";

BA_ "GenSigSendType" SG_ 607 WadeSenActvSts 0;
BA_ "SignalLongName" SG_ 607 WadeSenActvSts "WadeSensingActiveStatus";

BA_ "GenSigSendType" SG_ 607 WadeDepDsplyEn 0;
BA_ "SignalLongName" SG_ 607 WadeDepDsplyEn "WadeDepthDisplayEnable";

BA_ "GenSigSendType" SG_ 607 WadeSenMsgDisp 0;
BA_ "SignalLongName" SG_ 607 WadeSenMsgDisp "WadeSensingMessageDisplay";

BA_ "GenMsgSendType" BO_ 582 0;
BA_ "GenMsgStartDelayTime" BO_ 582 10;
BA_ "GenMsgCycleTime" BO_ 582 50;
BA_ "GenMsgILSupport" BO_ 582 1;
BA_ "VFrameFormat" BO_ 582 14;

BA_ "GenSigSendType" SG_ 582 RAEBMainSwFdbck 0;
BA_ "SignalLongName" SG_ 582 RAEBMainSwFdbck "Rear Autonomous Emergency Braking Main Switch Feedback";
BA_ "GenSigStartValue" SG_ 582 RAEBMainSwFdbck 1;

BA_ "GenSigSendType" SG_ 582 RCWMainSwFdbck 0;

BA_ "GenMsgSendType" BO_ 1385 0;
BA_ "GenMsgStartDelayTime" BO_ 1385 10;
BA_ "GenMsgCycleTime" BO_ 1385 200;
BA_ "GenMsgILSupport" BO_ 1385 1;
BA_ "VFrameFormat" BO_ 1385 14;

BA_ "GenSigSendType" SG_ 1385 FICMCampMdDrvrItndGennSts 0;
BA_ "SignalLongName" SG_ 1385 FICMCampMdDrvrItndGennSts "Front Infotainment Control Module Camp Mode Driver Intended Generation";

BA_ "GenSigSendType" SG_ 1385 FICMCampMdDrvrItndGennStsV 0;
BA_ "SignalLongName" SG_ 1385 FICMCampMdDrvrItndGennStsV "Front Infotainment Control Module Camp Mode Driver Intended Generation Status Validity";
BA_ "GenSigTimeoutValue" SG_ 1385 FICMCampMdDrvrItndGennStsV 1;
BA_ "GenSigStartValue" SG_ 1385 FICMCampMdDrvrItndGennStsV 1;

BA_ "GenSigSendType" SG_ 1385 FICMCampMdDrvrItndSOCMinV 0;
BA_ "SignalLongName" SG_ 1385 FICMCampMdDrvrItndSOCMinV "Front Infotainment Control Module Camp Mode Driver Intended State Of Charge Minimum Validity";
BA_ "GenSigTimeoutValue" SG_ 1385 FICMCampMdDrvrItndSOCMinV 1;
BA_ "GenSigStartValue" SG_ 1385 FICMCampMdDrvrItndSOCMinV 1;

BA_ "GenSigSendType" SG_ 1385 FICMCampMdDrvrItndGtnLvlV 0;
BA_ "SignalLongName" SG_ 1385 FICMCampMdDrvrItndGtnLvlV "Ficm Camp Mode Driver Intended Generation Level Validty";
BA_ "GenSigTimeoutValue" SG_ 1385 FICMCampMdDrvrItndGtnLvlV 1;
BA_ "GenSigStartValue" SG_ 1385 FICMCampMdDrvrItndGtnLvlV 1;

BA_ "GenSigSendType" SG_ 1385 FICMCampMdDrvrItndGtnLvl 0;
BA_ "SignalLongName" SG_ 1385 FICMCampMdDrvrItndGtnLvl "Ficm Camp Mode Driver Intended Generation Level";
BA_ "GenSigTimeoutValue" SG_ 1385 FICMCampMdDrvrItndGtnLvl 4;
BA_ "GenSigStartValue" SG_ 1385 FICMCampMdDrvrItndGtnLvl 4;

BA_ "GenSigSendType" SG_ 1385 FICMCampMdReqV 0;
BA_ "SignalLongName" SG_ 1385 FICMCampMdReqV "Ficm Camp Mode Request Validty";
BA_ "GenSigTimeoutValue" SG_ 1385 FICMCampMdReqV 1;
BA_ "GenSigStartValue" SG_ 1385 FICMCampMdReqV 1;

BA_ "GenSigSendType" SG_ 1385 FICMCampMdReq 0;
BA_ "SignalLongName" SG_ 1385 FICMCampMdReq "Ficm Camp Mode Request";

BA_ "GenSigSendType" SG_ 1385 FICMCampMdDrvrItndSOCMaxV 0;
BA_ "SignalLongName" SG_ 1385 FICMCampMdDrvrItndSOCMaxV "Front Infotainment Control Module Camp Mode Driver Intended State Of Charge Maximum Validity";
BA_ "GenSigTimeoutValue" SG_ 1385 FICMCampMdDrvrItndSOCMaxV 1;
BA_ "GenSigStartValue" SG_ 1385 FICMCampMdDrvrItndSOCMaxV 1;

BA_ "GenSigSendType" SG_ 1385 FICMCampMdDrvrItndSOCMin 0;
BA_ "SignalLongName" SG_ 1385 FICMCampMdDrvrItndSOCMin "Front Infotainment Control Module Camp Mode Driver Intended State Of Charge Minimum";
BA_ "GenSigTimeoutValue" SG_ 1385 FICMCampMdDrvrItndSOCMin 30;
BA_ "GenSigStartValue" SG_ 1385 FICMCampMdDrvrItndSOCMin 30;

BA_ "GenSigSendType" SG_ 1385 FICMCampMdDrvrItndSOCMax 0;
BA_ "SignalLongName" SG_ 1385 FICMCampMdDrvrItndSOCMax "Front Infotainment Control Module Mode Driver Intended State Of Charge Maximum";
BA_ "GenSigTimeoutValue" SG_ 1385 FICMCampMdDrvrItndSOCMax 50;
BA_ "GenSigStartValue" SG_ 1385 FICMCampMdDrvrItndSOCMax 50;

BA_ "GenMsgSendType" BO_ 861 0;
BA_ "GenMsgStartDelayTime" BO_ 861 30;
BA_ "GenMsgCycleTime" BO_ 861 500;
BA_ "GenMsgILSupport" BO_ 861 1;
BA_ "GenMsgCycleTimeFast" BO_ 861 40;
BA_ "GenMsgNrOfRepetition" BO_ 861 3;
BA_ "GenMsgDelayTime" BO_ 861 20;
BA_ "VFrameFormat" BO_ 861 14;

BA_ "GenSigSendType" SG_ 861 FICMMntOfEPTOStrStReq 4;
BA_ "SignalLongName" SG_ 861 FICMMntOfEPTOStrStReq "FICM minute Of EPTOStartSetRequest";
BA_ "GenSigTimeoutValue" SG_ 861 FICMMntOfEPTOStrStReq 63;
BA_ "GenSigStartValue" SG_ 861 FICMMntOfEPTOStrStReq 63;

BA_ "GenSigSendType" SG_ 861 FICMHrOfEPTOFStrStReq 4;
BA_ "SignalLongName" SG_ 861 FICMHrOfEPTOFStrStReq "FICM Hour Of EPTOStartSetRequest";
BA_ "GenSigTimeoutValue" SG_ 861 FICMHrOfEPTOFStrStReq 31;
BA_ "GenSigStartValue" SG_ 861 FICMHrOfEPTOFStrStReq 31;

BA_ "GenSigSendType" SG_ 861 FICMMntOfEPTOFnhStReq 4;
BA_ "SignalLongName" SG_ 861 FICMMntOfEPTOFnhStReq "FICM Minute Of EPTOFinishSetRequest";
BA_ "GenSigTimeoutValue" SG_ 861 FICMMntOfEPTOFnhStReq 63;
BA_ "GenSigStartValue" SG_ 861 FICMMntOfEPTOFnhStReq 63;

BA_ "GenSigSendType" SG_ 861 FICMHrOfEPTOFnhStReq 4;
BA_ "SignalLongName" SG_ 861 FICMHrOfEPTOFnhStReq "FICM Hour Of EPTOFinishSetRequest";
BA_ "GenSigTimeoutValue" SG_ 861 FICMHrOfEPTOFnhStReq 31;
BA_ "GenSigStartValue" SG_ 861 FICMHrOfEPTOFnhStReq 31;

BA_ "GenSigSendType" SG_ 861 EPTOCtrlReq 4;
BA_ "SignalLongName" SG_ 861 EPTOCtrlReq "EPTOControlRequest";

BA_ "GenSigSendType" SG_ 861 EPTODplctEfctStReq 4;
BA_ "SignalLongName" SG_ 861 EPTODplctEfctStReq "EPTO duplicate effective set Request";

BA_ "GenSigSendType" SG_ 861 EPTOStpSOCStReq 4;
BA_ "SignalLongName" SG_ 861 EPTOStpSOCStReq "EPTOStopSOCSettingRequest";

BA_ "GenMsgSendType" BO_ 860 0;
BA_ "GenMsgStartDelayTime" BO_ 860 10;
BA_ "GenMsgCycleTime" BO_ 860 100;
BA_ "GenMsgILSupport" BO_ 860 1;
BA_ "GenMsgDelayTime" BO_ 860 10;
BA_ "VFrameFormat" BO_ 860 14;

BA_ "GenSigSendType" SG_ 860 SetMntOfEPTOStr 0;
BA_ "SignalLongName" SG_ 860 SetMntOfEPTOStr "Set minute Of EPTOStart";
BA_ "GenSigTimeoutValue" SG_ 860 SetMntOfEPTOStr 63;
BA_ "GenSigStartValue" SG_ 860 SetMntOfEPTOStr 63;

BA_ "GenSigSendType" SG_ 860 EnrgSplFdbk 0;
BA_ "SignalLongName" SG_ 860 EnrgSplFdbk "Energy Supply Feedback";

BA_ "GenSigSendType" SG_ 860 SetHrOfEPTOStr 0;
BA_ "SignalLongName" SG_ 860 SetHrOfEPTOStr "Set Hour Of EPTOStart";
BA_ "GenSigTimeoutValue" SG_ 860 SetHrOfEPTOStr 31;
BA_ "GenSigStartValue" SG_ 860 SetHrOfEPTOStr 31;

BA_ "GenSigSendType" SG_ 860 SetMntOfEPTOFnh 0;
BA_ "SignalLongName" SG_ 860 SetMntOfEPTOFnh "Set Minute Of EPTOFinish";
BA_ "GenSigTimeoutValue" SG_ 860 SetMntOfEPTOFnh 63;
BA_ "GenSigStartValue" SG_ 860 SetMntOfEPTOFnh 63;

BA_ "GenSigSendType" SG_ 860 SetHrOfEPTOFnh 0;
BA_ "SignalLongName" SG_ 860 SetHrOfEPTOFnh "Set Hour Of EPTOFinish";
BA_ "GenSigTimeoutValue" SG_ 860 SetHrOfEPTOFnh 31;
BA_ "GenSigStartValue" SG_ 860 SetHrOfEPTOFnh 31;

BA_ "GenSigSendType" SG_ 860 EPTOCtrlFdbk 0;
BA_ "SignalLongName" SG_ 860 EPTOCtrlFdbk "EPTO Control Feedback";

BA_ "GenSigSendType" SG_ 860 EPTODplctEfctSts 0;
BA_ "SignalLongName" SG_ 860 EPTODplctEfctSts "EPTO duplicate Effective status";

BA_ "GenSigSendType" SG_ 860 EPTOStpSOCStsVl 0;
BA_ "SignalLongName" SG_ 860 EPTOStpSOCStsVl "EPTOStopSOCSetValue";

BA_ "GenMsgSendType" BO_ 167 0;
BA_ "GenMsgCycleTime" BO_ 167 10;
BA_ "GenMsgILSupport" BO_ 167 1;
BA_ "VFrameFormat" BO_ 167 14;

BA_ "GenSigSendType" SG_ 167 IPB_A7h_PDU_00_Chksum 0;
BA_ "SignalLongName" SG_ 167 IPB_A7h_PDU_00_Chksum "IPB_A7h_PDU_00_Chksum";

BA_ "GenSigSendType" SG_ 167 IPB_A7h_PDU_00_RllCnt 0;
BA_ "SignalLongName" SG_ 167 IPB_A7h_PDU_00_RllCnt "IPB_A7h_PDU_00_RllCnt";

BA_ "GenSigSendType" SG_ 167 FWAwarning 0;
BA_ "SignalLongName" SG_ 167 FWAwarning "FWA_warning";

BA_ "GenSigSendType" SG_ 167 BrkFlWarning 0;
BA_ "SignalLongName" SG_ 167 BrkFlWarning "BrakeFluid_Warning";

BA_ "GenSigSendType" SG_ 167 IPBSts 0;
BA_ "SignalLongName" SG_ 167 IPBSts "IPB_System_Status";

BA_ "GenSigSendType" SG_ 167 CSTSts 0;
BA_ "SignalLongName" SG_ 167 CSTSts "CST_Status";

BA_ "GenMsgSendType" BO_ 1002 0;
BA_ "GenMsgStartDelayTime" BO_ 1002 10;
BA_ "GenMsgCycleTime" BO_ 1002 500;
BA_ "GenMsgILSupport" BO_ 1002 1;
BA_ "GenMsgCycleTimeFast" BO_ 1002 40;
BA_ "GenMsgNrOfRepetition" BO_ 1002 3;
BA_ "GenMsgDelayTime" BO_ 1002 20;
BA_ "VFrameFormat" BO_ 1002 14;

BA_ "GenSigSendType" SG_ 1002 PhoneRmdrReq2 4;
BA_ "SignalLongName" SG_ 1002 PhoneRmdrReq2 "Phone Reminder Request 2";

BA_ "GenSigSendType" SG_ 1002 FODAlrm2 4;
BA_ "SignalLongName" SG_ 1002 FODAlrm2 "FOD Alarm 2";

BA_ "GenSigSendType" SG_ 1002 WPCChrgSts2 0;
BA_ "SignalLongName" SG_ 1002 WPCChrgSts2 "WPC Charging Status 2";

BA_ "GenMsgSendType" BO_ 959 0;
BA_ "GenMsgStartDelayTime" BO_ 959 30;
BA_ "GenMsgCycleTime" BO_ 959 500;
BA_ "GenMsgILSupport" BO_ 959 1;
BA_ "GenMsgCycleTimeFast" BO_ 959 40;
BA_ "GenMsgNrOfRepetition" BO_ 959 3;
BA_ "GenMsgDelayTime" BO_ 959 20;
BA_ "VFrameFormat" BO_ 959 14;

BA_ "GenSigSendType" SG_ 959 WPCEnblReq2 4;
BA_ "SignalLongName" SG_ 959 WPCEnblReq2 "Wireless Powered Charging Enable Request 2";

BA_ "GenSigSendType" SG_ 959 FuelCsumpUnitSetReq 4;
BA_ "SignalLongName" SG_ 959 FuelCsumpUnitSetReq "Fuel consumption unit setting request";

BA_ "GenSigSendType" SG_ 959 DistractionMoniSwReq 4;
BA_ "SignalLongName" SG_ 959 DistractionMoniSwReq "Distraction Monitoring Setting Switch On/Off Request";

BA_ "GenSigSendType" SG_ 959 ATSMMReq 4;
BA_ "SignalLongName" SG_ 959 ATSMMReq "ATSModeMemoryRequest";

BA_ "GenSigSendType" SG_ 959 EPSMLReq 4;
BA_ "SignalLongName" SG_ 959 EPSMLReq "EPSModeLinkageRequest";

BA_ "GenSigSendType" SG_ 959 VehUnLckFormSet_VAN 4;
BA_ "SignalLongName" SG_ 959 VehUnLckFormSet_VAN "Vehicle Unlock Form Set for VAN";

BA_ "GenSigSendType" SG_ 959 DMSSWReq 4;
BA_ "SignalLongName" SG_ 959 DMSSWReq "DMS Switch Request";

BA_ "GenSigSendType" SG_ 959 FatigueMoniSwReq 4;
BA_ "SignalLongName" SG_ 959 FatigueMoniSwReq "Fatigue Monitoring Setting Switch On/Off Request";

BA_ "GenMsgSendType" BO_ 705 0;
BA_ "GenMsgStartDelayTime" BO_ 705 10;
BA_ "GenMsgCycleTime" BO_ 705 500;
BA_ "GenMsgILSupport" BO_ 705 1;
BA_ "GenMsgCycleTimeFast" BO_ 705 40;
BA_ "GenMsgNrOfRepetition" BO_ 705 3;
BA_ "GenMsgDelayTime" BO_ 705 20;
BA_ "VFrameFormat" BO_ 705 14;

BA_ "GenSigSendType" SG_ 705 CH_PT_Ctrl3_PDU_00_Chksum 0;
BA_ "SignalLongName" SG_ 705 CH_PT_Ctrl3_PDU_00_Chksum "Chassis_PowerTrainCtrl3_PDU_00_Chksum";

BA_ "GenSigSendType" SG_ 705 CH_PT_Ctrl3_PDU_00_RllCnt 0;
BA_ "SignalLongName" SG_ 705 CH_PT_Ctrl3_PDU_00_RllCnt "Chassis_PowerTrainCtrl3_PDU_00_RllCnt";

BA_ "GenSigSendType" SG_ 705 iTurnFnSwReq 4;
BA_ "SignalLongName" SG_ 705 iTurnFnSwReq "iTurnFunctionSwitchRequest";

BA_ "GenSigSendType" SG_ 705 CSTFnSwReq 4;
BA_ "SignalLongName" SG_ 705 CSTFnSwReq "CSTFunctionSwitchRequest";

BA_ "GenMsgSendType" BO_ 942 0;
BA_ "GenMsgCycleTime" BO_ 942 100;
BA_ "GenMsgILSupport" BO_ 942 1;
BA_ "VFrameFormat" BO_ 942 14;

BA_ "GenSigSendType" SG_ 942 FICMDsChrgVolReq 0;
BA_ "SignalLongName" SG_ 942 FICMDsChrgVolReq "FICM Discharge Voltage Request";

BA_ "GenSigSendType" SG_ 942 FICMDsChrgFreqReq 0;
BA_ "SignalLongName" SG_ 942 FICMDsChrgFreqReq "FICM Discharge Frequence Request";

BA_ "GenMsgSendType" BO_ 1518 0;
BA_ "GenMsgStartDelayTime" BO_ 1518 30;
BA_ "GenMsgCycleTime" BO_ 1518 500;
BA_ "GenMsgILSupport" BO_ 1518 1;
BA_ "GenMsgCycleTimeFast" BO_ 1518 40;
BA_ "GenMsgNrOfRepetition" BO_ 1518 3;
BA_ "GenMsgDelayTime" BO_ 1518 20;
BA_ "VFrameFormat" BO_ 1518 14;

BA_ "GenSigSendType" SG_ 1518 FICM_InterInfo 4;
BA_ "SignalLongName" SG_ 1518 FICM_InterInfo "FICM internal information ";

BA_ "GenMsgSendType" BO_ 1519 0;
BA_ "GenMsgStartDelayTime" BO_ 1519 30;
BA_ "GenMsgCycleTime" BO_ 1519 500;
BA_ "GenMsgILSupport" BO_ 1519 1;
BA_ "GenMsgCycleTimeFast" BO_ 1519 40;
BA_ "GenMsgNrOfRepetition" BO_ 1519 3;
BA_ "GenMsgDelayTime" BO_ 1519 20;
BA_ "VFrameFormat" BO_ 1519 14;

BA_ "GenSigSendType" SG_ 1519 IPK_InterInfo 4;
BA_ "SignalLongName" SG_ 1519 IPK_InterInfo "IPK internal information";

BA_ "GenMsgSendType" BO_ 843 0;
BA_ "GenMsgStartDelayTime" BO_ 843 30;
BA_ "GenMsgCycleTime" BO_ 843 500;
BA_ "GenMsgILSupport" BO_ 843 1;
BA_ "GenMsgCycleTimeFast" BO_ 843 40;
BA_ "GenMsgNrOfRepetition" BO_ 843 3;
BA_ "GenMsgDelayTime" BO_ 843 20;
BA_ "VFrameFormat" BO_ 843 14;

BA_ "GenSigSendType" SG_ 843 CldrYrCrt_HMISET 2;
BA_ "SignalLongName" SG_ 843 CldrYrCrt_HMISET "CalendarYear Correct_HMISET";

BA_ "GenSigSendType" SG_ 843 CldrMthCrt_HMISET 2;
BA_ "SignalLongName" SG_ 843 CldrMthCrt_HMISET "CalendarMonthCorrect_HMISET";

BA_ "GenSigSendType" SG_ 843 CldrDayCrt_HMISET 2;
BA_ "SignalLongName" SG_ 843 CldrDayCrt_HMISET "CalendarDayCorrect_HMISET";

BA_ "GenSigSendType" SG_ 843 HrofDayCrt_HMISET 2;
BA_ "SignalLongName" SG_ 843 HrofDayCrt_HMISET "HourOfDayCorrect_HMISET";

BA_ "GenSigSendType" SG_ 843 MinofHrCrt_HMISET 2;
BA_ "SignalLongName" SG_ 843 MinofHrCrt_HMISET "MinuteOfHourCorrect_HMISET";

BA_ "GenSigSendType" SG_ 843 DayCrtV_HMISET 2;
BA_ "SignalLongName" SG_ 843 DayCrtV_HMISET "DayCorrectValidity_HMISET";

BA_ "GenSigSendType" SG_ 843 CldCrtV_HMISET 2;
BA_ "SignalLongName" SG_ 843 CldCrtV_HMISET "CalendarCorrectValidity_HMISET";

BA_ "GenSigSendType" SG_ 843 SecofMinCrt_HMISET 2;
BA_ "SignalLongName" SG_ 843 SecofMinCrt_HMISET "SecsOfMinuteCorrect_HMISET";

BA_ "GenSigSendType" SG_ 843 ZnStReq_HMISET 2;
BA_ "SignalLongName" SG_ 843 ZnStReq_HMISET "ZoneSetRequest_HMISET";
BA_REL_ "GenSigTimeoutTime" BU_SG_REL_ FICM_FD SG_ 153 EMSSysOpngMdV 250;
BA_REL_ "GenSigTimeoutTime" BU_SG_REL_ FICM_FD SG_ 153 EMSSysOpngMd 250;
BA_REL_ "GenSigTimeoutTime" BU_SG_REL_ FICM_FD SG_ 153 WadeModeActSts 250;
BA_REL_ "GenSigTimeoutTime" BU_SG_REL_ FICM_FD SG_ 153 WadeModeDispCmd 250;
BA_REL_ "GenSigTimeoutTime" BU_SG_REL_ FICM_FD SG_ 164 BrkFlngMdSts 250;
BA_REL_ "GenSigTimeoutTime" BU_SG_REL_ FICM_FD SG_ 164 IBFSWstate 250;
BA_REL_ "GenSigTimeoutTime" BU_SG_REL_ FICM_FD SG_ 164 EBSFctryDeftSetFnsh 250;
BA_REL_ "GenSigTimeoutTime" BU_SG_REL_ FICM_FD SG_ 164 EBOOSTStatus2_RllCnt 250;
BA_REL_ "GenSigTimeoutTime" BU_SG_REL_ FICM_FD SG_ 164 EBOOSTStatus2_ChkSum 250;
BA_REL_ "GenSigTimeoutTime" BU_SG_REL_ FICM_FD SG_ 165 LDrvnWhlRotlDistPlsCtr 250;
BA_REL_ "GenSigTimeoutTime" BU_SG_REL_ FICM_FD SG_ 165 LDrvnWhlRotlDistPlsCtrV 250;
BA_REL_ "GenSigTimeoutTime" BU_SG_REL_ FICM_FD SG_ 165 RDrvnWhlRotlDistPlsCtr 250;
BA_REL_ "GenSigTimeoutTime" BU_SG_REL_ FICM_FD SG_ 165 RDrvnWhlRotlDistPlsCtrV 250;
BA_REL_ "GenSigTimeoutTime" BU_SG_REL_ FICM_FD SG_ 168 LNonDrvnWhlRotlDistPlsCtr 250;
BA_REL_ "GenSigTimeoutTime" BU_SG_REL_ FICM_FD SG_ 168 LNonDrvnWhlRotlDistPlsCtrV 250;
BA_REL_ "GenSigTimeoutTime" BU_SG_REL_ FICM_FD SG_ 168 RNonDrvnWhlRotlDistPlsCtr 250;
BA_REL_ "GenSigTimeoutTime" BU_SG_REL_ FICM_FD SG_ 168 RNonDrvnWhlRotlDistPlsCtrV 250;
BA_REL_ "GenSigTimeoutTime" BU_SG_REL_ FICM_FD SG_ 169 WhlSpdFLV 250;
BA_REL_ "GenSigTimeoutTime" BU_SG_REL_ FICM_FD SG_ 169 WhlSpdFL 250;
BA_REL_ "GenSigTimeoutTime" BU_SG_REL_ FICM_FD SG_ 169 WhlSpdFRV 250;
BA_REL_ "GenSigTimeoutTime" BU_SG_REL_ FICM_FD SG_ 169 WhlSpdFR 250;
BA_REL_ "GenSigTimeoutTime" BU_SG_REL_ FICM_FD SG_ 169 WhlDircnFL 250;
BA_REL_ "GenSigTimeoutTime" BU_SG_REL_ FICM_FD SG_ 169 WhlDircnFLV 250;
BA_REL_ "GenSigTimeoutTime" BU_SG_REL_ FICM_FD SG_ 169 WhlDircnFR 250;
BA_REL_ "GenSigTimeoutTime" BU_SG_REL_ FICM_FD SG_ 169 WhlDircnFRV 250;
BA_REL_ "GenSigTimeoutTime" BU_SG_REL_ FICM_FD SG_ 170 WhlSpdRLV 250;
BA_REL_ "GenSigTimeoutTime" BU_SG_REL_ FICM_FD SG_ 170 WhlSpdRL 250;
BA_REL_ "GenSigTimeoutTime" BU_SG_REL_ FICM_FD SG_ 170 WhlSpdRRV 250;
BA_REL_ "GenSigTimeoutTime" BU_SG_REL_ FICM_FD SG_ 170 WhlSpdRR 250;
BA_REL_ "GenSigTimeoutTime" BU_SG_REL_ FICM_FD SG_ 170 WhlDircnRL 250;
BA_REL_ "GenSigTimeoutTime" BU_SG_REL_ FICM_FD SG_ 170 WhlDircnRLV 250;
BA_REL_ "GenSigTimeoutTime" BU_SG_REL_ FICM_FD SG_ 170 WhlDircnRR 250;
BA_REL_ "GenSigTimeoutTime" BU_SG_REL_ FICM_FD SG_ 170 WhlDircnRRV 250;
BA_REL_ "GenSigTimeoutTime" BU_SG_REL_ FICM_FD SG_ 337 TCCUSysOpngMd 250;
BA_REL_ "GenSigTimeoutTime" BU_SG_REL_ FICM_FD SG_ 720 ESCFnOffFdbck_ATS 1000;
BA_REL_ "GenSigTimeoutTime" BU_SG_REL_ FICM_FD SG_ 720 ATSDrvngMdDisp 1000;
BA_REL_ "GenSigTimeoutTime" BU_SG_REL_ FICM_FD SG_ 720 ATSDrvngMdDispV 1000;
BA_REL_ "GenSigTimeoutTime" BU_SG_REL_ FICM_FD SG_ 720 ATSMMSts 1000;
BA_REL_ "GenSigTimeoutTime" BU_SG_REL_ FICM_FD SG_ 720 EPSMLSts 1000;
BA_REL_ "GenSigTimeoutTime" BU_SG_REL_ FICM_FD SG_ 710 AirClnrIonizerDspCmd 1000;
BA_REL_ "GenSigTimeoutTime" BU_SG_REL_ FICM_FD SG_ 710 AirClnrOnOffDspCmd 1000;
BA_REL_ "GenSigTimeoutTime" BU_SG_REL_ FICM_FD SG_ 710 AirClnrAutoDspCmd 1000;
BA_REL_ "GenSigTimeoutTime" BU_SG_REL_ FICM_FD SG_ 710 AirClnrUserCustAutoWDC 1000;
BA_REL_ "GenSigTimeoutTime" BU_SG_REL_ FICM_FD SG_ 710 AirClnrBlwrLvlDspCmd 1000;
BA_REL_ "GenSigTimeoutTime" BU_SG_REL_ FICM_FD SG_ 710 AirClnrFltrLife 1000;
BA_REL_ "GenSigTimeoutTime" BU_SG_REL_ FICM_FD SG_ 710 AirClnrFltrCsumLvlDspC 1000;
BA_REL_ "GenSigTimeoutTime" BU_SG_REL_ FICM_FD SG_ 710 AirClnrFltrLifeV 1000;
BA_REL_ "GenSigTimeoutTime" BU_SG_REL_ FICM_FD SG_ 592 ATSFnSWReqV 2000;
BA_REL_ "GenSigTimeoutTime" BU_SG_REL_ FICM_FD SG_ 592 ATSFnSWReq 2000;
BA_REL_ "GenSigTimeoutTime" BU_SG_REL_ FICM_FD SG_ 592 IBDU_ESC_SW_RllCnt 2000;
BA_REL_ "GenSigTimeoutTime" BU_SG_REL_ FICM_FD SG_ 592 IBDU_ESC_SW_ChkSum 2000;
BA_REL_ "GenSigTimeoutTime" BU_SG_REL_ FICM_FD SG_ 325 iTurnSysDispMsgReq 250;
BA_REL_ "GenSigTimeoutTime" BU_SG_REL_ FICM_FD SG_ 325 iTurnSts 250;
BA_REL_ "GenSigTimeoutTime" BU_SG_REL_ FICM_FD SG_ 325 CCOSysDispMsgReq 250;
BA_REL_ "GenSigTimeoutTime" BU_SG_REL_ FICM_FD SG_ 325 CCOSwLamp 250;
BA_REL_ "GenSigTimeoutTime" BU_SG_REL_ FICM_FD SG_ 325 DrSbltWarn 250;
BA_REL_ "GenSigTimeoutTime" BU_SG_REL_ FICM_FD SG_ 325 EPBReWarn 250;
BA_REL_ "GenSigTimeoutTime" BU_SG_REL_ FICM_FD SG_ 325 OffRoadMdWarn 250;
BA_REL_ "GenSigTimeoutTime" BU_SG_REL_ FICM_FD SG_ 325 ShftDWarn 250;
BA_REL_ "GenSigTimeoutTime" BU_SG_REL_ FICM_FD SG_ 325 CCOMDWarn 250;
BA_REL_ "GenSigTimeoutTime" BU_SG_REL_ FICM_FD SG_ 325 UnLEDLWarn 250;
BA_REL_ "GenSigTimeoutTime" BU_SG_REL_ FICM_FD SG_ 325 TrStringWarn 250;
BA_REL_ "GenSigTimeoutTime" BU_SG_REL_ FICM_FD SG_ 1022 ICGMHourOfBatHeat 5000;
BA_REL_ "GenSigTimeoutTime" BU_SG_REL_ FICM_FD SG_ 1022 BatHeatOrdStatus 5000;
BA_REL_ "GenSigTimeoutTime" BU_SG_REL_ FICM_FD SG_ 1022 ICGMMinOfBatHeat 5000;
BA_REL_ "GenSigTimeoutTime" BU_SG_REL_ FICM_FD SG_ 1022 ICGMPeriodOfBatHeatSunday 5000;
BA_REL_ "GenSigTimeoutTime" BU_SG_REL_ FICM_FD SG_ 1022 ICGMPeriodOfBatHeatMonday 5000;
BA_REL_ "GenSigTimeoutTime" BU_SG_REL_ FICM_FD SG_ 1022 ICGMPeriodOfBatHeatTuesday 5000;
BA_REL_ "GenSigTimeoutTime" BU_SG_REL_ FICM_FD SG_ 1022 ICGMPeriodOfBatHeatWednesday 5000;
BA_REL_ "GenSigTimeoutTime" BU_SG_REL_ FICM_FD SG_ 1022 ICGMPeriodOfBatHeatThursday 5000;
BA_REL_ "GenSigTimeoutTime" BU_SG_REL_ FICM_FD SG_ 1022 ICGMPeriodOfBatHeatFriday 5000;
BA_REL_ "GenSigTimeoutTime" BU_SG_REL_ FICM_FD SG_ 1022 ICGMPeriodOfBatHeatSaturday 5000;
BA_REL_ "GenSigTimeoutTime" BU_SG_REL_ FICM_FD SG_ 1022 ICGMPeriodOfBatHeatRepeat 5000;
BA_REL_ "GenSigTimeoutTime" BU_SG_REL_ FICM_FD SG_ 1022 ICGMHourOfBatHeat1 5000;
BA_REL_ "GenSigTimeoutTime" BU_SG_REL_ FICM_FD SG_ 1022 BatHeatOrdStatus1 5000;
BA_REL_ "GenSigTimeoutTime" BU_SG_REL_ FICM_FD SG_ 1022 ICGMMinOfBatHeat1 5000;
BA_REL_ "GenSigTimeoutTime" BU_SG_REL_ FICM_FD SG_ 1022 ICGMPeriodOfBatHeatSunday1 5000;
BA_REL_ "GenSigTimeoutTime" BU_SG_REL_ FICM_FD SG_ 1022 ICGMPeriodOfBatHeatMonday1 5000;
BA_REL_ "GenSigTimeoutTime" BU_SG_REL_ FICM_FD SG_ 1022 ICGMPeriodOfBatHeatTuesday1 5000;
BA_REL_ "GenSigTimeoutTime" BU_SG_REL_ FICM_FD SG_ 1022 ICGMPeriodOfBatHeatWednesday1 5000;
BA_REL_ "GenSigTimeoutTime" BU_SG_REL_ FICM_FD SG_ 1022 ICGMPeriodOfBatHeatThursday1 5000;
BA_REL_ "GenSigTimeoutTime" BU_SG_REL_ FICM_FD SG_ 1022 ICGMPeriodOfBatHeatFriday1 5000;
BA_REL_ "GenSigTimeoutTime" BU_SG_REL_ FICM_FD SG_ 1022 ICGMPeriodOfBatHeatSaturday1 5000;
BA_REL_ "GenSigTimeoutTime" BU_SG_REL_ FICM_FD SG_ 1022 ICGMPeriodOfBatHeatRepeat1 5000;
BA_REL_ "GenSigTimeoutTime" BU_SG_REL_ FICM_FD SG_ 704 IMCUBaaSOvduDay 500;
BA_REL_ "GenSigTimeoutTime" BU_SG_REL_ FICM_FD SG_ 704 BaaSBatIlglAlrm 500;
BA_REL_ "GenSigTimeoutTime" BU_SG_REL_ FICM_FD SG_ 704 IMCUAlrmDspForBaaS 500;
BA_REL_ "GenSigTimeoutTime" BU_SG_REL_ FICM_FD SG_ 755 IMCUChrgTrgtSOCDspCmd 1000;
BA_REL_ "GenSigTimeoutTime" BU_SG_REL_ FICM_FD SG_ 755 IMCUReserCtrlDspCmd 1000;
BA_REL_ "GenSigTimeoutTime" BU_SG_REL_ FICM_FD SG_ 755 IMCUReserChrgCtrlResp 1000;
BA_REL_ "GenSigTimeoutTime" BU_SG_REL_ FICM_FD SG_ 755 IMCUChrgTrgtSOCResp 1000;
BA_REL_ "GenSigTimeoutTime" BU_SG_REL_ FICM_FD SG_ 755 IMCUReserSpMinuteDspCmd 1000;
BA_REL_ "GenSigTimeoutTime" BU_SG_REL_ FICM_FD SG_ 755 IMCUReserStMinuteDspCmd 1000;
BA_REL_ "GenSigTimeoutTime" BU_SG_REL_ FICM_FD SG_ 755 IMCUReserSpHourDspCmd 1000;
BA_REL_ "GenSigTimeoutTime" BU_SG_REL_ FICM_FD SG_ 755 IMCUReserStHourDspCmd 1000;
BA_REL_ "GenSigTimeoutTime" BU_SG_REL_ FICM_FD SG_ 777 CCUOffBdChrgrPlugOnV 1000;
BA_REL_ "GenSigTimeoutTime" BU_SG_REL_ FICM_FD SG_ 777 CCUOffBdChrgrPlugOn 1000;
BA_REL_ "GenSigTimeoutTime" BU_SG_REL_ FICM_FD SG_ 805 IMCUDschrgngEstdElecRngV 1000;
BA_REL_ "GenSigTimeoutTime" BU_SG_REL_ FICM_FD SG_ 805 IMCUDschrgngEstdElecRng 1000;
BA_REL_ "GenSigTimeoutTime" BU_SG_REL_ FICM_FD SG_ 805 IMCUChrgSttnMchngStaResp 1000;
BA_REL_ "GenSigTimeoutTime" BU_SG_REL_ FICM_FD SG_ 805 IMCUAltngChrgCrntResp 1000;
BA_REL_ "GenSigTimeoutTime" BU_SG_REL_ FICM_FD SG_ 805 IMCUAltngChrgCrntDspCmd 1000;
BA_REL_ "GenSigTimeoutTime" BU_SG_REL_ FICM_FD SG_ 805 IMCUDschrgTrgtSOCDspCmd 1000;
BA_REL_ "GenSigTimeoutTime" BU_SG_REL_ FICM_FD SG_ 884 ESSSwapOpDsp 1000;
BA_REL_ "GenSigTimeoutTime" BU_SG_REL_ FICM_FD SG_ 871 SttnESSSwapSta 1000;
BA_REL_ "GenSigTimeoutTime" BU_SG_REL_ FICM_FD SG_ 871 ESSSwapSttnAndVehComSta 1000;
BA_REL_ "GenSigTimeoutTime" BU_SG_REL_ FICM_FD SG_ 871 ESSSwapVehInSwapArea 1000;
BA_REL_ "GenSigTimeoutTime" BU_SG_REL_ FICM_FD SG_ 816 AirSuspUpSts 2000;
BA_REL_ "GenSigTimeoutTime" BU_SG_REL_ FICM_FD SG_ 816 AirSuspDnSts 2000;
BA_REL_ "GenSigTimeoutTime" BU_SG_REL_ FICM_FD SG_ 816 AirSuspHtSetBtnSts 2000;
BA_REL_ "GenSigTimeoutTime" BU_SG_REL_ FICM_FD SG_ 816 AirSuspHeightSts 2000;
BA_REL_ "GenSigTimeoutTime" BU_SG_REL_ FICM_FD SG_ 816 FxdMdSetReqFedbk 2000;
BA_REL_ "GenSigTimeoutTime" BU_SG_REL_ FICM_FD SG_ 816 ECASFctyDeftSetFnd 2000;
BA_REL_ "GenSigTimeoutTime" BU_SG_REL_ FICM_FD SG_ 816 VehRrAxlWgt 2000;
BA_REL_ "GenSigTimeoutTime" BU_SG_REL_ FICM_FD SG_ 762 RFGOprtSts 1500;
BA_REL_ "GenSigTimeoutTime" BU_SG_REL_ FICM_FD SG_ 762 RFGTrgtTemp 1500;
BA_REL_ "GenSigTimeoutTime" BU_SG_REL_ FICM_FD SG_ 762 RFGOprtEndRsn 1500;
BA_REL_ "GenSigTimeoutTime" BU_SG_REL_ FICM_FD SG_ 762 RFGOprtMdSts 1500;
BA_REL_ "GenSigTimeoutTime" BU_SG_REL_ FICM_FD SG_ 762 RFGEngOffOprtSetSts 1500;
BA_REL_ "GenSigTimeoutTime" BU_SG_REL_ FICM_FD SG_ 762 RFGEngOffOprtDur 1500;
BA_REL_ "GenSigTimeoutTime" BU_SG_REL_ FICM_FD SG_ 762 RCPSWEnblSts 1500;
BA_REL_ "GenSigTimeoutTime" BU_SG_REL_ FICM_FD SG_ 967 InnerDsChrgPlug 1000;
BA_REL_ "GenSigTimeoutTime" BU_SG_REL_ FICM_FD SG_ 967 InnerDsChrgPlugV 1000;
BA_REL_ "GenSigTimeoutTime" BU_SG_REL_ FICM_FD SG_ 967 IBDUInnerDsChrgPlugTmpWrn 1000;
BA_REL_ "GenSigTimeoutTime" BU_SG_REL_ FICM_FD SG_ 994 TirePrs_RLOS 5000;
BA_REL_ "GenSigTimeoutTime" BU_SG_REL_ FICM_FD SG_ 994 TirePrs_RROS 5000;
BA_REL_ "GenSigTimeoutTime" BU_SG_REL_ FICM_FD SG_ 994 TireTmp_RLOS 5000;
BA_REL_ "GenSigTimeoutTime" BU_SG_REL_ FICM_FD SG_ 994 TireTmp_RROS 5000;
BA_REL_ "GenSigTimeoutTime" BU_SG_REL_ FICM_FD SG_ 902 StDirSts_PR 5000;
BA_REL_ "GenSigTimeoutTime" BU_SG_REL_ FICM_FD SG_ 902 StTrkPos_PR2 5000;
BA_REL_ "GenSigTimeoutTime" BU_SG_REL_ FICM_FD SG_ 902 StTurnPos_PR 5000;
BA_REL_ "GenSigTimeoutTime" BU_SG_REL_ FICM_FD SG_ 902 StRtaPos_PR2 5000;
BA_REL_ "GenSigTimeoutTime" BU_SG_REL_ FICM_FD SG_ 902 StLgRtaPos_PR 5000;
BA_REL_ "GenSigTimeoutTime" BU_SG_REL_ FICM_FD SG_ 902 StHtSts_PR2 5000;
BA_REL_ "GenSigTimeoutTime" BU_SG_REL_ FICM_FD SG_ 903 StRtaRmndReq_PR 5000;
BA_REL_ "GenSigTimeoutTime" BU_SG_REL_ FICM_FD SG_ 870 CldrYr_UTC 2000;
BA_REL_ "GenSigTimeoutTime" BU_SG_REL_ FICM_FD SG_ 870 CldrMth_UTC 2000;
BA_REL_ "GenSigTimeoutTime" BU_SG_REL_ FICM_FD SG_ 870 CldrDay_UTC 2000;
BA_REL_ "GenSigTimeoutTime" BU_SG_REL_ FICM_FD SG_ 870 HrofDay_UTC 2000;
BA_REL_ "GenSigTimeoutTime" BU_SG_REL_ FICM_FD SG_ 870 MinofHr_UTC 2000;
BA_REL_ "GenSigTimeoutTime" BU_SG_REL_ FICM_FD SG_ 870 CldV_UTC 2000;
BA_REL_ "GenSigTimeoutTime" BU_SG_REL_ FICM_FD SG_ 870 DayV_UTC 2000;
BA_REL_ "GenSigTimeoutTime" BU_SG_REL_ FICM_FD SG_ 870 SecofMin_UTC 2000;
BA_REL_ "GenSigTimeoutTime" BU_SG_REL_ FICM_FD SG_ 1017 InnerV2LResp 5000;
BA_REL_ "GenSigTimeoutTime" BU_SG_REL_ FICM_FD SG_ 1017 InnerV2LDspCmd 5000;
BA_REL_ "GenSigTimeoutTime" BU_SG_REL_ FICM_FD SG_ 1017 OuterV2LResp 5000;
BA_REL_ "GenSigTimeoutTime" BU_SG_REL_ FICM_FD SG_ 1017 InnerV2LBtnSts 5000;
BA_REL_ "GenSigTimeoutTime" BU_SG_REL_ FICM_FD SG_ 1017 OuterV2LBtnSts 5000;
BA_REL_ "GenSigTimeoutTime" BU_SG_REL_ FICM_FD SG_ 1017 InnerDsChrgSpRsn 5000;
BA_REL_ "GenSigTimeoutTime" BU_SG_REL_ FICM_FD SG_ 1017 InnerV2LKeepTimeDspCmd 5000;
BA_REL_ "GenSigTimeoutTime" BU_SG_REL_ FICM_FD SG_ 1017 OuterV2LDspCmd 5000;
BA_REL_ "GenSigTimeoutTime" BU_SG_REL_ FICM_FD SG_ 839 CPDFnSwReqFdbk 2000;
BA_REL_ "GenSigTimeoutTime" BU_SG_REL_ FICM_FD SG_ 839 CPDSysFlt 2000;
BA_REL_ "GenSigTimeoutTime" BU_SG_REL_ FICM_FD SG_ 839 CPDLftWrnng 2000;
BA_REL_ "GenSigTimeoutTime" BU_SG_REL_ FICM_FD SG_ 856 ParalParkingInReqFdbck 5000;
BA_REL_ "GenSigTimeoutTime" BU_SG_REL_ FICM_FD SG_ 856 PerpParkingInReqFdbck 5000;
BA_REL_ "GenSigTimeoutTime" BU_SG_REL_ FICM_FD SG_ 856 ParkingOutReqFdbck 5000;
BA_REL_ "GenSigTimeoutTime" BU_SG_REL_ FICM_FD SG_ 829 HLCSts 1000;
BA_REL_ "GenSigTimeoutTime" BU_SG_REL_ FICM_FD SG_ 829 HLCWrnngLvl 1000;
BA_REL_ "GenSigTimeoutTime" BU_SG_REL_ FICM_FD SG_ 829 HLCSnsrEr 1000;
BA_REL_ "GenSigTimeoutTime" BU_SG_REL_ FICM_FD SG_ 829 HLCMainSwSetReqFdbk 1000;
BA_REL_ "GenSigTimeoutTime" BU_SG_REL_ FICM_FD SG_ 829 HLCFctryDeftSetFnsh 1000;
BA_REL_ "GenSigTimeoutTime" BU_SG_REL_ FICM_FD SG_ 744 MOISSts_R_ChkSum 500;
BA_REL_ "GenSigTimeoutTime" BU_SG_REL_ FICM_FD SG_ 744 SRR_F_MFctryDeftSetFnsh 500;
BA_REL_ "GenSigTimeoutTime" BU_SG_REL_ FICM_FD SG_ 744 MOISSts_R_RllCnt 500;
BA_REL_ "GenSigTimeoutTime" BU_SG_REL_ FICM_FD SG_ 744 MOISMainSwFdbck 500;
BA_REL_ "GenSigTimeoutTime" BU_SG_REL_ FICM_FD SG_ 743 BSISSts_F_ChkSum 500;
BA_REL_ "GenSigTimeoutTime" BU_SG_REL_ FICM_FD SG_ 743 SRR_S_MFctryDeftSetFnsh 500;
BA_REL_ "GenSigTimeoutTime" BU_SG_REL_ FICM_FD SG_ 743 BSISSts_F_RllCnt 500;
BA_REL_ "GenSigTimeoutTime" BU_SG_REL_ FICM_FD SG_ 743 BSISMainSwFdbck 500;
BA_REL_ "GenSigTimeoutTime" BU_SG_REL_ FICM_FD SG_ 1376 DcrtvLmpSwSts 5000;
BA_REL_ "GenSigTimeoutTime" BU_SG_REL_ FICM_FD SG_ 1370 ClnWtrTnk1 5000;
BA_REL_ "GenSigTimeoutTime" BU_SG_REL_ FICM_FD SG_ 1370 KtchGryWtrTnk 5000;
BA_REL_ "GenSigTimeoutTime" BU_SG_REL_ FICM_FD SG_ 1370 TlGryWtrTnk 5000;
BA_REL_ "GenSigTimeoutTime" BU_SG_REL_ FICM_FD SG_ 1365 RrACTempSetSts 5000;
BA_REL_ "GenSigTimeoutTime" BU_SG_REL_ FICM_FD SG_ 1365 RrACMdSts 5000;
BA_REL_ "GenSigTimeoutTime" BU_SG_REL_ FICM_FD SG_ 1365 RrACPwrSts 5000;
BA_REL_ "GenSigTimeoutTime" BU_SG_REL_ FICM_FD SG_ 1365 RrACBlwrLvlSts 5000;
BA_REL_ "GenSigTimeoutTime" BU_SG_REL_ FICM_FD SG_ 1365 RrACTmShtdwnSetFdbck 5000;
BA_REL_ "GenSigTimeoutTime" BU_SG_REL_ FICM_FD SG_ 1281 BMSRptBatCodeIndx 2000;
BA_REL_ "GenSigTimeoutTime" BU_SG_REL_ FICM_FD SG_ 1281 BMSRptBatCodeAsc1 2000;
BA_REL_ "GenSigTimeoutTime" BU_SG_REL_ FICM_FD SG_ 1281 BMSRptBatCodeAsc2 2000;
BA_REL_ "GenSigTimeoutTime" BU_SG_REL_ FICM_FD SG_ 1281 BMSRptBatCodeAsc3 2000;
BA_REL_ "GenSigTimeoutTime" BU_SG_REL_ FICM_FD SG_ 1281 BMSRptBatCodeAsc4 2000;
BA_REL_ "GenSigTimeoutTime" BU_SG_REL_ FICM_FD SG_ 1281 BMSRptBatCodeAsc5 2000;
BA_REL_ "GenSigTimeoutTime" BU_SG_REL_ FICM_FD SG_ 1281 BMSRptBatCodeAsc6 2000;
BA_REL_ "GenSigTimeoutTime" BU_SG_REL_ FICM_FD SG_ 1281 BMSRptBatCodeAsc7 2000;
BA_REL_ "GenSigTimeoutTime" BU_SG_REL_ FICM_FD SG_ 1354 ESSSwapWaitNum 5000;
BA_REL_ "GenSigTimeoutTime" BU_SG_REL_ FICM_FD SG_ 1354 ESSSwapWaitNumV 5000;
BA_REL_ "GenSigTimeoutTime" BU_SG_REL_ FICM_FD SG_ 963 BaaSManuSetngReslt 1000;
BA_REL_ "GenSigTimeoutTime" BU_SG_REL_ FICM_FD SG_ 963 ESSSwapStrgWhlPsd 1000;
BA_REL_ "GenSigTimeoutTime" BU_SG_REL_ FICM_FD SG_ 963 ESSSwapShifterLvrPsd 1000;
BA_REL_ "GenSigTimeoutTime" BU_SG_REL_ FICM_FD SG_ 963 ESSSwapDoorPsd 1000;
BA_REL_ "GenSigTimeoutTime" BU_SG_REL_ FICM_FD SG_ 963 ESSSwapChkPsd 1000;
BA_REL_ "GenSigTimeoutTime" BU_SG_REL_ FICM_FD SG_ 963 ESSSwapBrkPsd 1000;
BA_REL_ "GenSigTimeoutTime" BU_SG_REL_ FICM_FD SG_ 963 ESSSwapEPBPsd 1000;
BA_REL_ "GenSigTimeoutTime" BU_SG_REL_ FICM_FD SG_ 963 ESSSwapSuspdng 1000;
BA_REL_ "GenSigTimeoutTime" BU_SG_REL_ FICM_FD SG_ 1280 SupportQueue 5000;
BA_REL_ "GenSigTimeoutTime" BU_SG_REL_ FICM_FD SG_ 1280 EstdWtngTime 5000;
BA_REL_ "GenSigTimeoutTime" BU_SG_REL_ FICM_FD SG_ 1280 RqungReq 5000;
BA_REL_ "GenSigTimeoutTime" BU_SG_REL_ FICM_FD SG_ 1280 OrderSts 5000;
BA_REL_ "GenSigTimeoutTime" BU_SG_REL_ FICM_FD SG_ 1280 QueueNum 5000;
BA_REL_ "GenSigTimeoutTime" BU_SG_REL_ FICM_FD SG_ 989 OuterV2LBtnDisableRsn 1000;
BA_REL_ "GenSigTimeoutTime" BU_SG_REL_ FICM_FD SG_ 989 InnerV2LBtnDisableRsn 1000;
BA_REL_ "GenSigTimeoutTime" BU_SG_REL_ FICM_FD SG_ 989 VCUInnerDsChrgPlugTmpWrn 1000;
BA_REL_ "GenSigTimeoutTime" BU_SG_REL_ FICM_FD SG_ 989 V2LBtnDisablePtCtrl 1000;
BA_REL_ "GenSigTimeoutTime" BU_SG_REL_ FICM_FD SG_ 989 OuterV2LBtnStsPt 1000;
BA_REL_ "GenSigTimeoutTime" BU_SG_REL_ FICM_FD SG_ 989 InnerV2LBtnStsPt 1000;
BA_REL_ "GenSigTimeoutTime" BU_SG_REL_ FICM_FD SG_ 815 Easy2LoadSetReqFedbk 500;
BA_REL_ "GenSigTimeoutTime" BU_SG_REL_ FICM_FD SG_ 815 TowMdSetReqFedbk 500;
BA_REL_ "GenSigTimeoutTime" BU_SG_REL_ FICM_FD SG_ 815 CampMdSetReqFedbk 500;
BA_REL_ "GenSigTimeoutTime" BU_SG_REL_ FICM_FD SG_ 815 ECASWelcomeSts 500;
BA_REL_ "GenSigTimeoutTime" BU_SG_REL_ FICM_FD SG_ 815 AirSuspTxtMsg2FICM 500;
BA_REL_ "GenSigTimeoutTime" BU_SG_REL_ FICM_FD SG_ 815 AirSuspHeightSts2IPK 500;
BA_REL_ "GenSigTimeoutTime" BU_SG_REL_ FICM_FD SG_ 815 OnBdScaTxtMsg2FICM 500;
BA_REL_ "GenSigTimeoutTime" BU_SG_REL_ FICM_FD SG_ 815 AirSuspTxtMsg2IPK 500;
BA_REL_ "GenSigTimeoutTime" BU_SG_REL_ FICM_FD SG_ 815 PayloadPct 500;
BA_REL_ "GenSigTimeoutTime" BU_SG_REL_ FICM_FD SG_ 815 CurrPayload 500;
BA_REL_ "GenSigTimeoutTime" BU_SG_REL_ FICM_FD SG_ 815 ECASHirBtnSts 500;
BA_REL_ "GenSigTimeoutTime" BU_SG_REL_ FICM_FD SG_ 815 ECASHiBtnSts 500;
BA_REL_ "GenSigTimeoutTime" BU_SG_REL_ FICM_FD SG_ 815 MaxPayload 500;
BA_REL_ "GenSigTimeoutTime" BU_SG_REL_ FICM_FD SG_ 815 ECASStdBtnSts 500;
BA_REL_ "GenSigTimeoutTime" BU_SG_REL_ FICM_FD SG_ 815 ECASLoBtnSts 500;
BA_REL_ "GenSigTimeoutTime" BU_SG_REL_ FICM_FD SG_ 815 ECASLowrBtnSts 500;
BA_REL_ "GenSigTimeoutTime" BU_SG_REL_ FICM_FD SG_ 815 OnBdScaLoadUpdSts 500;
BA_REL_ "GenSigTimeoutTime" BU_SG_REL_ FICM_FD SG_ 815 CurrPayloadDispEna 500;
BA_REL_ "GenSigTimeoutTime" BU_SG_REL_ FICM_FD SG_ 620 EASCAdjReqFedbk 2000;
BA_REL_ "GenSigTimeoutTime" BU_SG_REL_ FICM_FD SG_ 620 EASCPosnSaveFedbk 2000;
BA_REL_ "GenSigTimeoutTime" BU_SG_REL_ FICM_FD SG_ 620 EASCPosnRecFedbk 2000;
BA_REL_ "GenSigTimeoutTime" BU_SG_REL_ FICM_FD SG_ 620 EASCFctyDeftSetFnd 2000;
BA_REL_ "GenSigTimeoutTime" BU_SG_REL_ FICM_FD SG_ 620 EASCErrSts 2000;
BA_REL_ "GenSigTimeoutTime" BU_SG_REL_ FICM_FD SG_ 825 HoodLockSts 5000;
BA_REL_ "GenSigTimeoutTime" BU_SG_REL_ FICM_FD SG_ 825 HoodOprtSts 5000;
BA_REL_ "GenSigTimeoutTime" BU_SG_REL_ FICM_FD SG_ 825 HoodOpnPos 5000;
BA_REL_ "GenSigTimeoutTime" BU_SG_REL_ FICM_FD SG_ 825 HoodOprtMdSts 5000;
BA_REL_ "GenSigTimeoutTime" BU_SG_REL_ FICM_FD SG_ 825 HoodPrkPosSetSts 5000;
BA_REL_ "GenSigTimeoutTime" BU_SG_REL_ FICM_FD SG_ 825 HoodBuzReq 5000;
BA_REL_ "GenSigTimeoutTime" BU_SG_REL_ FICM_FD SG_ 825 HoodAbsAlrm 5000;
BA_REL_ "GenSigTimeoutTime" BU_SG_REL_ FICM_FD SG_ 825 HoodBuzSetSts 5000;
BA_REL_ "GenSigTimeoutTime" BU_SG_REL_ FICM_FD SG_ 825 DrAjr_TnovrEdGt 5000;
BA_REL_ "GenSigTimeoutTime" BU_SG_REL_ FICM_FD SG_ 825 HoodCtrlBtnSts 5000;
BA_REL_ "GenSigTimeoutTime" BU_SG_REL_ FICM_FD SG_ 840 WdwCRPOprtSts 5000;
BA_REL_ "GenSigTimeoutTime" BU_SG_REL_ FICM_FD SG_ 840 WdwCRPPos 5000;
BA_REL_ "GenSigTimeoutTime" BU_SG_REL_ FICM_FD SG_ 607 WadeDep_MaxVal 500;
BA_REL_ "GenSigTimeoutTime" BU_SG_REL_ FICM_FD SG_ 607 WadeDep_MaxPosn 500;
BA_REL_ "GenSigTimeoutTime" BU_SG_REL_ FICM_FD SG_ 607 WadeDep_CurrVal 500;
BA_REL_ "GenSigTimeoutTime" BU_SG_REL_ FICM_FD SG_ 607 WadeDep_CurrPosn 500;
BA_REL_ "GenSigTimeoutTime" BU_SG_REL_ FICM_FD SG_ 607 WadeSenActvSts 500;
BA_REL_ "GenSigTimeoutTime" BU_SG_REL_ FICM_FD SG_ 607 WadeDepDsplyEn 500;
BA_REL_ "GenSigTimeoutTime" BU_SG_REL_ FICM_FD SG_ 607 WadeSenMsgDisp 500;
BA_REL_ "GenSigTimeoutTime" BU_SG_REL_ FICM_FD SG_ 582 RAEBMainSwFdbck 500;
BA_REL_ "GenSigTimeoutTime" BU_SG_REL_ FICM_FD SG_ 582 RCWMainSwFdbck 500;
BA_REL_ "GenSigTimeoutTime" BU_SG_REL_ FICM_FD SG_ 860 SetMntOfEPTOStr 1000;
BA_REL_ "GenSigTimeoutTime" BU_SG_REL_ FICM_FD SG_ 860 EnrgSplFdbk 1000;
BA_REL_ "GenSigTimeoutTime" BU_SG_REL_ FICM_FD SG_ 860 SetHrOfEPTOStr 1000;
BA_REL_ "GenSigTimeoutTime" BU_SG_REL_ FICM_FD SG_ 860 SetMntOfEPTOFnh 1000;
BA_REL_ "GenSigTimeoutTime" BU_SG_REL_ FICM_FD SG_ 860 SetHrOfEPTOFnh 1000;
BA_REL_ "GenSigTimeoutTime" BU_SG_REL_ FICM_FD SG_ 860 EPTOCtrlFdbk 1000;
BA_REL_ "GenSigTimeoutTime" BU_SG_REL_ FICM_FD SG_ 860 EPTODplctEfctSts 1000;
BA_REL_ "GenSigTimeoutTime" BU_SG_REL_ FICM_FD SG_ 860 EPTOStpSOCStsVl 1000;
BA_REL_ "GenSigTimeoutTime" BU_SG_REL_ FICM_FD SG_ 167 IPB_A7h_PDU_00_Chksum 250;
BA_REL_ "GenSigTimeoutTime" BU_SG_REL_ FICM_FD SG_ 167 IPB_A7h_PDU_00_RllCnt 250;
BA_REL_ "GenSigTimeoutTime" BU_SG_REL_ FICM_FD SG_ 167 FWAwarning 250;
BA_REL_ "GenSigTimeoutTime" BU_SG_REL_ FICM_FD SG_ 167 BrkFlWarning 250;
BA_REL_ "GenSigTimeoutTime" BU_SG_REL_ FICM_FD SG_ 167 IPBSts 250;
BA_REL_ "GenSigTimeoutTime" BU_SG_REL_ FICM_FD SG_ 167 CSTSts 250;
BA_REL_ "GenSigTimeoutTime" BU_SG_REL_ FICM_FD SG_ 1002 PhoneRmdrReq2 5000;
BA_REL_ "GenSigTimeoutTime" BU_SG_REL_ FICM_FD SG_ 1002 FODAlrm2 5000;
BA_REL_ "GenSigTimeoutTime" BU_SG_REL_ FICM_FD SG_ 1002 WPCChrgSts2 5000;
BA_REL_ "GenSigTimeoutTime" BU_SG_REL_ FICM_FD SG_ 1519 IPK_InterInfo 5000;
VAL_ 153 EMSSysOpngMdV 0 "Valid" 1 "Invalid" ;
VAL_ 153 EMSSysOpngMd 0 "Default/Unknown" 1 "Normal" 2 "SPORT" 3 "ECO" 4 "Fault" 5 "Reserved" 6 "Reserved" 7 "Reserved" ;
VAL_ 153 WadeModeActSts 0 "off" 1 "on" ;
VAL_ 153 WadeModeDispCmd 0 "No Request" 1 "Powertrain is not Ready" 2 "Enter 4L Low Speed 4WD Mode" 3 "reserve" 4 "reserve" ;
VAL_ 164 BrkFlngMdSts 0 "Normal" 1 "Sport" 2 "Reserve" 3 "Fault" ;
VAL_ 164 IBFSWstate 0 "able" 1 "disable" ;
VAL_ 164 EBSFctryDeftSetFnsh 0 "No Request(Default)" 1 "Successed" 2 "Failed" 3 "Reserved" ;
VAL_ 165 LDrvnWhlRotlDistPlsCtrV 1 "Valid" 0 "Invalid" ;
VAL_ 165 RDrvnWhlRotlDistPlsCtrV 1 "Valid" 0 "Invalid" ;
VAL_ 168 LNonDrvnWhlRotlDistPlsCtrV 1 "Valid" 0 "Invalid" ;
VAL_ 168 RNonDrvnWhlRotlDistPlsCtrV 1 "Valid" 0 "Invalid" ;
VAL_ 169 WhlSpdFLV 1 "Valid" 0 "Invalid" ;
VAL_ 169 WhlSpdFL 32767 "Invalid" ;
VAL_ 169 WhlSpdFRV 1 "Valid" 0 "Invalid" ;
VAL_ 169 WhlSpdFR 32767 "Invalid" ;
VAL_ 169 WhlDircnFL 0 "Undefined" 1 "Standstill" 2 "Forward" 3 "Backward" ;
VAL_ 169 WhlDircnFLV 1 "Valid" 0 "Invalid" ;
VAL_ 169 WhlDircnFR 0 "Undefined" 1 "Standstill" 2 "Forward" 3 "Backward" ;
VAL_ 169 WhlDircnFRV 1 "Valid" 0 "Invalid" ;
VAL_ 170 WhlSpdRLV 1 "Valid" 0 "Invalid" ;
VAL_ 170 WhlSpdRL 32767 "Invalid" ;
VAL_ 170 WhlSpdRRV 1 "Valid" 0 "Invalid" ;
VAL_ 170 WhlSpdRR 32767 "Invalid" ;
VAL_ 170 WhlDircnRL 0 "Undefined" 1 "Standstill" 2 "Forward" 3 "Backward" ;
VAL_ 170 WhlDircnRLV 1 "Valid" 0 "Invalid" ;
VAL_ 170 WhlDircnRR 0 "Undefined" 1 "Standstill" 2 "Forward" 3 "Backward" ;
VAL_ 170 WhlDircnRRV 1 "Valid" 0 "Invalid" ;
VAL_ 337 TCCUSysOpngMd 0 "Mode Unknown" 1 "System Fault" 2 "Mode 2WD" 3 "Mode 4WD (Lock)" 4 "Mode Active (AWD)" 5 "Mode Neutral" 6 "Mode 4WD Low Range" 7 "Sport Mode (Active)" 8 "Unused" 9 "Unused" 10 "Unused" 11 "Unused" 12 "Unused" 13 "Unused" 14 "Unused" 15 "Unused" ;
VAL_ 720 ESCFnOffFdbck_ATS 0 "Normal" 1 "ESC OFF" 2 "ALL OFF" 7 "Fault" ;
VAL_ 720 ATSDrvngMdDisp 0 "Default/Unknown" 1 "Normal" 2 "SPORT" 3 "SNOW" 4 "MUD/NUT" 5 "SAND" 6 "ROCK" 7 "ECO" 8 "CUSTOM" 9 "Fault" 10 "OFF ROAD" 11 "TOW" 12 "WADE" 13 "ROCK CRAWL" 14 "Reserved" 15 "Reserved" ;
VAL_ 720 ATSDrvngMdDispV 0 "Valid" 1 "Invalid" ;
VAL_ 720 ATSMMSts 0 "Not Memory" 1 "Memory" ;
VAL_ 720 EPSMLSts 0 "Not Linkage" 1 "Linkage" ;
VAL_ 710 AirClnrIonizerDspCmd 0 "False" 1 "True" ;
VAL_ 710 AirClnrOnOffDspCmd 0 "OFF" 1 "ON" ;
VAL_ 710 AirClnrAutoDspCmd 0 "False" 1 "True" ;
VAL_ 710 AirClnrUserCustAutoWDC 0 "off" 1 "on" 2 "Reserved" 3 "Function disable" ;
VAL_ 710 AirClnrBlwrLvlDspCmd 0 "Blower off" 1 "1 level" 2 "2 level" 3 "3 level" 4 "4 level" 5 "5 level" 6 "6 level" 7 "Auto blower level" ;
VAL_ 710 AirClnrFltrCsumLvlDspC 0 "Consume 0" 1 "Consume 1/3" 2 "Consume 2/3" 3 "Consume Use up" ;
VAL_ 710 AirClnrFltrLifeV 0 "Valid" 1 "Invalid" ;
VAL_ 592 ATSFnSWReqV 0 "Valid" 1 "Invalid" ;
VAL_ 592 ATSFnSWReq 15 "Reserved" 14 "Reserved" 13 "ROCK CRAWL" 12 "WADE" 11 "TOW" 10 "OFF ROAD" 9 "Fault" 8 "Custom" 7 "ECO" 6 "ROCK" 5 "SAND" 4 "MUD/NUT" 3 "SNOW" 2 "SPORT" 1 "Normal" 0 "Default/Unknown" ;
VAL_ 1008 HVACAirClnrBlwrLvlReq_HMI 7 "7 level" 6 "6 level" 5 "5 level" 4 "4 level" 3 "3 level" 2 "2 level" 1 "1 level" 0 "Blower off" ;
VAL_ 1008 HVACAirClnrBlwrLvlReqV_HMI 0 "Valid" 1 "Invalid" ;
VAL_ 1008 HVACAirClnrUserCustAutoWR_HMI 0 "off" 1 "on" ;
VAL_ 1008 HVACAirClnrOnOffSwReq_HMI 0 "No press" 1 "short press" 2 "reserved" 3 "reserved" ;
VAL_ 1008 HVACAirClnrFltrCLRSR_HMI 0 "No press" 1 "short press" 2 "reserved" 3 "reserved" ;
VAL_ 1008 HVACAirClnrAutoSwReq_HMI 0 "No press" 1 "short press" 2 "reserved" 3 "reserved" ;
VAL_ 1008 HVACAirClnrUserCustAutoWRV_HMI 0 "Valid" 1 "Invalid" ;
VAL_ 325 iTurnSysDispMsgReq 0 "OFF" 1 "请将方向盘打到最大角度" 2 "请解开前后差速锁" 3 "请切换至4L模式/越野模式" 4 "请释放电子驻车" 5 "请挂入行驶挡位" 6 "请关闭车门并系上安全带" 7 "请进入越野蠕行模式" ;
VAL_ 325 iTurnSts 0 "Off" 1 "Standby" 2 "Active" 3 "Failure" ;
VAL_ 325 CCOSysDispMsgReq 0 "OFF" 1 "请关闭车门并系安全带" 2 "请启动发动机" 3 "请锁止中央差速锁" 4 "请释放电子驻车" 5 "请挂入行驶挡位" 6 "Reserved" 7 "Reserved" ;
VAL_ 325 CCOSwLamp 0 "OFF" 1 "ON" ;
VAL_ 325 DrSbltWarn 0 "No Request" 1 "Request（请关闭车门并系好安全带）" ;
VAL_ 325 EPBReWarn 0 "No Request" 1 "Request（请释放电子驻车）" ;
VAL_ 325 OffRoadMdWarn 0 "No Request" 1 "Request（请切换至4L模式/越野模式）" ;
VAL_ 325 ShftDWarn 0 "No Request" 1 "Request（请挂入行驶挡）" ;
VAL_ 325 CCOMDWarn 0 "No Request" 1 "Request（请进入越野蠕行模式）" ;
VAL_ 325 UnLEDLWarn 0 "No Request" 1 "Request（请松开前后差速锁）" ;
VAL_ 325 TrStringWarn 0 "No Request" 1 "Request（请将方向盘打到最大角度）" ;
VAL_ 1019 EPSMdReq_FICM 0 "No Request" 1 "Normal" 2 "Sport" 3 "Comfort" ;
VAL_ 1019 ESCMdReq_FICM 0 "No Request" 1 "Normal" 2 "ESC OFF" 3 "ALL OFF" ;
VAL_ 1019 DrvMdReq_FICM 0 "No Request" 1 "Normal" 2 "SPORT" 3 "ECO" ;
VAL_ 1019 FICMDrvrItndHVBatSOC 127 "No request" ;
VAL_ 1019 IntgltBatEngyManmtDrvModFICM 0 "default" 1 "ElectricityConsumptionFirstMode" 2 "IntelligenceHybridMode" 3 "SOCHold" ;
VAL_ 1019 FICMDrvrItndHVBatSOCV 0 "Valid" 1 "Invalid" ;
VAL_ 1019 IntgltBatEngyManmtDrvModFICMV 0 "Valid" 1 "Invalid" ;
VAL_ 1021 FICMHourOfBatHeat 0 "No request" ;
VAL_ 1021 FICMHeatReq 0 "No Req" 1 "HeatRequest" 2 "StopHeatRequest" 3 "Reserved" ;
VAL_ 1021 FICMBatHeatTmV 1 "Valid" 0 "Invalid" ;
VAL_ 1021 FICMMinOfBatHeat 0 "No request" ;
VAL_ 1021 FICMInnerV2LReq 0 "default" 1 "start Discharge" 2 "stop Discharge" 3 "Reserved" ;
VAL_ 1021 FICMInnerV2LKeepTimeReq 0 "Default" 1 "1" 2 "2" 3 "3" 4 "4" 5 "5" 6 "6" 7 "7" 8 "8" 9 "9" 10 "10" 11 "11" 12 "12" 13 "13" 14 "14" 15 "15" 16 "16" 17 "17" 18 "18" 19 "19" 20 "20" 21 "21" 22 "22" 23 "23" 24 "24" 31 "ClosedInnerV2LKeepTime" ;
VAL_ 1021 FuelModSw 0 "No Request" 1 "Switch on" 2 "Switch off" 3 "Reserved" ;
VAL_ 1021 FICMPeriodOfBatHeatSunday 1 "Sunday is booked" 0 "Sunday is not booked" ;
VAL_ 1021 FICMPeriodOfBatHeatMonday 1 "Monday is booked" 0 "Monday is not booked" ;
VAL_ 1021 FICMPeriodOfBatHeatTuesday 1 "Tuesday is booked" 0 "Tuesday is not booked" ;
VAL_ 1021 FICMPeriodOfBatHeatWednesday 1 "Wednesday is booked" 0 "Wednesday is not booked" ;
VAL_ 1021 FICMPeriodOfBatHeatThursday 1 "Thursday is booked" 0 "Thursday is not booked" ;
VAL_ 1021 FICMPeriodOfBatHeatFriday 1 "Friday is booked" 0 "Friday is not booked" ;
VAL_ 1021 FICMPeriodOfBatHeatSaturday 1 "Saturday is booked" 0 "Saturday is not booked" ;
VAL_ 1021 FICMPeriodOfBatHeatRepeat 1 "Repeat" 0 "No Repeat" ;
VAL_ 1021 FICMHourOfBatHeat1 0 "No request" ;
VAL_ 1021 FICMHeatReq1 0 "No Req" 1 "HeatRequest" 2 "StopHeatRequest" 3 "Reserved" ;
VAL_ 1021 FICMBatHeatTmV1 1 "Valid" 0 "Invalid" ;
VAL_ 1021 FICMMinOfBatHeat1 0 "No request" ;
VAL_ 1021 EnStrtRequest_V2L 0 "No Request" 1 "Switch on" 2 "Switch off" 3 "Reserved" ;
VAL_ 1021 FICMV2XSpSOCReqExt 127 "Invalid" ;
VAL_ 1021 FICMPeriodOfBatHeatSunday1 1 "Sunday is booked" 0 "Sunday is not booked" ;
VAL_ 1021 FICMPeriodOfBatHeatMonday1 1 "Monday is booked" 0 "Monday is not booked" ;
VAL_ 1021 FICMPeriodOfBatHeatTuesday1 1 "Tuesday is booked" 0 "Tuesday is not booked" ;
VAL_ 1021 FICMPeriodOfBatHeatWednesday1 1 "Wednesday is booked" 0 "Wednesday is not booked" ;
VAL_ 1021 FICMPeriodOfBatHeatThursday1 1 "Thursday is booked" 0 "Thursday is not booked" ;
VAL_ 1021 FICMPeriodOfBatHeatFriday1 1 "Friday is booked" 0 "Friday is not booked" ;
VAL_ 1021 FICMPeriodOfBatHeatSaturday1 1 "Saturday is booked" 0 "Saturday is not booked" ;
VAL_ 1021 FICMPeriodOfBatHeatRepeat1 1 "Repeat" 0 "No Repeat" ;
VAL_ 1022 ICGMHourOfBatHeat 0 "No request" ;
VAL_ 1022 BatHeatOrdStatus 0 "No Heat Order" 1 "Heat Order" ;
VAL_ 1022 ICGMMinOfBatHeat 0 "No request" ;
VAL_ 1022 ICGMPeriodOfBatHeatSunday 1 "Sunday is booked" 0 "Sunday is not booked" ;
VAL_ 1022 ICGMPeriodOfBatHeatMonday 1 "Monday is booked" 0 "Monday is not booked" ;
VAL_ 1022 ICGMPeriodOfBatHeatTuesday 1 "Tuesday is booked" 0 "Tuesday is not booked" ;
VAL_ 1022 ICGMPeriodOfBatHeatWednesday 1 "Wednesday is booked" 0 "Wednesday is not booked" ;
VAL_ 1022 ICGMPeriodOfBatHeatThursday 1 "Thursday is booked" 0 "Thursday is not booked" ;
VAL_ 1022 ICGMPeriodOfBatHeatFriday 1 "Friday is booked" 0 "Friday is not booked" ;
VAL_ 1022 ICGMPeriodOfBatHeatSaturday 1 "Saturday is booked" 0 "Saturday is not booked" ;
VAL_ 1022 ICGMPeriodOfBatHeatRepeat 1 "Repeat" 0 "No Repeat" ;
VAL_ 1022 ICGMHourOfBatHeat1 0 "No request" ;
VAL_ 1022 BatHeatOrdStatus1 0 "No Heat Order" 1 "Heat Order" ;
VAL_ 1022 ICGMMinOfBatHeat1 0 "No request" ;
VAL_ 1022 ICGMPeriodOfBatHeatSunday1 1 "Sunday is booked" 0 "Sunday is not booked" ;
VAL_ 1022 ICGMPeriodOfBatHeatMonday1 1 "Monday is booked" 0 "Monday is not booked" ;
VAL_ 1022 ICGMPeriodOfBatHeatTuesday1 1 "Tuesday is booked" 0 "Tuesday is not booked" ;
VAL_ 1022 ICGMPeriodOfBatHeatWednesday1 1 "Wednesday is booked" 0 "Wednesday is not booked" ;
VAL_ 1022 ICGMPeriodOfBatHeatThursday1 1 "Thursday is booked" 0 "Thursday is not booked" ;
VAL_ 1022 ICGMPeriodOfBatHeatFriday1 1 "Friday is booked" 0 "Friday is not booked" ;
VAL_ 1022 ICGMPeriodOfBatHeatSaturday1 1 "Saturday is booked" 0 "Saturday is not booked" ;
VAL_ 1022 ICGMPeriodOfBatHeatRepeat1 1 "Repeat" 0 "No Repeat" ;
VAL_ 812 FICMReserCtrlReq 0 "NoRequest" 1 "ReservationSwitchOn" 2 "ReservationSwitchOff" 3 "Reserved" ;
VAL_ 812 FICMChrgTrgtSOCReq 0 "Default" 1 "40" 2 "50" 3 "60" 4 "70" 5 "80" 6 "90" 7 "100" ;
VAL_ 812 FICMAltngChrgCrntReq 0 "Default" 1 "6A" 2 "8A" 3 "16A" 4 "MaxCurrent" ;
VAL_ 812 FICMV2XSpSOCReq 0 "Default" 1 "20percent" 2 "30percent" 3 "40percent" 4 "50percent" 5 "60percent" 6 "70percent" 7 "80percent" ;
VAL_ 704 BaaSBatIlglAlrm 0 "False" 1 "True" ;
VAL_ 704 IMCUAlrmDspForBaaS 0 "Default" 1 "reminding_overdue_days" 2 "Reminding_user_to_recharge" 3 "Vehicle_isUnable_to_ConnectCloud" 4 "Communication_Fault" 5 "Illegal_Battery" ;
VAL_ 755 IMCUChrgTrgtSOCDspCmd 0 "Default" 1 "40percent" 2 "50percent" 3 "60percent" 4 "70percent" 5 "80percent" 6 "90percent" 7 "100percent" ;
VAL_ 755 IMCUReserCtrlDspCmd 0 "NoRequest" 1 "ReservationSwitchOn" 2 "ReservationSwitchOff" 3 "ExtendCharging" ;
VAL_ 755 IMCUReserChrgCtrlResp 0 "Default" 1 "CommandExecutedSuccessful" 2 "Failed_EepromStorageFailed" 3 "Failed_SetAuto_wakeupFailed" 4 "Failed_ReservationChargeTimeUnreasonable" 5 "Failed_ReservationChargeFunctionUnavailable" 7 "Failed_Others" ;
VAL_ 755 IMCUChrgTrgtSOCResp 0 "Default" 1 "CommandExecutedSuccessful" 2 "Failed_EepromStorageFailed" 7 "Failed_Others" ;
VAL_ 777 CCUOffBdChrgrPlugOnV 1 "Invalid" 0 "Valid" ;
VAL_ 777 CCUOffBdChrgrPlugOn 0 "Disconnected" 1 "Connected" 2 "Semi-connected" ;
VAL_ 805 IMCUDschrgngEstdElecRngV 0 "Valid" 1 "Invalid" ;
VAL_ 805 IMCUChrgSttnMchngStaResp 0 "Default" 1 "ChargeStationMatchingSuccess" 2 "ChargeStationMatchingFailure" 3 "Reserved" ;
VAL_ 805 IMCUAltngChrgCrntResp 0 "Default" 1 "CommandExecutedSuccessful" 2 "Failed_EepromStorageFailed" 3 "Failed_CurrentExceedChargerCapacity" 7 "Failed_Others" ;
VAL_ 805 IMCUAltngChrgCrntDspCmd 0 "Default" 1 "6A" 2 "8A" 3 "16A" 4 "MaxCurrent" ;
VAL_ 805 IMCUDschrgTrgtSOCDspCmd 0 "Default" 1 "20%" 2 "30%" 3 "40%" 4 "50%" 5 "60%" 6 "70%" 7 "80%" ;
VAL_ 884 ESSSwapOpDsp 0 "Default" 1 "manual parking instruction" 2 "locating" 3 "location succeeded_stop vehicle" 4 "location succeeded" 5 "location failed" 6 "ESS Swap Process Indication" 7 "ESS Swap started" 8 "ESS Swap Fault" 9 "ESS Swap finished" 10 "ESS Swap succeeded" 11 "ESS Swap preparing" ;
VAL_ 871 SttnESSSwapSta 0 "Default" 1 "Preparing" 2 "Preparation_Completed" 3 "Installing" 4 "Installed" 5 "Success" 6 "Fault" 7 "Failed" 8 "suspended" ;
VAL_ 871 ESSSwapSttnAndVehComSta 0 "Default" 1 "Connected" 2 "Fault" 3 "Reserved" ;
VAL_ 871 ESSSwapVehInSwapArea 0 "No Request" 1 "Request" ;
VAL_ 1006 FICMChrgCtrlReq 0 "NoRequest" 1 "StartCharge" 2 "StopCharge" 3 "Reserved" ;
VAL_ 1006 FICMOnRutWarmOffReq 0 "Default" 1 "EnableOnRouteWarm" 2 "DisableOnRouteWarm" ;
VAL_ 1006 FICMChrgSttnMchngSta 0 "None" 1 "ChargeStationMatchingSuccess" 2 "ChargeStationMatchingFailure" 3 "Reserved" ;
VAL_ 1006 FICMEleccLckCtrlReq 0 "NoRequest" 1 "Lock" 2 "Unlock" 3 "Reserved" ;
VAL_ 1006 DsttnTypOfNav 0 "Unknown" 1 "SlowChargingStation" 2 "FastChargingStation" ;
VAL_ 1006 FICMOnRutWarmOffReqV 0 "Valid" 1 "Invalid" ;
VAL_ 1006 NavGudcSts 0 "NotInGuidance" 1 "InGuidance" ;
VAL_ 1006 FICMV2XReq 0 "Default" 1 "start Discharge" 2 "stop Discharge" 3 "Reserved" ;
VAL_ 816 AirSuspUpSts 0 "None" 1 "Flash" ;
VAL_ 816 AirSuspDnSts 0 "None" 1 "Flash" ;
VAL_ 816 AirSuspHtSetBtnSts 0 "ALL the buttons can be set" 1 "ALL the buttons can not be set" 2 "Only the higher and lower button can not be set" 3 "Only the low and lower button can not be set" 4 "Only the high and higher button can not be set" 5 "Only the low, lower and higher button can not be set" 6 "Only the high, higher and lower button can not be set" 7 "Reserved" ;
VAL_ 816 AirSuspHeightSts 0 "Default" 1 "Higher" 2 "High" 3 "Standard" 4 "Low" 5 "Lower" 6 "Reserved" 7 "Reserved" ;
VAL_ 816 FxdMdSetReqFedbk 0 "Mode OFF" 1 "Mode ON" 2 "Mode is Disable" 3 "Reserved" ;
VAL_ 816 ECASFctyDeftSetFnd 0 "No Request" 1 "Successed" 2 "Failed" 3 "Reserved" ;
VAL_ 762 RFGOprtSts 0 "OFF" 1 "ON" 3 "Invalid" ;
VAL_ 762 RFGTrgtTemp 63 "Invalid" ;
VAL_ 762 RFGOprtEndRsn 0 "Normal Work" 1 "Normal shutdown" 2 "Refrigerator Fault" 3 "Lost communication with RFG " 4 "Refrigerator Power Supply Fault" 5 "Low SOC or discharge power" 6 "In Charging " 7 "Hood Open" 8 "Other Reason" 15 "Invalid" ;
VAL_ 762 RFGOprtMdSts 0 "Cooling" 1 "Heat" 3 "Invalid" ;
VAL_ 762 RFGEngOffOprtSetSts 0 "Disable" 1 "Enable" ;
VAL_ 762 RFGEngOffOprtDur 31 "Invalid" ;
VAL_ 762 RCPSWEnblSts 0 "Enable" 1 "Disable" ;
VAL_ 967 InnerDsChrgPlug 0 "Disconnected" 1 "Connected" ;
VAL_ 967 InnerDsChrgPlugV 0 "Invalid" 1 "Valid" ;
VAL_ 967 IBDUInnerDsChrgPlugTmpWrn 0 "No warning" 1 "High Temperature warning" 2 "Medium Temperature warning" 3 "Lost Sensor" 4 "Sensor failure" 5 "Reserved" ;
VAL_ 994 TirePrs_RLOS 255 "Invalid Value" ;
VAL_ 994 TirePrs_RROS 255 "Invalid Value" ;
VAL_ 994 TireTmp_RLOS 255 "Invalid Value" ;
VAL_ 994 TireTmp_RROS 255 "Invalid Value" ;
VAL_ 902 StDirSts_PR 0 "Forward" 1 "Backward" 2 "Sideward" 3 "Unknown" ;
VAL_ 902 StTrkPos_PR2 127 "Invalid（百分比位置信号）" ;
VAL_ 902 StTurnPos_PR 127 "Invalid（百分比位置信号）" ;
VAL_ 902 StRtaPos_PR2 127 "Invalid（百分比位置信号）" ;
VAL_ 902 StLgRtaPos_PR 127 "Invalid（百分比位置信号）" ;
VAL_ 902 StHtSts_PR2 0 "OFF" 1 "LOW" 2 "MEDIUM" 3 "HIGH" ;
VAL_ 903 StRtaRmndReq_PR 0 "No Request" 1 "Prepare" 2 "In Progress" 3 "Failed" 4 "Completed" 5 "Seat Occupied" 6 "No P" 7 "Stop" ;
VAL_ 870 CldrMth_UTC 12 "December" 11 "November" 10 "October" 9 "September" 8 "August" 7 "July" 6 "June" 5 "May" 4 "April" 3 "March" 2 "February" 1 "January" 0 "Unknown" ;
VAL_ 870 CldV_UTC 1 "Valid" 0 "Invalid" ;
VAL_ 870 DayV_UTC 1 "Valid" 0 "Invalid" ;
VAL_ 927 CldDiagGPSPermsnSwReq_HMI 0 "No Request" 1 "Disable（关闭）" 2 "Single Enable（单次）" 3 "7Days Enable （7天）" 4 "1Month Enable（30天）" 5 "3Months Enable（90天）" 6 "6Months Enable （180天）" 7 "1year Enable （365天）" 8 "3years Enable" 9 "Reserved" 10 "Reserved" 11 "Reserved" 12 "Reserved" 13 "Reserved" 14 "Reserved" 15 "Reserved" ;
VAL_ 927 VehPosPermsnSwReq_HMI 0 "No Request" 1 "Disable（关闭）" 2 "Single Enable（单次）" 3 "7Days Enable （7天）" 4 "1Month Enable（30天）" 5 "3Months Enable（90天）" 6 "6Months Enable （180天）" 7 "1year Enable （365天）" 8 "3years Enable" 9 "Reserved" 10 "Reserved" 11 "Reserved" 12 "Reserved" 13 "Reserved" 14 "Reserved" 15 "Reserved" ;
VAL_ 927 PrvyCtrlAPNCnctnSts 0 "APN OFF" 1 "APN ON" ;
VAL_ 927 PrvyPlyAuthSts 0 "Reject" 1 "Agree" ;
VAL_ 927 CldDiagPosPermsnSwSts 0 "Invalid" 1 "Disable（关闭）" 2 "Single Enable（单次）" 3 "7Days Enable （7天）" 4 "1Month Enable（30天）" 5 "3Months Enable（90天）" 6 "6Months Enable （180天）" 7 "1year Enable （365天）" 8 "3years Enable (1095天)" 9 "Enable（开启）" 10 "Reserved" 11 "Reserved" 12 "Reserved" 13 "Reserved" 14 "Reserved" 15 "Reserved" ;
VAL_ 927 MobileAppPosPermsnSwSts 0 "Invalid" 1 "Disable（关闭）" 2 "Single Enable（单次）" 3 "7Days Enable （7天）" 4 "1Month Enable（30天）" 5 "3Months Enable（90天）" 6 "6Months Enable （180天）" 7 "1year Enable （365天）" 8 "3years Enable (1095天)" 9 "Enable（开启）" 10 "Reserved" 11 "Reserved" 12 "Reserved" 13 "Reserved" 14 "Reserved" 15 "Reserved" ;
VAL_ 927 VehPosPermsnMnSwSts 0 "Invalid" 1 "Disable（关闭）" 2 "Single Enable（单次）" 3 "7Days Enable （7天）" 4 "1Month Enable（30天）" 5 "3Months Enable（90天）" 6 "6Months Enable（180天）" 7 "1year Enable（365天）" 8 "3years Enable（1095天）" ;
VAL_ 927 MicPermsnMnSwSts 0 "Invalid" 1 "Disable（关闭）" 2 "Single Enable（单次）" 3 "7Days Enable （7天）" 4 "1Month Enable（30天）" 5 "3Monhs Enable（90天）" 6 "6Months Enable（180天）" 7 "1year Enable（365天）" 8 "3years Enable（1095天)" ;
VAL_ 927 IterCamPermsnMnSwSts 0 "Invalid" 1 "Disable（关闭）" 2 "Single Enable（单次）" 3 "7Days Enable（7天）" 4 "1Month Enable（30天）" 5 "3Months Enable（90天）" 6 "6Months Enable（180天）" 7 "1year Enable（365天）" 8 "3years Enable（1095天）" ;
VAL_ 938 SpdLmtUnt 0 "Unknown" 1 "MPH" 2 "KMH" 3 "Reserved" ;
VAL_ 938 MAPCovSts 0 "Unknown" 1 "Covered" 2 "Uncovered" 3 "Fault" ;
VAL_ 938 CurrPosSts 0 "Unknown" 1 "Positioned" 2 "Unpositioned" 3 "Fault" ;
VAL_ 938 MAPConfidence 0 "0" 1 "10%" 2 "20%" 3 "30%" 4 "40%" 5 "50%" 6 "60%" 7 "70%" 8 "80%" 9 "90%" 10 "100%" ;
VAL_ 938 SpdLmtType 0 "Unknown " 1 "Implicit " 2 "Explicit" 3 "Reserved" ;
VAL_ 938 CurrRoadType 0 "Unknown" 1 "Highway" 2 "Ramp" 3 "Other" 4 "Reserved" 5 "Reserved" 6 "Reserved" 7 "Reserved" ;
VAL_ 939 StTrkPosReq_DR_HMI 127 "No Request" ;
VAL_ 939 StRtaPosReq_DR_HMI 127 "No Request" ;
VAL_ 1017 InnerV2LResp 0 "default" 1 "CommandExecutedSuccessful" 2 "Failed_OBC Fault" 3 "Others" ;
VAL_ 1017 InnerV2LDspCmd 0 "No Request" 1 "start Discharge" 2 "stop Discharge" 3 "Preparing" ;
VAL_ 1017 OuterV2LResp 0 "Default" 1 "Command Executed Successful" 2 "Failed_OBC_Fault" 3 "Failed, Others" ;
VAL_ 1017 InnerV2LBtnSts 0 "Disable" 1 "Enable" ;
VAL_ 1017 OuterV2LBtnSts 0 "Disable" 1 "Enable" ;
VAL_ 1017 InnerDsChrgSpRsn 0 "Default" 1 "CCUOffBdChrgrPlugOn = Connected" 2 "CCUOnbdChrgrPlugOn ≠ Disconnected" 3 "over temperature" 4 "Lost comuncation with OBC or OBC system fault" 5 "Over load" 6 "The discharging time is arrived" 7 "The Power SOC is ended" 8 "Others" ;
VAL_ 1017 InnerV2LKeepTimeDspCmd 0 "ClosedInnerV2LKeepTime" 1 "1" 2 "2" 3 "3" 4 "4" 5 "5" 6 "6" 7 "7" 8 "8" 9 "9" 10 "10" 11 "11" 12 "12" 13 "13" 14 "14" 15 "15" 16 "16" 17 "17" 18 "18" 19 "19" 20 "20" 21 "21" 22 "22" 23 "23" 24 "24" ;
VAL_ 1017 OuterV2LDspCmd 0 "No Request" 1 "start Discharge" 2 "stop Discharge" 3 "Preparing" ;
VAL_ 839 CPDFnSwReqFdbk 0 "Off" 1 "On" ;
VAL_ 839 CPDSysFlt 0 "No Fault" 1 "System Fault" ;
VAL_ 839 CPDLftWrnng 0 "No Warnning" 1 "Left Warnning" ;
VAL_ 856 ParalParkingInReqFdbck 0 "Accept" 1 "Not Accept" 3 "Reserved" ;
VAL_ 856 PerpParkingInReqFdbck 0 "Accept" 1 "Not Accept" 3 "Reserved" ;
VAL_ 856 ParkingOutReqFdbck 0 "Accept" 1 "Not Accept" 3 "Reserved" ;
VAL_ 855 ParalParkingInReq 0 "No request" 1 "Request" ;
VAL_ 855 PerpParkingInReq 0 "No request" 1 "Request" ;
VAL_ 855 ParkingOutReq 0 "No request" 1 "Request" ;
VAL_ 829 HLCSts 0 "Invalid" 1 "Starting" 2 "Standby" 3 "Working" 4 "Closing" 5 "Breakdown" 6 "Reserved" 7 "Reserved" ;
VAL_ 829 HLCWrnngLvl 0 "No Warning" 1 "Level 1" 2 "Level 2" 3 "Level 3" ;
VAL_ 829 HLCSnsrEr 7 "Reserved" 6 "Reserved" 5 "Service Required" 4 "Signal Receiving Error" 3 "Sensor Blocked" 2 "Sensor Overheating" 1 "System Initialization" 0 "No Error" ;
VAL_ 829 HLCMainSwSetReqFdbk 0 "OFF" 1 "ON" ;
VAL_ 829 HLCFctryDeftSetFnsh 0 "False" 1 "True" ;
VAL_ 744 SRR_F_MFctryDeftSetFnsh 0 "No Request" 1 "Successed" 2 "Failed" 3 "Reserved" ;
VAL_ 744 MOISMainSwFdbck 1 "ON" 0 "OFF" ;
VAL_ 743 SRR_S_MFctryDeftSetFnsh 0 "No Request" 1 "Successed" 2 "Failed" 3 "Reserved" ;
VAL_ 743 BSISMainSwFdbck 1 "ON" 0 "OFF" ;
VAL_ 1376 DcrtvLmpSwSts 0 "OFF" 1 "ON" ;
VAL_ 1370 ClnWtrTnk1 127 "Invalid" ;
VAL_ 1370 KtchGryWtrTnk 127 "Invalid" ;
VAL_ 1370 TlGryWtrTnk 127 "Invalid" ;
VAL_ 1365 RrACTempSetSts 15 "Invalid" ;
VAL_ 1365 RrACMdSts 0 "Auto（自动）" 1 "Cool（制冷）" 2 "hot（制热）" 3 "Blower（送风）" 4 "Dehumidify（除湿）" 5 "Force（强力）" 6 "Eco（节能）" 7 "Reserved" ;
VAL_ 1365 RrACPwrSts 0 "Power Off" 1 "Power On" ;
VAL_ 1365 RrACBlwrLvlSts 0 "Low（低速）" 1 "Middle（中速）" 2 "High（高速）" 3 "Reserved" ;
VAL_ 1365 RrACTmShtdwnSetFdbck 0 "Off" 1 "1h" 2 "2h" 3 "3h" 4 "4h" 5 "5h " 6 "6h" 7 "7h" 8 "8h" 9 "Reserved" 10 "Reserved" 11 "Reserved" 12 "Reserved" 13 "Reserved" 14 "Reserved" 15 "Reserved" ;
VAL_ 1354 ESSSwapWaitNumV 0 "Valid
" 1 "Invalid
" ;
VAL_ 963 BaaSManuSetngReslt 0 "Default" 1 "Success" 2 "Failed" 3 "Reserved" ;
VAL_ 963 ESSSwapStrgWhlPsd 0 "Not Passed" 1 "Passed" ;
VAL_ 963 ESSSwapShifterLvrPsd 0 "Not Passed" 1 "Passed" ;
VAL_ 963 ESSSwapDoorPsd 0 "Not Passed" 1 "Passed" ;
VAL_ 963 ESSSwapChkPsd 0 "False" 1 "True" ;
VAL_ 963 ESSSwapBrkPsd 0 "Not Passed" 1 "Passed" ;
VAL_ 963 ESSSwapEPBPsd 0 "Not Passed" 1 "Passed" ;
VAL_ 963 ESSSwapSuspdng 0 "False" 1 "True" ;
VAL_ 1280 SupportQueue 0 "not_supported" 1 "supported" 3 "unknow" ;
VAL_ 1280 RqungReq 0 "No Request" 1 "Requeuing remind " ;
VAL_ 1280 OrderSts 0 "change_battery_success" 1 "change_battery_failed" 2 "wait_for_change_not_arrive" 4 "wait_for_change_arrived" 5 "battery_changing" 6 "battery_changing_second" 7 "canclled_for_timeout" 8 "cancelled_for_end_line" 9 "cancelled_by_user" 10 "cancelled_by_client_service" 11 "station_fault" 12 "cancelled_for_station_fault" 15 "no_order_in_process" ;
VAL_ 989 OuterV2LBtnDisableRsn 0 "无故障" 1 "请先调整放电截止电量低于当前车辆剩余电量，再开启车外放电" 2 "请先连接放电枪，再开启车外放电" 4 "车外放电接口温度过高，请冷却后再试" 8 "动力电池可用放电能力不足，请等待电池进入工作温度" 16 "请先断开充电枪，再开启车外放电。" 32 "Reserve" 64 "请先结束直流充电，再开启车外放电。" 128 "放电系统故障(即全部用户无法自行排除的条件)" ;
VAL_ 989 InnerV2LBtnDisableRsn 0 "无故障" 1 "请先调整放电截止电量低于当前车辆剩余电量，再开启车外放电" 2 "请先启动车辆，再开启车内放电" 4 "车内放电插座温度异常，请10分钟后再试" 8 "动力电池可用放电能力不足，请等待电池进入工作温度" 16 "请先断开充电枪，再开启车内放电。" 32 "请先结束交流充电，再开启车内放电。" 64 "请先结束直流充电，再开启车内放电。" 128 "放电系统故障(即全部用户无法自行排除的条件)" ;
VAL_ 989 VCUInnerDsChrgPlugTmpWrn 0 "No warning" 1 "High Temperature warning" 2 "Medium Temperature warning" 3 "Lost Sensor" 4 "Sensor failure" 5 "Reserved" ;
VAL_ 989 V2LBtnDisablePtCtrl 0 "非PT侧控制" 1 "PT侧控制" ;
VAL_ 989 OuterV2LBtnStsPt 0 "Disable" 1 "Enable" ;
VAL_ 989 InnerV2LBtnStsPt 0 "Disable" 1 "Enable" ;
VAL_ 815 Easy2LoadSetReqFedbk 0 "Mode OFF" 1 "Mode ON" 2 "Mode is Disable" 3 "Reserved" ;
VAL_ 815 TowMdSetReqFedbk 0 "Mode OFF" 1 "Mode ON" 2 "Mode is Disable" 3 "Reserved" ;
VAL_ 815 CampMdSetReqFedbk 0 "Mode OFF" 1 "Mode ON" 2 "Mode is Disable" 3 "Reserved" ;
VAL_ 815 ECASWelcomeSts 0 "Mode OFF" 1 "Mode ON" 2 "Mode is Disable" 3 "Reserved" ;
VAL_ 815 AirSuspTxtMsg2FICM 0 "No Message" 1 "Ride Height is Highest" 2 "Ride Height is High" 3 "Ride Height is Standard" 4 "Ride Height is Low" 5 "Ride Height is Lowest" 6 "Ride Height is Extreme High" 7 "Lifting Suspension" 8 "Lowering Suspension" 9 "Suspension Stop Adjusting" 10 "Please Drive to Flat Road" 11 "Ride Height Abnormal" 12 "ECAS Function Limited" 13 "Reserved" 14 "Reserved" 15 "Reserved" 16 "Reserved" 17 "Reserved" 18 "Reserved" 19 "Reserved" 20 "Reserved" 21 "Reserved" 22 "Reserved" 23 "Reserved" 24 "Reserved" 25 "Reserved" 26 "Reserved" 27 "Reserved" 28 "Reserved" 29 "Reserved" 30 "Reserved" 31 "Reserved" ;
VAL_ 815 AirSuspHeightSts2IPK 0 "Default" 1 "Highest" 2 "High" 3 "Standard" 4 "Low" 5 "Lowest" 6 "Extreme High" 7 "Reserved" ;
VAL_ 815 OnBdScaTxtMsg2FICM 0 "No Message" 1 "Onboard Scales Working" 2 "Scaling Completed" 3 "Scaling Failed Please Try Again" 4 "Onboard Scales not Available" 5 "ECAS Function Limited" 6 "Reserved" 7 "Reserved" 8 "Reserved" 9 "Reserved" 10 "Reserved" 11 "Reserved" 12 "Reserved" 13 "Reserved" 14 "Reserved" 15 "Reserved" ;
VAL_ 815 AirSuspTxtMsg2IPK 0 "Default" 1 "Lifting Suspension" 2 "Lowering Suspension" 3 "Suspension Stop Adjusting" 4 "Please Drive to Flat Road" 5 "ECAS Compressor Cooling" 6 "Vehicle Overload ECAS Function Limited" 7 "Reserved" 8 "Reserved" 9 "Reserved" 10 "Reserved" 11 "Reserved" 12 "Reserved" 13 "Reserved" 14 "Reserved" 15 "Reserved" ;
VAL_ 815 CurrPayload 2047 "Invalid" ;
VAL_ 815 ECASHirBtnSts 0 "Button can be set" 1 "Button can not be set" ;
VAL_ 815 ECASHiBtnSts 0 "Button can be set" 1 "Button can not be set" ;
VAL_ 815 MaxPayload 2047 "Invalid" ;
VAL_ 815 ECASStdBtnSts 0 "Button can be set" 1 "Button can not be set" ;
VAL_ 815 ECASLoBtnSts 0 "Button can be set" 1 "Button can not be set" ;
VAL_ 815 ECASLowrBtnSts 0 "Button can be set" 1 "Button can not be set" ;
VAL_ 815 OnBdScaLoadUpdSts 0 "Button can be set" 1 "Button can not be set" ;
VAL_ 815 CurrPayloadDispEna 0 "Disable" 1 "Enable" ;
VAL_ 620 EASCAdjReqFedbk 0 "EASC Adjust OFF" 1 "EASC Adjust ON" 2 "EASC Adjust Disable" 3 "Reserved" ;
VAL_ 620 EASCPosnSaveFedbk 0 "Default" 1 "Saved Success" ;
VAL_ 620 EASCPosnRecFedbk 0 "Default" 1 "Recovered Success" ;
VAL_ 620 EASCFctyDeftSetFnd 0 "No Request" 1 "Successed" 2 "Failed" 3 "Reserved" ;
VAL_ 620 EASCErrSts 0 "No Error" 1 "Error Level 1" 2 "Error Level 2" 3 "Error Level 3" ;
VAL_ 825 HoodLockSts 0 "Status Unkown" 1 "Open" 2 "HalfLocked" 3 "FullyClosed" ;
VAL_ 825 HoodOprtSts 0 "Hold" 1 "Opening" 2 "Closing " 3 "Unknown" ;
VAL_ 825 HoodOpnPos 127 "Default" ;
VAL_ 825 HoodOprtMdSts 0 "Invalid" 1 "Manual" 2 "Auto" 3 "UnLearned" ;
VAL_ 825 HoodPrkPosSetSts 0 "60% " 1 "70% " 2 "80%" 3 "90% " 4 "100%" 7 "Invalid" ;
VAL_ 825 HoodBuzReq 0 "No Request" 1 "Long beep 1 time" 2 "SetupSuccessTone" 3 "Short beep 2 times" 4 "Short beep 3 times" 5 "Short beep 4 times" 6 "Short beep 5 times" 7 "Short beep 6 times" ;
VAL_ 825 HoodAbsAlrm 0 "No Request" 1 "In Abuse Mode 1" 2 "In Abuse Mode 2" 3 "In Abuse Mode 3" ;
VAL_ 825 HoodBuzSetSts 0 "Invalid " 1 "Enable " 2 "Disable" ;
VAL_ 825 DrAjr_TnovrEdGt 1 "Open" 0 "Close" ;
VAL_ 825 HoodCtrlBtnSts 0 "Disable " 1 "Enable" ;
VAL_ 831 HoodPrkPosReq 127 "No Request" ;
VAL_ 831 HoodOprtMdReq 0 "No Request" 1 "Manual（手动模式，仅支持解锁）" 2 "Auto（自动模式）" ;
VAL_ 831 HoodPrkPosSetReq 0 "60% " 1 "70%" 2 "80% " 3 "90%" 4 "100% " 7 "No Request" ;
VAL_ 831 HoodOprtReq 0 "No request" 1 "Manual release" 2 "Open" 3 "Close" 4 "Hold" ;
VAL_ 831 HoodBuzSet 0 "No Request " 1 "Enable " 2 "Disable" ;
VAL_ 831 Wdw_CRPAutoOprtnReq 122 "Stop" 127 "No Request" ;
VAL_ 831 CRPUnLckReq 0 "No Request" 1 "Unlock" ;
VAL_ 840 WdwCRPOprtSts 0 "Idle " 1 "Moving Up " 2 "Moving Down" ;
VAL_ 840 WdwCRPPos 127 "Position Unknown" ;
VAL_ 607 WadeSenActvSts 0 "WadeSensing OFF" 1 "WadeSensing ON" 2 "WadeSensing Disable" 3 "WadeSensing Fault" ;
VAL_ 607 WadeDepDsplyEn 0 "Disable" 1 "Enable" ;
VAL_ 607 WadeSenMsgDisp 0 "No Message" 1 "WadeMessage1" 2 "WadeMessage2" 3 "WadeMessage3" 4 "WadeMessage4" 5 "WadeMessage5" 6 "WadeMessage6" 7 "WadeMessage7" 8 "WadeMessage8" 9 "WadeMessage9" 10 "WadeMessage10" 11 "WadeMessage11" 12 "WadeMessage12" 13 "WadeMessage13" 14 "WadeMessage14" 15 "WadeMessage15" 16 "Reserved" 31 "Reserved" ;
VAL_ 582 RAEBMainSwFdbck 1 "ON" 0 "OFF" ;
VAL_ 582 RCWMainSwFdbck 1 "ON" 0 "OFF" ;
VAL_ 1385 FICMCampMdDrvrItndGennSts 0 "Auto" 1 "Start_Engine" 2 "Stop_Engine" ;
VAL_ 1385 FICMCampMdDrvrItndGennStsV 0 "Valid" 1 "Invalid" ;
VAL_ 1385 FICMCampMdDrvrItndSOCMinV 0 "Valid" 1 "Invalid" ;
VAL_ 1385 FICMCampMdDrvrItndGtnLvlV 0 "Valid" 1 "Invalid" ;
VAL_ 1385 FICMCampMdReqV 0 "Valid" 1 "Invalid" ;
VAL_ 1385 FICMCampMdReq 0 "Off" 1 "On" ;
VAL_ 1385 FICMCampMdDrvrItndSOCMaxV 0 "Valid" 1 "Invalid" ;
VAL_ 861 FICMMntOfEPTOStrStReq 63 "default" ;
VAL_ 861 FICMHrOfEPTOFStrStReq 31 "default" ;
VAL_ 861 FICMMntOfEPTOFnhStReq 63 "default" ;
VAL_ 861 FICMHrOfEPTOFnhStReq 31 "default" ;
VAL_ 861 EPTOCtrlReq 0 "No request" 1 "ON" 2 "OFF" 3 "Reservation" ;
VAL_ 861 EPTODplctEfctStReq 0 "NO request" 1 "NO Repeatedly request" 2 "Effective Repeatedly request" ;
VAL_ 861 EPTOStpSOCStReq 0 "No Request" 1 "10%" 2 "20%" 3 "30%" 4 "40%" 5 "50%" 6 "60%" 7 "70%" 8 "80%" ;
VAL_ 860 SetMntOfEPTOStr 63 "default" ;
VAL_ 860 EnrgSplFdbk 0 "default" 1 "Unable to maintain the Energy Supply(SOC low)" 2 "Unable to maintain the Energy Supply(system failure)" ;
VAL_ 860 SetHrOfEPTOStr 31 "default" ;
VAL_ 860 SetMntOfEPTOFnh 63 "default" ;
VAL_ 860 SetHrOfEPTOFnh 31 "default" ;
VAL_ 860 EPTOCtrlFdbk 0 "OFF" 1 "ON" 2 "Reservation" ;
VAL_ 860 EPTODplctEfctSts 0 "No Repeatedly" 1 "Effective Repeatedly" ;
VAL_ 860 EPTOStpSOCStsVl 0 "Default" 1 "10%" 2 "20%" 3 "30%" 4 "40%" 5 "50%" 6 "60%" 7 "70%" 8 "80%" ;
VAL_ 167 FWAwarning 0 "no failure/Init/Default" 1 "Warnig level 1 for high Temp. of Brake system" 2 "Warnig level 2 for high Temp. of Brake system" 3 "Reserved" ;
VAL_ 167 BrkFlWarning 0 "BrakeFluid_Normal/Init/Default" 1 "BrakeFluid_Empty" 2 "BrakeFluid_Electric_error" 3 "Reserved " ;
VAL_ 167 IPBSts 0 "BBF_FullSys/Init/Default" 1 "BBF_DegradedPedalFeel" 2 "BBF_CircuitSperation " 3 "BBF_C1/2BoostOnly " 4 "HydBack w/ act / HydBack w/o act" 5 "Yellow Lamp On" ;
VAL_ 167 CSTSts 0 "CST is disabled/Init/Default" 1 "CST is Standby" 2 "CST is Active" 3 "CST is Failure" ;
VAL_ 1002 PhoneRmdrReq2 1 "Alarm On" 0 "No request" ;
VAL_ 1002 FODAlrm2 1 "Alarm On" 0 "No request" ;
VAL_ 1002 WPCChrgSts2 0 "Off" 1 "Standby" 2 "Charging" 3 "Fully Charged" 4 "Error" ;
VAL_ 959 WPCEnblReq2 0 "No Request" 1 "On" 2 "Off" ;
VAL_ 959 FuelCsumpUnitSetReq 0 "No Request " 1 "km/L " 2 "L/100km " 3 "Reserved" ;
VAL_ 959 DistractionMoniSwReq 0 "No Request" 1 "ON" 2 "OFF" 3 "Reserved" ;
VAL_ 959 ATSMMReq 0 "No Request" 1 "Function OFF" 2 "Function ON" 3 "Reserved" ;
VAL_ 959 EPSMLReq 0 "No Request" 1 "Function OFF" 2 "Function ON" 3 "Reserved" ;
VAL_ 959 VehUnLckFormSet_VAN 0 "No Request(Default)" 1 "Unlock All" 2 "Unlock Driver Door Only" 3 "Unlock Passenger Compartment Door Only" ;
VAL_ 959 DMSSWReq 0 "No Request" 1 "ON" 2 "OFF" 3 "Reserved" ;
VAL_ 959 FatigueMoniSwReq 0 "No Request" 1 "ON" 2 "OFF" 3 "Reserved" ;
VAL_ 705 iTurnFnSwReq 0 "No Request" 1 "Function ON" 2 "Function OFF" 3 "Reserved" ;
VAL_ 705 CSTFnSwReq 0 "No Request" 1 "CST Function ON" 2 "CST Function OFF" 3 "Reserved" ;
VAL_ 942 FICMDsChrgVolReq 0 "default" 1 "230V" 2 "110V" 3 "Reserved" ;
VAL_ 942 FICMDsChrgFreqReq 0 "default" 1 "50Hz" 2 "60Hz" 3 "Reserved" ;
VAL_ 843 CldrMthCrt_HMISET 12 "December" 11 "November" 10 "October" 9 "September" 8 "August" 7 "July" 6 "June" 5 "May" 4 "April" 3 "March" 2 "February" 1 "January" 0 "Unknown" ;
VAL_ 843 DayCrtV_HMISET 1 "Valid" 0 "Invalid" ;
VAL_ 843 CldCrtV_HMISET 1 "Valid" 0 "Invalid" ;
VAL_ 843 ZnStReq_HMISET 0 "No Request" 1 "UTC +14" 2 "UTC +13:45" 3 "UTC +13" 4 "UTC +12:45" 5 "UTC +12" 6 "UTC +11" 7 "UTC +10:30" 8 "UTC +10" 9 "UTC +9:30" 10 "UTC +9" 11 "UTC +8:45" 12 "UTC +8:30" 13 "UTC +8" 14 "UTC +7" 15 "UTC +6:30" 16 "UTC +6" 17 "UTC +5:45" 18 "UTC +5:30" 19 "UTC +5" 20 "UTC +4:30" 21 "UTC +4" 22 "UTC +3:30" 23 "UTC +3" 24 "UTC +2" 25 "UTC +1" 26 "UTC +0" 27 "UTC -1" 28 "UTC -2" 29 "UTC -2:30" 30 "UTC -3" 32 "UTC -3:30" 33 "UTC -4" 34 "UTC -5" 35 "UTC -6" 36 "UTC -7" 37 "UTC -8" 38 "UTC -9" 39 "UTC -9:30" 40 "UTC -10" 41 "UTC -11" ;
